VERSION ""

NS_ :

BS_:

BU_: Dummy_FO TestTool_FO LRR_FO RFSRR_FO LFSRR_FO RSRR_FO VIS_FO EOCM_F_FO

BO_ 849 F_Vision_Lane_Sense2: 7 VIS_FO
 SG_ LnSnsBurstID : 2|2@0+ (1,0) [0|3] ""  EOCM_F_FO
 SG_ LaneSensRawLatVel : 15|16@0- (6.1035E-005,0) [-1.99999488|1.999933845] "m/s"  EOCM_F_FO
 SG_ LnSnsCrvtGrdntRt : 31|16@0- (5.96E-008,0) [-0.0019529728|0.0019529132] "1/rad/s"  EOCM_F_FO
 SG_ LnSnsLnCrvtrRghtV : 0|1@0+ (1,0) [0|1] ""  EOCM_F_FO
 SG_ LnSnsLnCrvtrRght : 47|16@0- (9.53E-007,0) [-0.031227904|0.031226951] "1/m"  EOCM_F_FO

BO_ 1184 R_SRR_Object_Header: 8 RSRR_FO
 SG_ RSRRNumValidTargets : 14|4@0+ (1,0) [0|15] ""  EOCM_F_FO
 SG_ RSrrRollingCnt : 1|2@0+ (1,0) [0|3] ""  EOCM_F_FO
 SG_ RSRRModeCmdFdbk : 4|3@0+ (1,0) [0|7] ""  EOCM_F_FO
 SG_ RSrrTimeStampV : 15|1@0+ (1,0) [0|1] ""  EOCM_F_FO
 SG_ RSrrTimeStamp : 10|11@0+ (1,0) [0|2047] "ms"  EOCM_F_FO
 SG_ RSrrBurstChecksum : 55|16@0+ (1,0) [0|65535] ""  EOCM_F_FO
 SG_ RSRRSnstvFltPrsntInt : 24|1@0+ (1,0) [0|1] ""  EOCM_F_FO
 SG_ RSRRPlntAlgnInProc : 37|1@0+ (1,0) [0|1] ""  EOCM_F_FO
 SG_ RSRRMsalgnYawRt : 47|1@0+ (1,0) [0|1] ""  EOCM_F_FO
 SG_ RSRRMsalgnYawLt : 46|1@0+ (1,0) [0|1] ""  EOCM_F_FO
 SG_ RSRRMsalgnRllRt : 35|1@0+ (1,0) [0|1] ""  EOCM_F_FO
 SG_ RSRRMsalgnRllLt : 34|1@0+ (1,0) [0|1] ""  EOCM_F_FO
 SG_ RSRRMsalgnPtchUp : 32|1@0+ (1,0) [0|1] ""  EOCM_F_FO
 SG_ RSRRMsalgnPtchDn : 33|1@0+ (1,0) [0|1] ""  EOCM_F_FO
 SG_ RSRRInitDiagCmplt : 40|1@0+ (1,0) [0|1] ""  EOCM_F_FO
 SG_ RSRRHWFltPrsntInt : 25|1@0+ (1,0) [0|1] ""  EOCM_F_FO
 SG_ RSRRExtIntrfrnc : 36|1@0+ (1,0) [0|1] ""  EOCM_F_FO
 SG_ RSRRDiagSpare : 30|1@0+ (1,0) [0|1] ""  EOCM_F_FO
 SG_ RSRRCANSgnlSpvFld : 29|1@0+ (1,0) [0|1] ""  EOCM_F_FO
 SG_ RSRRCANRxErr : 28|1@0+ (1,0) [0|1] ""  EOCM_F_FO
 SG_ RSRRCANIDAddrsUnsbl : 27|1@0+ (1,0) [0|1] ""  EOCM_F_FO
 SG_ RSRRAntTngFltPrsnt : 26|1@0+ (1,0) [0|1] ""  EOCM_F_FO
 SG_ RSRRAmbTmpOutRngLw : 42|1@0+ (1,0) [0|1] ""  EOCM_F_FO
 SG_ RSRRAmbTmpOutRngHi : 41|1@0+ (1,0) [0|1] ""  EOCM_F_FO
 SG_ RSRRAlgnFltPrsnt : 39|1@0+ (1,0) [0|1] ""  EOCM_F_FO
 SG_ RSRRVltgOutRngLo : 44|1@0+ (1,0) [0|1] ""  EOCM_F_FO
 SG_ RSRRVltgOutRngHi : 43|1@0+ (1,0) [0|1] ""  EOCM_F_FO
 SG_ RSRRSvcAlgnInPrcs : 38|1@0+ (1,0) [0|1] ""  EOCM_F_FO
 SG_ RSRRSnsrBlckd : 45|1@0+ (1,0) [0|1] ""  EOCM_F_FO

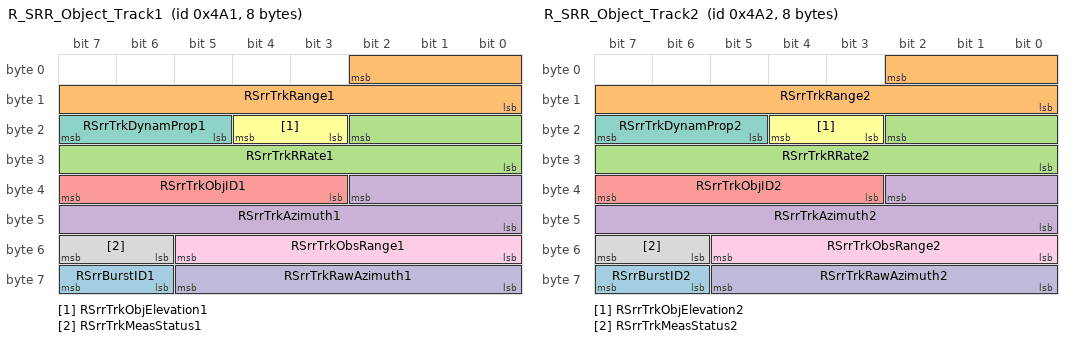
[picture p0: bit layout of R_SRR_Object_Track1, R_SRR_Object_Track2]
BO_ 1185 R_SRR_Object_Track1: 8 RSRR_FO
 SG_ RSrrBurstID1 : 63|2@0+ (1,0) [0|3] ""  EOCM_F_FO
 SG_ RSrrTrkRange1 : 2|11@0+ (0.02,0) [0|40.94] "m"  EOCM_F_FO
 SG_ RSrrTrkRRate1 : 18|11@0- (0.125,0) [-128|127.875] "m/s"  EOCM_F_FO
 SG_ RSrrTrkAzimuth1 : 34|11@0- (0.125,0) [-128|127.875] "deg"  EOCM_F_FO
 SG_ RSrrTrkObjID1 : 39|5@0+ (1,0) [0|31] ""  EOCM_F_FO
 SG_ RSrrTrkObjElevation1 : 20|2@0+ (1,0) [0|0] ""  EOCM_F_FO
 SG_ RSrrTrkDynamProp1 : 23|3@0+ (1,0) [0|0] ""  EOCM_F_FO
 SG_ RSrrTrkMeasStatus1 : 55|2@0+ (1,0) [0|0] ""  EOCM_F_FO
 SG_ RSrrTrkObsRange1 : 53|6@0- (0.02,0) [-0.64|0.62] "m"  EOCM_F_FO
 SG_ RSrrTrkRawAzimuth1 : 61|6@0- (1,0) [-32|31] "deg"  EOCM_F_FO

BO_ 1186 R_SRR_Object_Track2: 8 RSRR_FO
 SG_ RSrrBurstID2 : 63|2@0+ (1,0) [0|3] ""  EOCM_F_FO
 SG_ RSrrTrkRange2 : 2|11@0+ (0.02,0) [0|40.94] "m"  EOCM_F_FO
 SG_ RSrrTrkRRate2 : 18|11@0- (0.125,0) [-128|127.875] "m/s"  EOCM_F_FO
 SG_ RSrrTrkAzimuth2 : 34|11@0- (0.125,0) [-128|127.875] "deg"  EOCM_F_FO
 SG_ RSrrTrkObjID2 : 39|5@0+ (1,0) [0|31] ""  EOCM_F_FO
 SG_ RSrrTrkObjElevation2 : 20|2@0+ (1,0) [0|0] ""  EOCM_F_FO
 SG_ RSrrTrkDynamProp2 : 23|3@0+ (1,0) [0|0] ""  EOCM_F_FO
 SG_ RSrrTrkMeasStatus2 : 55|2@0+ (1,0) [0|0] ""  EOCM_F_FO
 SG_ RSrrTrkObsRange2 : 53|6@0- (0.02,0) [-0.64|0.62] "m"  EOCM_F_FO
 SG_ RSrrTrkRawAzimuth2 : 61|6@0- (1,0) [-32|31] "deg"  EOCM_F_FO

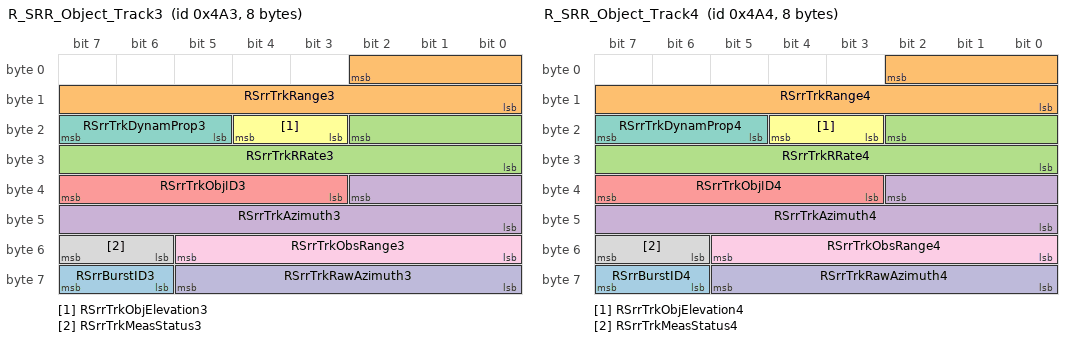
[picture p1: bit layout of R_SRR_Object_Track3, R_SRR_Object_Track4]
BO_ 1187 R_SRR_Object_Track3: 8 RSRR_FO
 SG_ RSrrBurstID3 : 63|2@0+ (1,0) [0|3] ""  EOCM_F_FO
 SG_ RSrrTrkRange3 : 2|11@0+ (0.02,0) [0|40.94] "m"  EOCM_F_FO
 SG_ RSrrTrkRRate3 : 18|11@0- (0.125,0) [-128|127.875] "m/s"  EOCM_F_FO
 SG_ RSrrTrkAzimuth3 : 34|11@0- (0.125,0) [-128|127.875] "deg"  EOCM_F_FO
 SG_ RSrrTrkObjID3 : 39|5@0+ (1,0) [0|31] ""  EOCM_F_FO
 SG_ RSrrTrkObjElevation3 : 20|2@0+ (1,0) [0|0] ""  EOCM_F_FO
 SG_ RSrrTrkDynamProp3 : 23|3@0+ (1,0) [0|0] ""  EOCM_F_FO
 SG_ RSrrTrkMeasStatus3 : 55|2@0+ (1,0) [0|0] ""  EOCM_F_FO
 SG_ RSrrTrkObsRange3 : 53|6@0- (0.02,0) [-0.64|0.62] "m"  EOCM_F_FO
 SG_ RSrrTrkRawAzimuth3 : 61|6@0- (1,0) [-32|31] "deg"  EOCM_F_FO

BO_ 1188 R_SRR_Object_Track4: 8 RSRR_FO
 SG_ RSrrBurstID4 : 63|2@0+ (1,0) [0|3] ""  EOCM_F_FO
 SG_ RSrrTrkRange4 : 2|11@0+ (0.02,0) [0|40.94] "m"  EOCM_F_FO
 SG_ RSrrTrkRRate4 : 18|11@0- (0.125,0) [-128|127.875] "m/s"  EOCM_F_FO
 SG_ RSrrTrkAzimuth4 : 34|11@0- (0.125,0) [-128|127.875] "deg"  EOCM_F_FO
 SG_ RSrrTrkObjID4 : 39|5@0+ (1,0) [0|31] ""  EOCM_F_FO
 SG_ RSrrTrkObjElevation4 : 20|2@0+ (1,0) [0|0] ""  EOCM_F_FO
 SG_ RSrrTrkDynamProp4 : 23|3@0+ (1,0) [0|0] ""  EOCM_F_FO
 SG_ RSrrTrkMeasStatus4 : 55|2@0+ (1,0) [0|0] ""  EOCM_F_FO
 SG_ RSrrTrkObsRange4 : 53|6@0- (0.02,0) [-0.64|0.62] "m"  EOCM_F_FO
 SG_ RSrrTrkRawAzimuth4 : 61|6@0- (1,0) [-32|31] "deg"  EOCM_F_FO

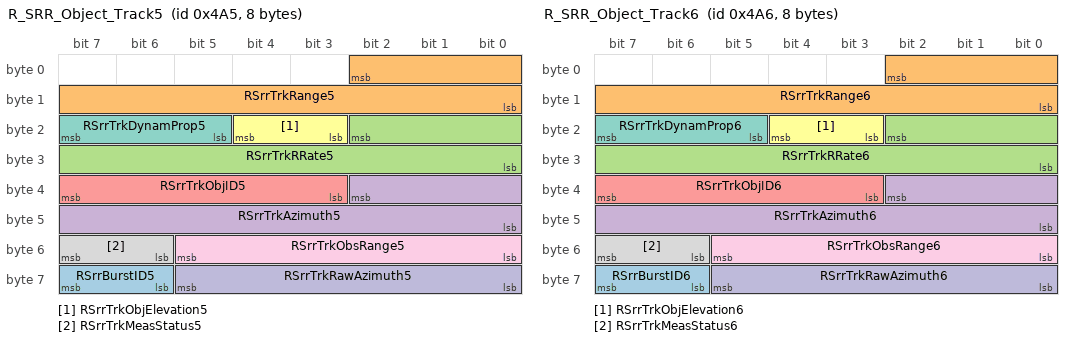
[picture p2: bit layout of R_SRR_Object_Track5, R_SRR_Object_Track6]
BO_ 1189 R_SRR_Object_Track5: 8 RSRR_FO
 SG_ RSrrBurstID5 : 63|2@0+ (1,0) [0|3] ""  EOCM_F_FO
 SG_ RSrrTrkRange5 : 2|11@0+ (0.02,0) [0|40.94] "m"  EOCM_F_FO
 SG_ RSrrTrkRRate5 : 18|11@0- (0.125,0) [-128|127.875] "m/s"  EOCM_F_FO
 SG_ RSrrTrkAzimuth5 : 34|11@0- (0.125,0) [-128|127.875] "deg"  EOCM_F_FO
 SG_ RSrrTrkObjID5 : 39|5@0+ (1,0) [0|31] ""  EOCM_F_FO
 SG_ RSrrTrkObjElevation5 : 20|2@0+ (1,0) [0|0] ""  EOCM_F_FO
 SG_ RSrrTrkDynamProp5 : 23|3@0+ (1,0) [0|0] ""  EOCM_F_FO
 SG_ RSrrTrkMeasStatus5 : 55|2@0+ (1,0) [0|0] ""  EOCM_F_FO
 SG_ RSrrTrkObsRange5 : 53|6@0- (0.02,0) [-0.64|0.62] "m"  EOCM_F_FO
 SG_ RSrrTrkRawAzimuth5 : 61|6@0- (1,0) [-32|31] "deg"  EOCM_F_FO

BO_ 1190 R_SRR_Object_Track6: 8 RSRR_FO
 SG_ RSrrBurstID6 : 63|2@0+ (1,0) [0|3] ""  EOCM_F_FO
 SG_ RSrrTrkRange6 : 2|11@0+ (0.02,0) [0|40.94] "m"  EOCM_F_FO
 SG_ RSrrTrkRRate6 : 18|11@0- (0.125,0) [-128|127.875] "m/s"  EOCM_F_FO
 SG_ RSrrTrkAzimuth6 : 34|11@0- (0.125,0) [-128|127.875] "deg"  EOCM_F_FO
 SG_ RSrrTrkObjID6 : 39|5@0+ (1,0) [0|31] ""  EOCM_F_FO
 SG_ RSrrTrkObjElevation6 : 20|2@0+ (1,0) [0|0] ""  EOCM_F_FO
 SG_ RSrrTrkDynamProp6 : 23|3@0+ (1,0) [0|0] ""  EOCM_F_FO
 SG_ RSrrTrkMeasStatus6 : 55|2@0+ (1,0) [0|0] ""  EOCM_F_FO
 SG_ RSrrTrkObsRange6 : 53|6@0- (0.02,0) [-0.64|0.62] "m"  EOCM_F_FO
 SG_ RSrrTrkRawAzimuth6 : 61|6@0- (1,0) [-32|31] "deg"  EOCM_F_FO

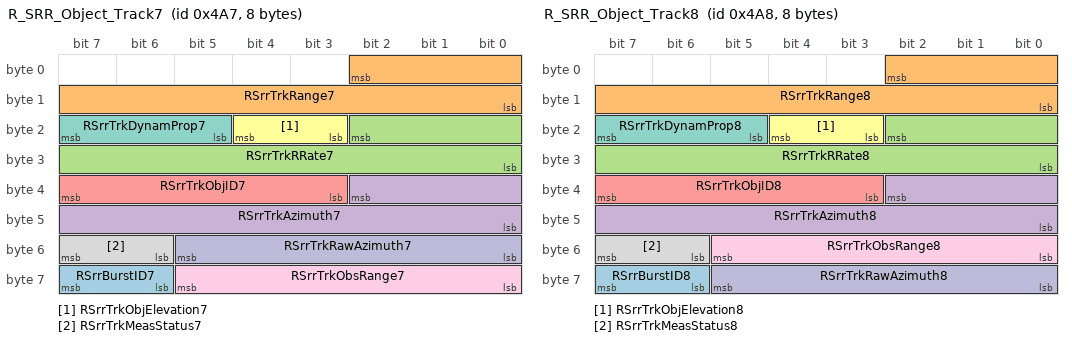
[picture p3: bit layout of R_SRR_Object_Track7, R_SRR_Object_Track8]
BO_ 1191 R_SRR_Object_Track7: 8 RSRR_FO
 SG_ RSrrBurstID7 : 63|2@0+ (1,0) [0|3] ""  EOCM_F_FO
 SG_ RSrrTrkRange7 : 2|11@0+ (0.02,0) [0|40.94] "m"  EOCM_F_FO
 SG_ RSrrTrkRRate7 : 18|11@0- (0.125,0) [-128|127.875] "m/s"  EOCM_F_FO
 SG_ RSrrTrkAzimuth7 : 34|11@0- (0.125,0) [-128|127.875] "deg"  EOCM_F_FO
 SG_ RSrrTrkObjID7 : 39|5@0+ (1,0) [0|31] ""  EOCM_F_FO
 SG_ RSrrTrkObjElevation7 : 20|2@0+ (1,0) [0|0] ""  EOCM_F_FO
 SG_ RSrrTrkDynamProp7 : 23|3@0+ (1,0) [0|0] ""  EOCM_F_FO
 SG_ RSrrTrkMeasStatus7 : 55|2@0+ (1,0) [0|0] ""  EOCM_F_FO
 SG_ RSrrTrkObsRange7 : 61|6@0- (0.02,0) [-0.64|0.62] "m"  EOCM_F_FO
 SG_ RSrrTrkRawAzimuth7 : 53|6@0- (1,0) [-32|31] "deg"  EOCM_F_FO

BO_ 1192 R_SRR_Object_Track8: 8 RSRR_FO
 SG_ RSrrBurstID8 : 63|2@0+ (1,0) [0|3] ""  EOCM_F_FO
 SG_ RSrrTrkRange8 : 2|11@0+ (0.02,0) [0|40.94] "m"  EOCM_F_FO
 SG_ RSrrTrkRRate8 : 18|11@0- (0.125,0) [-128|127.875] "m/s"  EOCM_F_FO
 SG_ RSrrTrkAzimuth8 : 34|11@0- (0.125,0) [-128|127.875] "deg"  EOCM_F_FO
 SG_ RSrrTrkObjID8 : 39|5@0+ (1,0) [0|31] ""  EOCM_F_FO
 SG_ RSrrTrkObjElevation8 : 20|2@0+ (1,0) [0|0] ""  EOCM_F_FO
 SG_ RSrrTrkDynamProp8 : 23|3@0+ (1,0) [0|0] ""  EOCM_F_FO
 SG_ RSrrTrkMeasStatus8 : 55|2@0+ (1,0) [0|0] ""  EOCM_F_FO
 SG_ RSrrTrkObsRange8 : 53|6@0- (0.02,0) [-0.64|0.62] "m"  EOCM_F_FO
 SG_ RSrrTrkRawAzimuth8 : 61|6@0- (1,0) [-32|31] "deg"  EOCM_F_FO

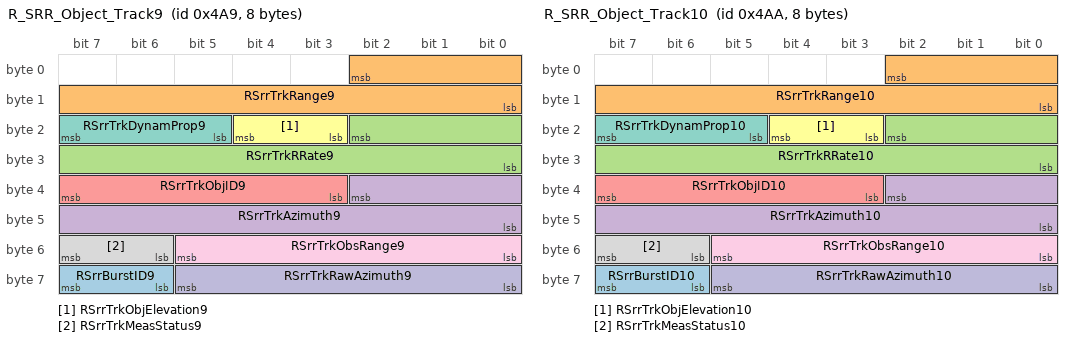
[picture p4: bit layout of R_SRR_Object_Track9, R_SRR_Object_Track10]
BO_ 1193 R_SRR_Object_Track9: 8 RSRR_FO
 SG_ RSrrBurstID9 : 63|2@0+ (1,0) [0|3] ""  EOCM_F_FO
 SG_ RSrrTrkRange9 : 2|11@0+ (0.02,0) [0|40.94] "m"  EOCM_F_FO
 SG_ RSrrTrkRRate9 : 18|11@0- (0.125,0) [-128|127.875] "m/s"  EOCM_F_FO
 SG_ RSrrTrkAzimuth9 : 34|11@0- (0.125,0) [-128|127.875] "deg"  EOCM_F_FO
 SG_ RSrrTrkObjID9 : 39|5@0+ (1,0) [0|31] ""  EOCM_F_FO
 SG_ RSrrTrkObjElevation9 : 20|2@0+ (1,0) [0|0] ""  EOCM_F_FO
 SG_ RSrrTrkDynamProp9 : 23|3@0+ (1,0) [0|0] ""  EOCM_F_FO
 SG_ RSrrTrkMeasStatus9 : 55|2@0+ (1,0) [0|0] ""  EOCM_F_FO
 SG_ RSrrTrkObsRange9 : 53|6@0- (0.02,0) [-0.64|0.62] "m"  EOCM_F_FO
 SG_ RSrrTrkRawAzimuth9 : 61|6@0- (1,0) [-32|31] "deg"  EOCM_F_FO

BO_ 1194 R_SRR_Object_Track10: 8 RSRR_FO
 SG_ RSrrBurstID10 : 63|2@0+ (1,0) [0|3] ""  EOCM_F_FO
 SG_ RSrrTrkRange10 : 2|11@0+ (0.02,0) [0|40.94] "m"  EOCM_F_FO
 SG_ RSrrTrkRRate10 : 18|11@0- (0.125,0) [-128|127.875] "m/s"  EOCM_F_FO
 SG_ RSrrTrkAzimuth10 : 34|11@0- (0.125,0) [-128|127.875] "deg"  EOCM_F_FO
 SG_ RSrrTrkObjID10 : 39|5@0+ (1,0) [0|31] ""  EOCM_F_FO
 SG_ RSrrTrkObjElevation10 : 20|2@0+ (1,0) [0|0] ""  EOCM_F_FO
 SG_ RSrrTrkDynamProp10 : 23|3@0+ (1,0) [0|0] ""  EOCM_F_FO
 SG_ RSrrTrkMeasStatus10 : 55|2@0+ (1,0) [0|0] ""  EOCM_F_FO
 SG_ RSrrTrkObsRange10 : 53|6@0- (0.02,0) [-0.64|0.62] "m"  EOCM_F_FO
 SG_ RSrrTrkRawAzimuth10 : 61|6@0- (1,0) [-32|31] "deg"  EOCM_F_FO

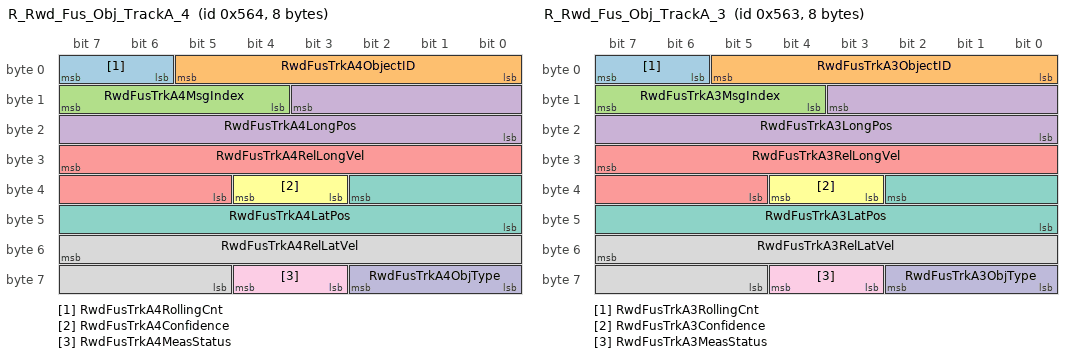
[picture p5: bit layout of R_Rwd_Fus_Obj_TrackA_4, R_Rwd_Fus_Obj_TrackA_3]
BO_ 1380 R_Rwd_Fus_Obj_TrackA_4: 8 EOCM_F_FO
 SG_ RwdFusTrkA4RollingCnt : 7|2@0+ (1,0) [0|3] ""  Dummy_FO
 SG_ RwdFusTrkA4ObjectID : 5|6@0+ (1,0) [0|63] ""  Dummy_FO
 SG_ RwdFusTrkA4MsgIndex : 15|4@0+ (1,0) [0|15] ""  Dummy_FO
 SG_ RwdFusTrkA4LongPos : 11|12@0- (0.125,0) [-256|255.875] "m"  Dummy_FO
 SG_ RwdFusTrkA4RelLongVel : 31|11@0- (0.125,0) [-128|127.875] "m/s"  Dummy_FO
 SG_ RwdFusTrkA4Confidence : 36|2@0+ (1,0) [0|3] ""  Dummy_FO
 SG_ RwdFusTrkA4LatPos : 34|11@0- (0.125,0) [-128|127.875] "m"  Dummy_FO
 SG_ RwdFusTrkA4RelLatVel : 55|11@0- (0.125,0) [-128|127.875] "m/s"  Dummy_FO
 SG_ RwdFusTrkA4MeasStatus : 60|2@0+ (1,0) [0|3] ""  Dummy_FO
 SG_ RwdFusTrkA4ObjType : 58|3@0+ (1,0) [0|7] ""  Dummy_FO

BO_ 1379 R_Rwd_Fus_Obj_TrackA_3: 8 EOCM_F_FO
 SG_ RwdFusTrkA3RollingCnt : 7|2@0+ (1,0) [0|3] ""  Dummy_FO
 SG_ RwdFusTrkA3ObjectID : 5|6@0+ (1,0) [0|63] ""  Dummy_FO
 SG_ RwdFusTrkA3MsgIndex : 15|4@0+ (1,0) [0|15] ""  Dummy_FO
 SG_ RwdFusTrkA3LongPos : 11|12@0- (0.125,0) [-256|255.875] "m"  Dummy_FO
 SG_ RwdFusTrkA3RelLongVel : 31|11@0- (0.125,0) [-128|127.875] "m/s"  Dummy_FO
 SG_ RwdFusTrkA3Confidence : 36|2@0+ (1,0) [0|3] ""  Dummy_FO
 SG_ RwdFusTrkA3LatPos : 34|11@0- (0.125,0) [-128|127.875] "m"  Dummy_FO
 SG_ RwdFusTrkA3RelLatVel : 55|11@0- (0.125,0) [-128|127.875] "m/s"  Dummy_FO
 SG_ RwdFusTrkA3MeasStatus : 60|2@0+ (1,0) [0|3] ""  Dummy_FO
 SG_ RwdFusTrkA3ObjType : 58|3@0+ (1,0) [0|7] ""  Dummy_FO

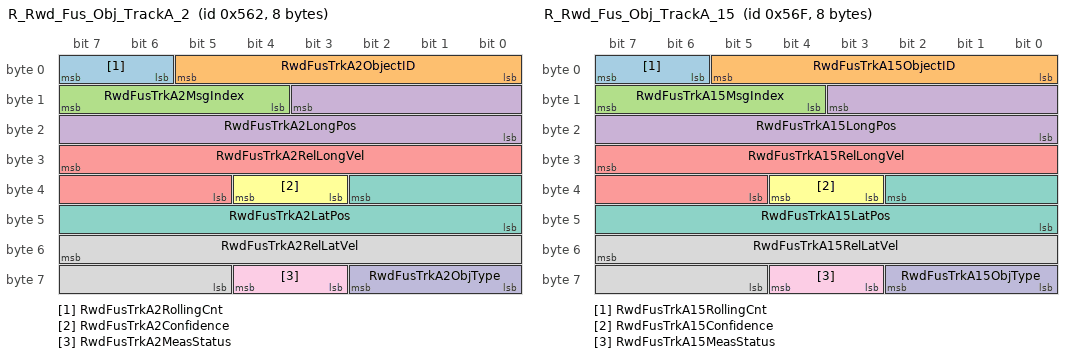
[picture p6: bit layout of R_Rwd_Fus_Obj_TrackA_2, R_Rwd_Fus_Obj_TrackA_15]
BO_ 1378 R_Rwd_Fus_Obj_TrackA_2: 8 EOCM_F_FO
 SG_ RwdFusTrkA2RollingCnt : 7|2@0+ (1,0) [0|3] ""  Dummy_FO
 SG_ RwdFusTrkA2ObjectID : 5|6@0+ (1,0) [0|63] ""  Dummy_FO
 SG_ RwdFusTrkA2MsgIndex : 15|4@0+ (1,0) [0|15] ""  Dummy_FO
 SG_ RwdFusTrkA2LongPos : 11|12@0- (0.125,0) [-256|255.875] "m"  Dummy_FO
 SG_ RwdFusTrkA2RelLongVel : 31|11@0- (0.125,0) [-128|127.875] "m/s"  Dummy_FO
 SG_ RwdFusTrkA2Confidence : 36|2@0+ (1,0) [0|3] ""  Dummy_FO
 SG_ RwdFusTrkA2LatPos : 34|11@0- (0.125,0) [-128|127.875] "m"  Dummy_FO
 SG_ RwdFusTrkA2RelLatVel : 55|11@0- (0.125,0) [-128|127.875] "m/s"  Dummy_FO
 SG_ RwdFusTrkA2MeasStatus : 60|2@0+ (1,0) [0|3] ""  Dummy_FO
 SG_ RwdFusTrkA2ObjType : 58|3@0+ (1,0) [0|7] ""  Dummy_FO

BO_ 1391 R_Rwd_Fus_Obj_TrackA_15: 8 EOCM_F_FO
 SG_ RwdFusTrkA15RollingCnt : 7|2@0+ (1,0) [0|3] ""  Dummy_FO
 SG_ RwdFusTrkA15ObjectID : 5|6@0+ (1,0) [0|63] ""  Dummy_FO
 SG_ RwdFusTrkA15MsgIndex : 15|4@0+ (1,0) [0|15] ""  Dummy_FO
 SG_ RwdFusTrkA15LongPos : 11|12@0- (0.125,0) [-256|255.875] "m"  Dummy_FO
 SG_ RwdFusTrkA15RelLongVel : 31|11@0- (0.125,0) [-128|127.875] "m/s"  Dummy_FO
 SG_ RwdFusTrkA15Confidence : 36|2@0+ (1,0) [0|3] ""  Dummy_FO
 SG_ RwdFusTrkA15LatPos : 34|11@0- (0.125,0) [-128|127.875] "m"  Dummy_FO
 SG_ RwdFusTrkA15RelLatVel : 55|11@0- (0.125,0) [-128|127.875] "m/s"  Dummy_FO
 SG_ RwdFusTrkA15MeasStatus : 60|2@0+ (1,0) [0|3] ""  Dummy_FO
 SG_ RwdFusTrkA15ObjType : 58|3@0+ (1,0) [0|7] ""  Dummy_FO

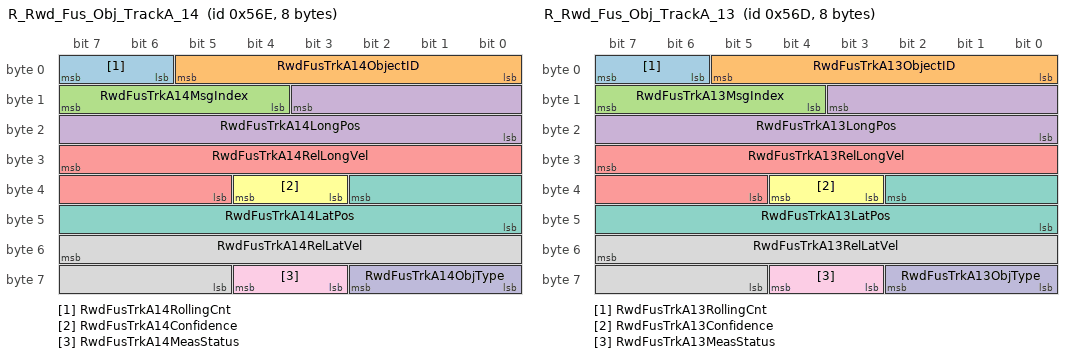
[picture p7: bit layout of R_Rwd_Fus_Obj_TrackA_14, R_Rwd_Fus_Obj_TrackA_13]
BO_ 1390 R_Rwd_Fus_Obj_TrackA_14: 8 EOCM_F_FO
 SG_ RwdFusTrkA14RollingCnt : 7|2@0+ (1,0) [0|3] ""  Dummy_FO
 SG_ RwdFusTrkA14ObjectID : 5|6@0+ (1,0) [0|63] ""  Dummy_FO
 SG_ RwdFusTrkA14MsgIndex : 15|4@0+ (1,0) [0|15] ""  Dummy_FO
 SG_ RwdFusTrkA14LongPos : 11|12@0- (0.125,0) [-256|255.875] "m"  Dummy_FO
 SG_ RwdFusTrkA14RelLongVel : 31|11@0- (0.125,0) [-128|127.875] "m/s"  Dummy_FO
 SG_ RwdFusTrkA14Confidence : 36|2@0+ (1,0) [0|3] ""  Dummy_FO
 SG_ RwdFusTrkA14LatPos : 34|11@0- (0.125,0) [-128|127.875] "m"  Dummy_FO
 SG_ RwdFusTrkA14RelLatVel : 55|11@0- (0.125,0) [-128|127.875] "m/s"  Dummy_FO
 SG_ RwdFusTrkA14MeasStatus : 60|2@0+ (1,0) [0|3] ""  Dummy_FO
 SG_ RwdFusTrkA14ObjType : 58|3@0+ (1,0) [0|7] ""  Dummy_FO

BO_ 1389 R_Rwd_Fus_Obj_TrackA_13: 8 EOCM_F_FO
 SG_ RwdFusTrkA13RollingCnt : 7|2@0+ (1,0) [0|3] ""  Dummy_FO
 SG_ RwdFusTrkA13ObjectID : 5|6@0+ (1,0) [0|63] ""  Dummy_FO
 SG_ RwdFusTrkA13MsgIndex : 15|4@0+ (1,0) [0|15] ""  Dummy_FO
 SG_ RwdFusTrkA13LongPos : 11|12@0- (0.125,0) [-256|255.875] "m"  Dummy_FO
 SG_ RwdFusTrkA13RelLongVel : 31|11@0- (0.125,0) [-128|127.875] "m/s"  Dummy_FO
 SG_ RwdFusTrkA13Confidence : 36|2@0+ (1,0) [0|3] ""  Dummy_FO
 SG_ RwdFusTrkA13LatPos : 34|11@0- (0.125,0) [-128|127.875] "m"  Dummy_FO
 SG_ RwdFusTrkA13RelLatVel : 55|11@0- (0.125,0) [-128|127.875] "m/s"  Dummy_FO
 SG_ RwdFusTrkA13MeasStatus : 60|2@0+ (1,0) [0|3] ""  Dummy_FO
 SG_ RwdFusTrkA13ObjType : 58|3@0+ (1,0) [0|7] ""  Dummy_FO

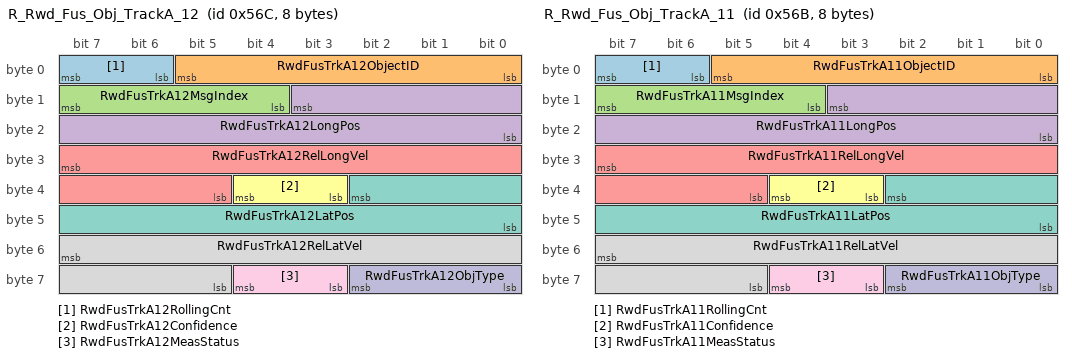
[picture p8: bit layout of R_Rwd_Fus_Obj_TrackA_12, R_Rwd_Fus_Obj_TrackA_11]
BO_ 1388 R_Rwd_Fus_Obj_TrackA_12: 8 EOCM_F_FO
 SG_ RwdFusTrkA12RollingCnt : 7|2@0+ (1,0) [0|3] ""  Dummy_FO
 SG_ RwdFusTrkA12ObjectID : 5|6@0+ (1,0) [0|63] ""  Dummy_FO
 SG_ RwdFusTrkA12MsgIndex : 15|4@0+ (1,0) [0|15] ""  Dummy_FO
 SG_ RwdFusTrkA12LongPos : 11|12@0- (0.125,0) [-256|255.875] "m"  Dummy_FO
 SG_ RwdFusTrkA12RelLongVel : 31|11@0- (0.125,0) [-128|127.875] "m/s"  Dummy_FO
 SG_ RwdFusTrkA12Confidence : 36|2@0+ (1,0) [0|3] ""  Dummy_FO
 SG_ RwdFusTrkA12LatPos : 34|11@0- (0.125,0) [-128|127.875] "m"  Dummy_FO
 SG_ RwdFusTrkA12RelLatVel : 55|11@0- (0.125,0) [-128|127.875] "m/s"  Dummy_FO
 SG_ RwdFusTrkA12MeasStatus : 60|2@0+ (1,0) [0|3] ""  Dummy_FO
 SG_ RwdFusTrkA12ObjType : 58|3@0+ (1,0) [0|7] ""  Dummy_FO

BO_ 1387 R_Rwd_Fus_Obj_TrackA_11: 8 EOCM_F_FO
 SG_ RwdFusTrkA11RollingCnt : 7|2@0+ (1,0) [0|3] ""  Dummy_FO
 SG_ RwdFusTrkA11ObjectID : 5|6@0+ (1,0) [0|63] ""  Dummy_FO
 SG_ RwdFusTrkA11MsgIndex : 15|4@0+ (1,0) [0|15] ""  Dummy_FO
 SG_ RwdFusTrkA11LongPos : 11|12@0- (0.125,0) [-256|255.875] "m"  Dummy_FO
 SG_ RwdFusTrkA11RelLongVel : 31|11@0- (0.125,0) [-128|127.875] "m/s"  Dummy_FO
 SG_ RwdFusTrkA11Confidence : 36|2@0+ (1,0) [0|3] ""  Dummy_FO
 SG_ RwdFusTrkA11LatPos : 34|11@0- (0.125,0) [-128|127.875] "m"  Dummy_FO
 SG_ RwdFusTrkA11RelLatVel : 55|11@0- (0.125,0) [-128|127.875] "m/s"  Dummy_FO
 SG_ RwdFusTrkA11MeasStatus : 60|2@0+ (1,0) [0|3] ""  Dummy_FO
 SG_ RwdFusTrkA11ObjType : 58|3@0+ (1,0) [0|7] ""  Dummy_FO

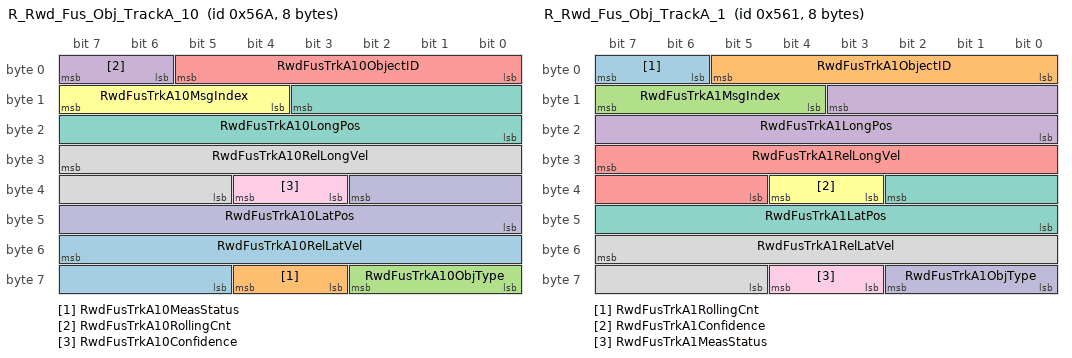
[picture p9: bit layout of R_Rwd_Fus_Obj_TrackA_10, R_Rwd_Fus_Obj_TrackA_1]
BO_ 1386 R_Rwd_Fus_Obj_TrackA_10: 8 EOCM_F_FO
 SG_ RwdFusTrkA10RelLatVel : 55|11@0- (0.125,0) [-128|127.875] "m/s"  Dummy_FO
 SG_ RwdFusTrkA10MeasStatus : 60|2@0+ (1,0) [0|3] ""  Dummy_FO
 SG_ RwdFusTrkA10ObjType : 58|3@0+ (1,0) [0|7] ""  Dummy_FO
 SG_ RwdFusTrkA10RollingCnt : 7|2@0+ (1,0) [0|3] ""  Dummy_FO
 SG_ RwdFusTrkA10ObjectID : 5|6@0+ (1,0) [0|63] ""  Dummy_FO
 SG_ RwdFusTrkA10MsgIndex : 15|4@0+ (1,0) [0|15] ""  Dummy_FO
 SG_ RwdFusTrkA10LongPos : 11|12@0- (0.125,0) [-256|255.875] "m"  Dummy_FO
 SG_ RwdFusTrkA10RelLongVel : 31|11@0- (0.125,0) [-128|127.875] "m/s"  Dummy_FO
 SG_ RwdFusTrkA10Confidence : 36|2@0+ (1,0) [0|3] ""  Dummy_FO
 SG_ RwdFusTrkA10LatPos : 34|11@0- (0.125,0) [-128|127.875] "m"  Dummy_FO

BO_ 1377 R_Rwd_Fus_Obj_TrackA_1: 8 EOCM_F_FO
 SG_ RwdFusTrkA1RollingCnt : 7|2@0+ (1,0) [0|3] ""  Dummy_FO
 SG_ RwdFusTrkA1ObjectID : 5|6@0+ (1,0) [0|63] ""  Dummy_FO
 SG_ RwdFusTrkA1MsgIndex : 15|4@0+ (1,0) [0|15] ""  Dummy_FO
 SG_ RwdFusTrkA1LongPos : 11|12@0- (0.125,0) [-256|255.875] "m"  Dummy_FO
 SG_ RwdFusTrkA1RelLongVel : 31|11@0- (0.125,0) [-128|127.875] "m/s"  Dummy_FO
 SG_ RwdFusTrkA1Confidence : 36|2@0+ (1,0) [0|3] ""  Dummy_FO
 SG_ RwdFusTrkA1LatPos : 34|11@0- (0.125,0) [-128|127.875] "m"  Dummy_FO
 SG_ RwdFusTrkA1RelLatVel : 55|11@0- (0.125,0) [-128|127.875] "m/s"  Dummy_FO
 SG_ RwdFusTrkA1MeasStatus : 60|2@0+ (1,0) [0|3] ""  Dummy_FO
 SG_ RwdFusTrkA1ObjType : 58|3@0+ (1,0) [0|7] ""  Dummy_FO

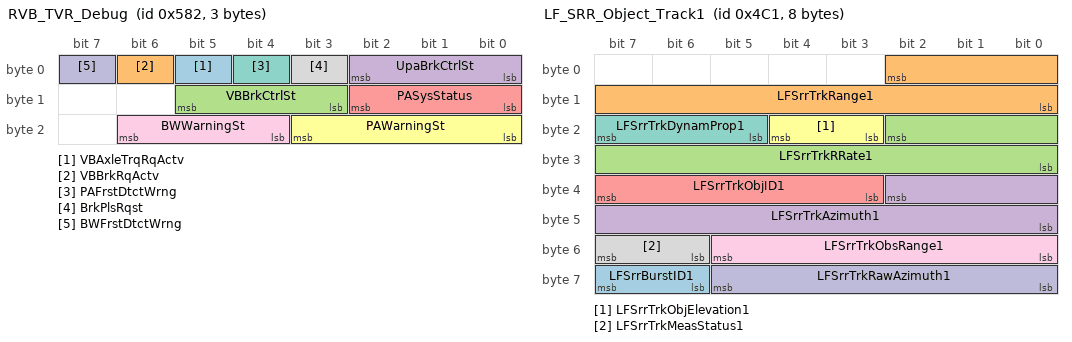
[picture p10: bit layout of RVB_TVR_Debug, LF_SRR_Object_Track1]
BO_ 1410 RVB_TVR_Debug: 3 EOCM_F_FO
 SG_ VBAxleTrqRqActv : 5|1@0+ (1,0) [0|1] ""  Dummy_FO
 SG_ VBBrkRqActv : 6|1@0+ (1,0) [0|1] ""  Dummy_FO
 SG_ VBBrkCtrlSt : 13|3@0+ (1,0) [0|0] ""  Dummy_FO
 SG_ UpaBrkCtrlSt : 2|3@0+ (1,0) [0|0] ""  Dummy_FO
 SG_ PASysStatus : 10|3@0+ (1,0) [0|0] ""  Dummy_FO
 SG_ PAWarningSt : 19|4@0+ (1,0) [0|0] ""  Dummy_FO
 SG_ PAFrstDtctWrng : 4|1@0+ (1,0) [0|1] ""  Dummy_FO
 SG_ BrkPlsRqst : 3|1@0+ (1,0) [0|1] ""  Dummy_FO
 SG_ BWWarningSt : 22|3@0+ (1,0) [0|0] ""  Dummy_FO
 SG_ BWFrstDtctWrng : 7|1@0+ (1,0) [0|1] ""  Dummy_FO

BO_ 1216 LF_SRR_Object_Header: 8 LFSRR_FO
 SG_ LFSRRNumValidTargets : 14|4@0+ (1,0) [0|15] ""  EOCM_F_FO
 SG_ LFSrrRollingCnt : 1|2@0+ (1,0) [0|3] ""  EOCM_F_FO
 SG_ LFSRRModeCmdFdbk : 4|3@0+ (1,0) [0|7] ""  EOCM_F_FO
 SG_ LFSrrTimeStampV : 15|1@0+ (1,0) [0|1] ""  EOCM_F_FO
 SG_ LFSrrTimeStamp : 10|11@0+ (1,0) [0|2047] "ms"  EOCM_F_FO
 SG_ LFSrrBurstChecksum : 55|16@0+ (1,0) [0|65535] ""  EOCM_F_FO
 SG_ LFSRRVltgOutRngLo : 44|1@0+ (1,0) [0|1] ""  EOCM_F_FO
 SG_ LFSRRVltgOutRngHi : 43|1@0+ (1,0) [0|1] ""  EOCM_F_FO
 SG_ LFSRRSvcAlgnInPrcs : 38|1@0+ (1,0) [0|1] ""  EOCM_F_FO
 SG_ LFSRRSnsrBlckd : 45|1@0+ (1,0) [0|1] ""  EOCM_F_FO
 SG_ LFSRRSnstvFltPrsntInt : 24|1@0+ (1,0) [0|1] ""  EOCM_F_FO
 SG_ LFSRRPlntAlgnInProc : 37|1@0+ (1,0) [0|1] ""  EOCM_F_FO
 SG_ LFSRRMsalgnYawRt : 47|1@0+ (1,0) [0|1] ""  EOCM_F_FO
 SG_ LFSRRMsalgnYawLt : 46|1@0+ (1,0) [0|1] ""  EOCM_F_FO
 SG_ LFSRRMsalgnRllRt : 35|1@0+ (1,0) [0|1] ""  EOCM_F_FO
 SG_ LFSRRMsalgnRllLt : 34|1@0+ (1,0) [0|1] ""  EOCM_F_FO
 SG_ LFSRRMsalgnPtchUp : 32|1@0+ (1,0) [0|1] ""  EOCM_F_FO
 SG_ LFSRRMsalgnPtchDn : 33|1@0+ (1,0) [0|1] ""  EOCM_F_FO
 SG_ LFSRRInitDiagCmplt : 40|1@0+ (1,0) [0|1] ""  EOCM_F_FO
 SG_ LFSRRHWFltPrsntInt : 25|1@0+ (1,0) [0|1] ""  EOCM_F_FO
 SG_ LFSRRExtIntrfrnc : 36|1@0+ (1,0) [0|1] ""  EOCM_F_FO
 SG_ LFSRRDiagSpare : 30|1@0+ (1,0) [0|1] ""  EOCM_F_FO
 SG_ LFSRRCANSgnlSpvFld : 29|1@0+ (1,0) [0|1] ""  EOCM_F_FO
 SG_ LFSRRCANRxErr : 28|1@0+ (1,0) [0|1] ""  EOCM_F_FO
 SG_ LFSRRCANIDAddrsUnsbl : 27|1@0+ (1,0) [0|1] ""  EOCM_F_FO
 SG_ LFSRRAntTngFltPrsnt : 26|1@0+ (1,0) [0|1] ""  EOCM_F_FO
 SG_ LFSRRAmbTmpOutRngLw : 42|1@0+ (1,0) [0|1] ""  EOCM_F_FO
 SG_ LFSRRAmbTmpOutRngHi : 41|1@0+ (1,0) [0|1] ""  EOCM_F_FO
 SG_ LFSRRAlgnFltPrsnt : 39|1@0+ (1,0) [0|1] ""  EOCM_F_FO

BO_ 1217 LF_SRR_Object_Track1: 8 LFSRR_FO
 SG_ LFSrrBurstID1 : 63|2@0+ (1,0) [0|3] ""  EOCM_F_FO
 SG_ LFSrrTrkRange1 : 2|11@0+ (0.02,0) [0|40.94] "m"  EOCM_F_FO
 SG_ LFSrrTrkRRate1 : 18|11@0- (0.125,0) [-128|127.875] "m/s"  EOCM_F_FO
 SG_ LFSrrTrkAzimuth1 : 34|11@0- (0.125,0) [-128|127.875] "deg"  EOCM_F_FO
 SG_ LFSrrTrkObjID1 : 39|5@0+ (1,0) [0|31] ""  EOCM_F_FO
 SG_ LFSrrTrkObjElevation1 : 20|2@0+ (1,0) [0|0] ""  EOCM_F_FO
 SG_ LFSrrTrkDynamProp1 : 23|3@0+ (1,0) [0|0] ""  EOCM_F_FO
 SG_ LFSrrTrkMeasStatus1 : 55|2@0+ (1,0) [0|0] ""  EOCM_F_FO
 SG_ LFSrrTrkObsRange1 : 53|6@0- (0.02,0) [-0.64|0.62] "m"  EOCM_F_FO
 SG_ LFSrrTrkRawAzimuth1 : 61|6@0- (1,0) [-32|31] "deg"  EOCM_F_FO

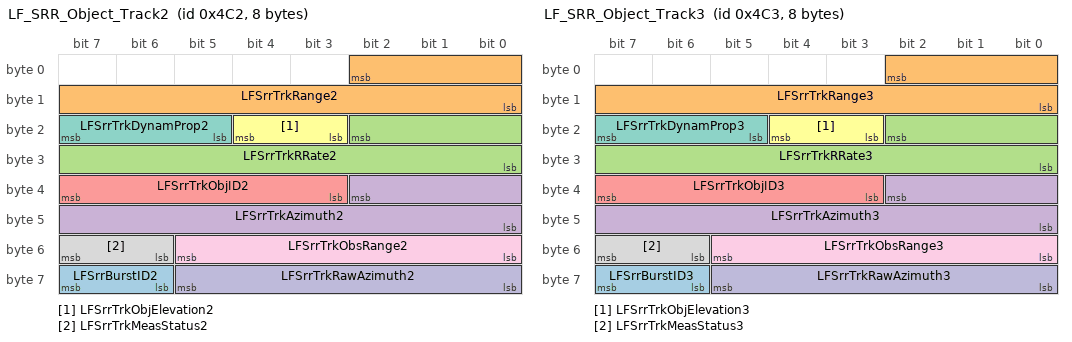
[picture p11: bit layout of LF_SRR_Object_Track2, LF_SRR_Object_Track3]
BO_ 1218 LF_SRR_Object_Track2: 8 LFSRR_FO
 SG_ LFSrrBurstID2 : 63|2@0+ (1,0) [0|3] ""  EOCM_F_FO
 SG_ LFSrrTrkRange2 : 2|11@0+ (0.02,0) [0|40.94] "m"  EOCM_F_FO
 SG_ LFSrrTrkRRate2 : 18|11@0- (0.125,0) [-128|127.875] "m/s"  EOCM_F_FO
 SG_ LFSrrTrkAzimuth2 : 34|11@0- (0.125,0) [-128|127.875] "deg"  EOCM_F_FO
 SG_ LFSrrTrkObjID2 : 39|5@0+ (1,0) [0|31] ""  EOCM_F_FO
 SG_ LFSrrTrkObjElevation2 : 20|2@0+ (1,0) [0|0] ""  EOCM_F_FO
 SG_ LFSrrTrkDynamProp2 : 23|3@0+ (1,0) [0|0] ""  EOCM_F_FO
 SG_ LFSrrTrkMeasStatus2 : 55|2@0+ (1,0) [0|0] ""  EOCM_F_FO
 SG_ LFSrrTrkObsRange2 : 53|6@0- (0.02,0) [-0.64|0.62] "m"  EOCM_F_FO
 SG_ LFSrrTrkRawAzimuth2 : 61|6@0- (1,0) [-32|31] "deg"  EOCM_F_FO

BO_ 1219 LF_SRR_Object_Track3: 8 LFSRR_FO
 SG_ LFSrrBurstID3 : 63|2@0+ (1,0) [0|3] ""  EOCM_F_FO
 SG_ LFSrrTrkRange3 : 2|11@0+ (0.02,0) [0|40.94] "m"  EOCM_F_FO
 SG_ LFSrrTrkRRate3 : 18|11@0- (0.125,0) [-128|127.875] "m/s"  EOCM_F_FO
 SG_ LFSrrTrkAzimuth3 : 34|11@0- (0.125,0) [-128|127.875] "deg"  EOCM_F_FO
 SG_ LFSrrTrkObjID3 : 39|5@0+ (1,0) [0|31] ""  EOCM_F_FO
 SG_ LFSrrTrkObjElevation3 : 20|2@0+ (1,0) [0|0] ""  EOCM_F_FO
 SG_ LFSrrTrkDynamProp3 : 23|3@0+ (1,0) [0|0] ""  EOCM_F_FO
 SG_ LFSrrTrkMeasStatus3 : 55|2@0+ (1,0) [0|0] ""  EOCM_F_FO
 SG_ LFSrrTrkObsRange3 : 53|6@0- (0.02,0) [-0.64|0.62] "m"  EOCM_F_FO
 SG_ LFSrrTrkRawAzimuth3 : 61|6@0- (1,0) [-32|31] "deg"  EOCM_F_FO

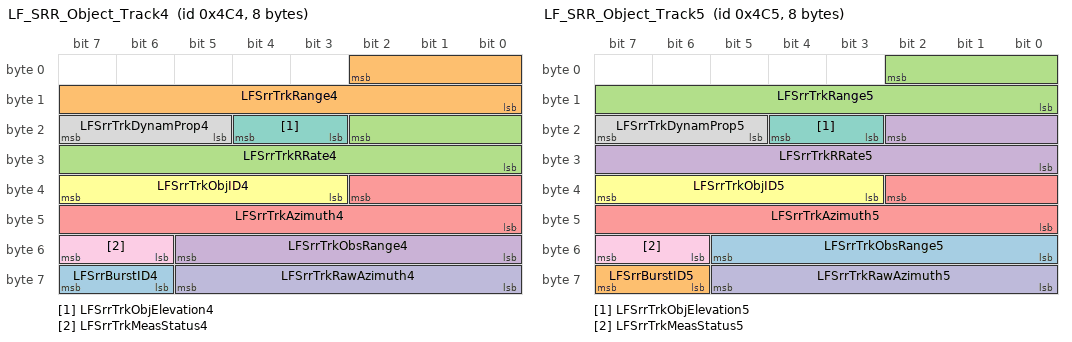
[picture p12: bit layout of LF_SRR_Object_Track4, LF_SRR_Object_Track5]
BO_ 1220 LF_SRR_Object_Track4: 8 LFSRR_FO
 SG_ LFSrrBurstID4 : 63|2@0+ (1,0) [0|3] ""  EOCM_F_FO
 SG_ LFSrrTrkRange4 : 2|11@0+ (0.02,0) [0|40.94] "m"  EOCM_F_FO
 SG_ LFSrrTrkRRate4 : 18|11@0- (0.125,0) [-128|127.875] "m/s"  EOCM_F_FO
 SG_ LFSrrTrkObsRange4 : 53|6@0- (0.02,0) [-0.64|0.62] "m"  EOCM_F_FO
 SG_ LFSrrTrkAzimuth4 : 34|11@0- (0.125,0) [-128|127.875] "deg"  EOCM_F_FO
 SG_ LFSrrTrkObjID4 : 39|5@0+ (1,0) [0|31] ""  EOCM_F_FO
 SG_ LFSrrTrkObjElevation4 : 20|2@0+ (1,0) [0|0] ""  EOCM_F_FO
 SG_ LFSrrTrkDynamProp4 : 23|3@0+ (1,0) [0|0] ""  EOCM_F_FO
 SG_ LFSrrTrkMeasStatus4 : 55|2@0+ (1,0) [0|0] ""  EOCM_F_FO
 SG_ LFSrrTrkRawAzimuth4 : 61|6@0- (1,0) [-32|31] "deg"  EOCM_F_FO

BO_ 1221 LF_SRR_Object_Track5: 8 LFSRR_FO
 SG_ LFSrrTrkObsRange5 : 53|6@0- (0.02,0) [-0.64|0.62] "m"  EOCM_F_FO
 SG_ LFSrrBurstID5 : 63|2@0+ (1,0) [0|3] ""  EOCM_F_FO
 SG_ LFSrrTrkRange5 : 2|11@0+ (0.02,0) [0|40.94] "m"  EOCM_F_FO
 SG_ LFSrrTrkRRate5 : 18|11@0- (0.125,0) [-128|127.875] "m/s"  EOCM_F_FO
 SG_ LFSrrTrkAzimuth5 : 34|11@0- (0.125,0) [-128|127.875] "deg"  EOCM_F_FO
 SG_ LFSrrTrkObjID5 : 39|5@0+ (1,0) [0|31] ""  EOCM_F_FO
 SG_ LFSrrTrkObjElevation5 : 20|2@0+ (1,0) [0|0] ""  EOCM_F_FO
 SG_ LFSrrTrkDynamProp5 : 23|3@0+ (1,0) [0|0] ""  EOCM_F_FO
 SG_ LFSrrTrkMeasStatus5 : 55|2@0+ (1,0) [0|0] ""  EOCM_F_FO
 SG_ LFSrrTrkRawAzimuth5 : 61|6@0- (1,0) [-32|31] "deg"  EOCM_F_FO

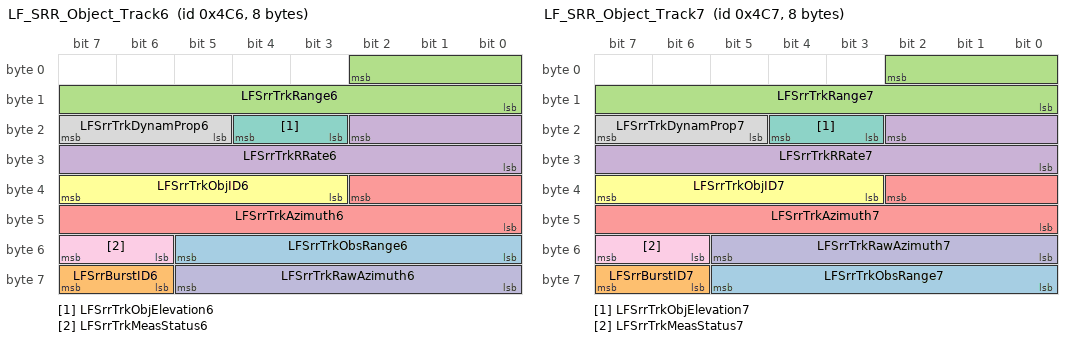
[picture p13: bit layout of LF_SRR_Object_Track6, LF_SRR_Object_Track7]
BO_ 1222 LF_SRR_Object_Track6: 8 LFSRR_FO
 SG_ LFSrrTrkObsRange6 : 53|6@0- (0.02,0) [-0.64|0.62] "m"  EOCM_F_FO
 SG_ LFSrrBurstID6 : 63|2@0+ (1,0) [0|3] ""  EOCM_F_FO
 SG_ LFSrrTrkRange6 : 2|11@0+ (0.02,0) [0|40.94] "m"  EOCM_F_FO
 SG_ LFSrrTrkRRate6 : 18|11@0- (0.125,0) [-128|127.875] "m/s"  EOCM_F_FO
 SG_ LFSrrTrkAzimuth6 : 34|11@0- (0.125,0) [-128|127.875] "deg"  EOCM_F_FO
 SG_ LFSrrTrkObjID6 : 39|5@0+ (1,0) [0|31] ""  EOCM_F_FO
 SG_ LFSrrTrkObjElevation6 : 20|2@0+ (1,0) [0|0] ""  EOCM_F_FO
 SG_ LFSrrTrkDynamProp6 : 23|3@0+ (1,0) [0|0] ""  EOCM_F_FO
 SG_ LFSrrTrkMeasStatus6 : 55|2@0+ (1,0) [0|0] ""  EOCM_F_FO
 SG_ LFSrrTrkRawAzimuth6 : 61|6@0- (1,0) [-32|31] "deg"  EOCM_F_FO

BO_ 1223 LF_SRR_Object_Track7: 8 LFSRR_FO
 SG_ LFSrrTrkObsRange7 : 61|6@0- (0.02,0) [-0.64|0.62] "m"  EOCM_F_FO
 SG_ LFSrrBurstID7 : 63|2@0+ (1,0) [0|3] ""  EOCM_F_FO
 SG_ LFSrrTrkRange7 : 2|11@0+ (0.02,0) [0|40.94] "m"  EOCM_F_FO
 SG_ LFSrrTrkRRate7 : 18|11@0- (0.125,0) [-128|127.875] "m/s"  EOCM_F_FO
 SG_ LFSrrTrkAzimuth7 : 34|11@0- (0.125,0) [-128|127.875] "deg"  EOCM_F_FO
 SG_ LFSrrTrkObjID7 : 39|5@0+ (1,0) [0|31] ""  EOCM_F_FO
 SG_ LFSrrTrkObjElevation7 : 20|2@0+ (1,0) [0|0] ""  EOCM_F_FO
 SG_ LFSrrTrkDynamProp7 : 23|3@0+ (1,0) [0|0] ""  EOCM_F_FO
 SG_ LFSrrTrkMeasStatus7 : 55|2@0+ (1,0) [0|0] ""  EOCM_F_FO
 SG_ LFSrrTrkRawAzimuth7 : 53|6@0- (1,0) [-32|31] "deg"  EOCM_F_FO

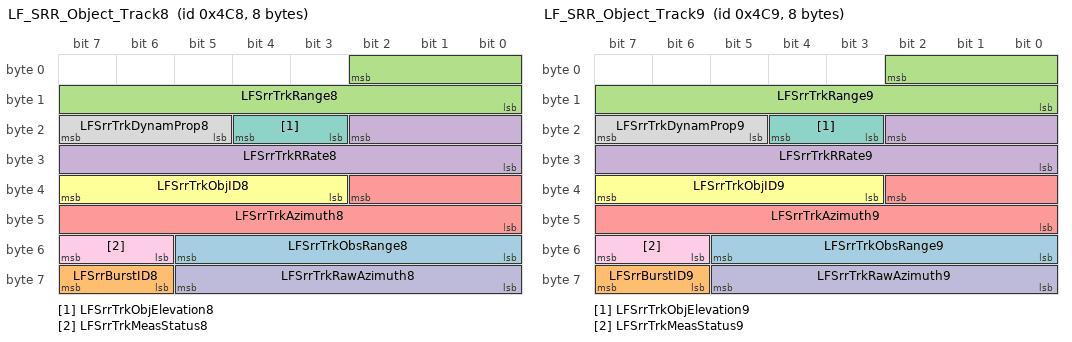
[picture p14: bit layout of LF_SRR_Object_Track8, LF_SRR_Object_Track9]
BO_ 1224 LF_SRR_Object_Track8: 8 LFSRR_FO
 SG_ LFSrrTrkObsRange8 : 53|6@0- (0.02,0) [-0.64|0.62] "m"  EOCM_F_FO
 SG_ LFSrrBurstID8 : 63|2@0+ (1,0) [0|3] ""  EOCM_F_FO
 SG_ LFSrrTrkRange8 : 2|11@0+ (0.02,0) [0|40.94] "m"  EOCM_F_FO
 SG_ LFSrrTrkRRate8 : 18|11@0- (0.125,0) [-128|127.875] "m/s"  EOCM_F_FO
 SG_ LFSrrTrkAzimuth8 : 34|11@0- (0.125,0) [-128|127.875] "deg"  EOCM_F_FO
 SG_ LFSrrTrkObjID8 : 39|5@0+ (1,0) [0|31] ""  EOCM_F_FO
 SG_ LFSrrTrkObjElevation8 : 20|2@0+ (1,0) [0|0] ""  EOCM_F_FO
 SG_ LFSrrTrkDynamProp8 : 23|3@0+ (1,0) [0|0] ""  EOCM_F_FO
 SG_ LFSrrTrkMeasStatus8 : 55|2@0+ (1,0) [0|0] ""  EOCM_F_FO
 SG_ LFSrrTrkRawAzimuth8 : 61|6@0- (1,0) [-32|31] "deg"  EOCM_F_FO

BO_ 1225 LF_SRR_Object_Track9: 8 LFSRR_FO
 SG_ LFSrrTrkObsRange9 : 53|6@0- (0.02,0) [-0.64|0.62] "m"  EOCM_F_FO
 SG_ LFSrrBurstID9 : 63|2@0+ (1,0) [0|3] ""  EOCM_F_FO
 SG_ LFSrrTrkRange9 : 2|11@0+ (0.02,0) [0|40.94] "m"  EOCM_F_FO
 SG_ LFSrrTrkRRate9 : 18|11@0- (0.125,0) [-128|127.875] "m/s"  EOCM_F_FO
 SG_ LFSrrTrkAzimuth9 : 34|11@0- (0.125,0) [-128|127.875] "deg"  EOCM_F_FO
 SG_ LFSrrTrkObjID9 : 39|5@0+ (1,0) [0|31] ""  EOCM_F_FO
 SG_ LFSrrTrkObjElevation9 : 20|2@0+ (1,0) [0|0] ""  EOCM_F_FO
 SG_ LFSrrTrkDynamProp9 : 23|3@0+ (1,0) [0|0] ""  EOCM_F_FO
 SG_ LFSrrTrkMeasStatus9 : 55|2@0+ (1,0) [0|0] ""  EOCM_F_FO
 SG_ LFSrrTrkRawAzimuth9 : 61|6@0- (1,0) [-32|31] "deg"  EOCM_F_FO

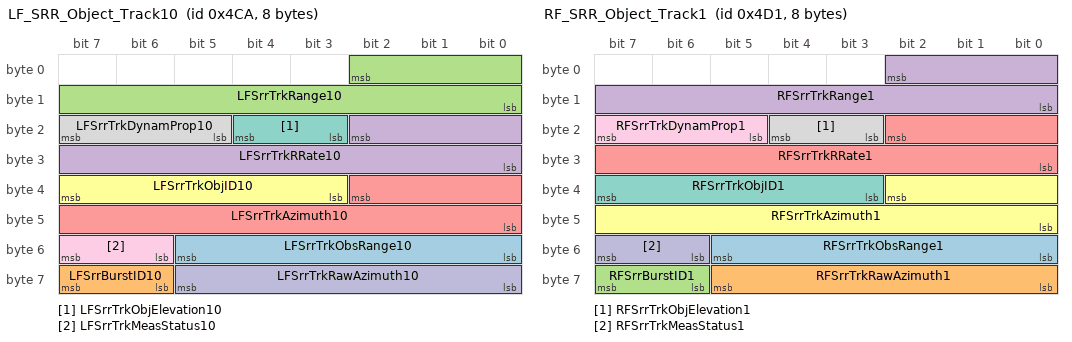
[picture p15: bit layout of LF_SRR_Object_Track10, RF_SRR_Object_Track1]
BO_ 1226 LF_SRR_Object_Track10: 8 LFSRR_FO
 SG_ LFSrrTrkObsRange10 : 53|6@0- (0.02,0) [-0.64|0.62] "m"  EOCM_F_FO
 SG_ LFSrrBurstID10 : 63|2@0+ (1,0) [0|3] ""  EOCM_F_FO
 SG_ LFSrrTrkRange10 : 2|11@0+ (0.02,0) [0|40.94] "m"  EOCM_F_FO
 SG_ LFSrrTrkRRate10 : 18|11@0- (0.125,0) [-128|127.875] "m/s"  EOCM_F_FO
 SG_ LFSrrTrkAzimuth10 : 34|11@0- (0.125,0) [-128|127.875] "deg"  EOCM_F_FO
 SG_ LFSrrTrkObjID10 : 39|5@0+ (1,0) [0|31] ""  EOCM_F_FO
 SG_ LFSrrTrkObjElevation10 : 20|2@0+ (1,0) [0|0] ""  EOCM_F_FO
 SG_ LFSrrTrkDynamProp10 : 23|3@0+ (1,0) [0|0] ""  EOCM_F_FO
 SG_ LFSrrTrkMeasStatus10 : 55|2@0+ (1,0) [0|0] ""  EOCM_F_FO
 SG_ LFSrrTrkRawAzimuth10 : 61|6@0- (1,0) [-32|31] "deg"  EOCM_F_FO

BO_ 1232 RF_SRR_Object_Header: 8 RFSRR_FO
 SG_ RFSRRVltgOutRngLo : 44|1@0+ (1,0) [0|1] ""  EOCM_F_FO
 SG_ RFSRRVltgOutRngHi : 43|1@0+ (1,0) [0|1] ""  EOCM_F_FO
 SG_ RFSRRSvcAlgnInPrcs : 38|1@0+ (1,0) [0|1] ""  EOCM_F_FO
 SG_ RFSRRSnsrBlckd : 45|1@0+ (1,0) [0|1] ""  EOCM_F_FO
 SG_ RFSRRSnstvFltPrsntInt : 24|1@0+ (1,0) [0|1] ""  EOCM_F_FO
 SG_ RFSRRPlntAlgnInProc : 37|1@0+ (1,0) [0|1] ""  EOCM_F_FO
 SG_ RFSRRMsalgnYawRt : 47|1@0+ (1,0) [0|1] ""  EOCM_F_FO
 SG_ RFSRRMsalgnYawLt : 46|1@0+ (1,0) [0|1] ""  EOCM_F_FO
 SG_ RFSRRMsalgnRllRt : 35|1@0+ (1,0) [0|1] ""  EOCM_F_FO
 SG_ RFSRRMsalgnRllLt : 34|1@0+ (1,0) [0|1] ""  EOCM_F_FO
 SG_ RFSRRMsalgnPtchUp : 32|1@0+ (1,0) [0|1] ""  EOCM_F_FO
 SG_ RFSRRMsalgnPtchDn : 33|1@0+ (1,0) [0|1] ""  EOCM_F_FO
 SG_ RFSRRInitDiagCmplt : 40|1@0+ (1,0) [0|1] ""  EOCM_F_FO
 SG_ RFSRRHWFltPrsntInt : 25|1@0+ (1,0) [0|1] ""  EOCM_F_FO
 SG_ RFSRRExtIntrfrnc : 36|1@0+ (1,0) [0|1] ""  EOCM_F_FO
 SG_ RFSRRDiagSpare : 30|1@0+ (1,0) [0|1] ""  EOCM_F_FO
 SG_ RFSRRCANSgnlSpvFld : 29|1@0+ (1,0) [0|1] ""  EOCM_F_FO
 SG_ RFSRRCANRxErr : 28|1@0+ (1,0) [0|1] ""  EOCM_F_FO
 SG_ RFSRRCANIDAddrsUnsbl : 27|1@0+ (1,0) [0|1] ""  EOCM_F_FO
 SG_ RFSRRAntTngFltPrsnt : 26|1@0+ (1,0) [0|1] ""  EOCM_F_FO
 SG_ RFSRRAmbTmpOutRngLw : 42|1@0+ (1,0) [0|1] ""  EOCM_F_FO
 SG_ RFSRRAmbTmpOutRngHi : 41|1@0+ (1,0) [0|1] ""  EOCM_F_FO
 SG_ RFSRRAlgnFltPrsnt : 39|1@0+ (1,0) [0|1] ""  EOCM_F_FO
 SG_ RFSRRNumValidTargets : 14|4@0+ (1,0) [0|15] ""  EOCM_F_FO
 SG_ RFSrrRollingCnt : 1|2@0+ (1,0) [0|3] ""  EOCM_F_FO
 SG_ RFSRRModeCmdFdbk : 4|3@0+ (1,0) [0|7] ""  EOCM_F_FO
 SG_ RFSrrTimeStamp : 10|11@0+ (1,0) [0|2047] "ms"  EOCM_F_FO
 SG_ RFSrrBurstChecksum : 55|16@0+ (1,0) [0|65535] ""  EOCM_F_FO
 SG_ RFSrrTimeStampV : 15|1@0+ (1,0) [0|1] ""  EOCM_F_FO

BO_ 1233 RF_SRR_Object_Track1: 8 RFSRR_FO
 SG_ RFSrrTrkObsRange1 : 53|6@0- (0.02,0) [-0.64|0.62] "m"  EOCM_F_FO
 SG_ RFSrrTrkRawAzimuth1 : 61|6@0- (1,0) [-32|31] "deg"  EOCM_F_FO
 SG_ RFSrrBurstID1 : 63|2@0+ (1,0) [0|3] ""  EOCM_F_FO
 SG_ RFSrrTrkRange1 : 2|11@0+ (0.02,0) [0|40.94] "m"  EOCM_F_FO
 SG_ RFSrrTrkRRate1 : 18|11@0- (0.125,0) [-128|127.875] "m/s"  EOCM_F_FO
 SG_ RFSrrTrkAzimuth1 : 34|11@0- (0.125,0) [-128|127.875] "deg"  EOCM_F_FO
 SG_ RFSrrTrkObjID1 : 39|5@0+ (1,0) [0|31] ""  EOCM_F_FO
 SG_ RFSrrTrkObjElevation1 : 20|2@0+ (1,0) [0|0] ""  EOCM_F_FO
 SG_ RFSrrTrkDynamProp1 : 23|3@0+ (1,0) [0|0] ""  EOCM_F_FO
 SG_ RFSrrTrkMeasStatus1 : 55|2@0+ (1,0) [0|0] ""  EOCM_F_FO

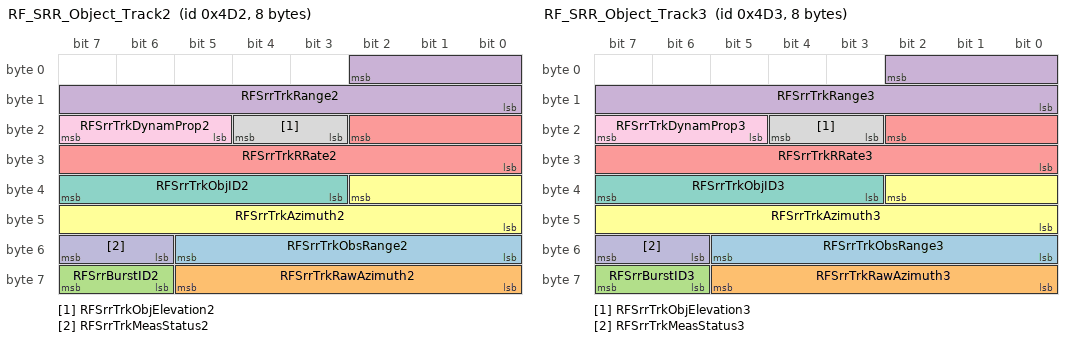
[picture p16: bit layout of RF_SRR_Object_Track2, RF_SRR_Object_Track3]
BO_ 1234 RF_SRR_Object_Track2: 8 RFSRR_FO
 SG_ RFSrrTrkObsRange2 : 53|6@0- (0.02,0) [-0.64|0.62] "m"  EOCM_F_FO
 SG_ RFSrrTrkRawAzimuth2 : 61|6@0- (1,0) [-32|31] "deg"  EOCM_F_FO
 SG_ RFSrrBurstID2 : 63|2@0+ (1,0) [0|3] ""  EOCM_F_FO
 SG_ RFSrrTrkRange2 : 2|11@0+ (0.02,0) [0|40.94] "m"  EOCM_F_FO
 SG_ RFSrrTrkRRate2 : 18|11@0- (0.125,0) [-128|127.875] "m/s"  EOCM_F_FO
 SG_ RFSrrTrkAzimuth2 : 34|11@0- (0.125,0) [-128|127.875] "deg"  EOCM_F_FO
 SG_ RFSrrTrkObjID2 : 39|5@0+ (1,0) [0|31] ""  EOCM_F_FO
 SG_ RFSrrTrkObjElevation2 : 20|2@0+ (1,0) [0|0] ""  EOCM_F_FO
 SG_ RFSrrTrkDynamProp2 : 23|3@0+ (1,0) [0|0] ""  EOCM_F_FO
 SG_ RFSrrTrkMeasStatus2 : 55|2@0+ (1,0) [0|0] ""  EOCM_F_FO

BO_ 1235 RF_SRR_Object_Track3: 8 RFSRR_FO
 SG_ RFSrrTrkObsRange3 : 53|6@0- (0.02,0) [-0.64|0.62] "m"  EOCM_F_FO
 SG_ RFSrrTrkRawAzimuth3 : 61|6@0- (1,0) [-32|31] "deg"  EOCM_F_FO
 SG_ RFSrrBurstID3 : 63|2@0+ (1,0) [0|3] ""  EOCM_F_FO
 SG_ RFSrrTrkRange3 : 2|11@0+ (0.02,0) [0|40.94] "m"  EOCM_F_FO
 SG_ RFSrrTrkRRate3 : 18|11@0- (0.125,0) [-128|127.875] "m/s"  EOCM_F_FO
 SG_ RFSrrTrkAzimuth3 : 34|11@0- (0.125,0) [-128|127.875] "deg"  EOCM_F_FO
 SG_ RFSrrTrkObjID3 : 39|5@0+ (1,0) [0|31] ""  EOCM_F_FO
 SG_ RFSrrTrkObjElevation3 : 20|2@0+ (1,0) [0|0] ""  EOCM_F_FO
 SG_ RFSrrTrkDynamProp3 : 23|3@0+ (1,0) [0|0] ""  EOCM_F_FO
 SG_ RFSrrTrkMeasStatus3 : 55|2@0+ (1,0) [0|0] ""  EOCM_F_FO

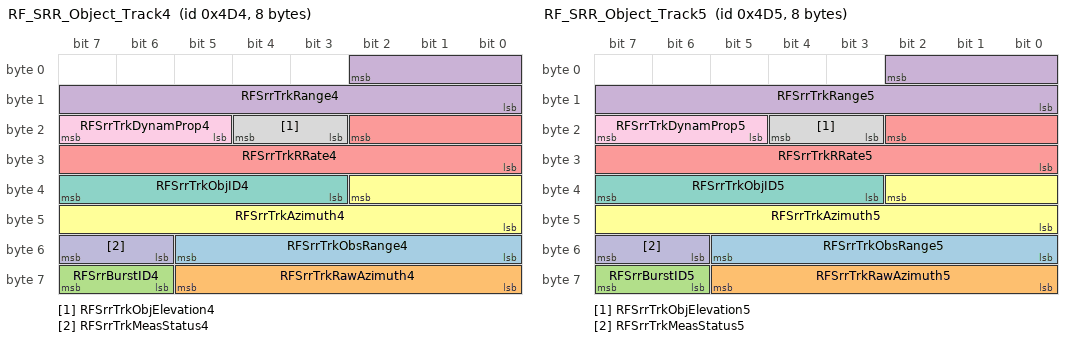
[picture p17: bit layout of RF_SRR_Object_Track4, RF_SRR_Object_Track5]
BO_ 1236 RF_SRR_Object_Track4: 8 RFSRR_FO
 SG_ RFSrrTrkObsRange4 : 53|6@0- (0.02,0) [-0.64|0.62] "m"  EOCM_F_FO
 SG_ RFSrrTrkRawAzimuth4 : 61|6@0- (1,0) [-32|31] "deg"  EOCM_F_FO
 SG_ RFSrrBurstID4 : 63|2@0+ (1,0) [0|3] ""  EOCM_F_FO
 SG_ RFSrrTrkRange4 : 2|11@0+ (0.02,0) [0|40.94] "m"  EOCM_F_FO
 SG_ RFSrrTrkRRate4 : 18|11@0- (0.125,0) [-128|127.875] "m/s"  EOCM_F_FO
 SG_ RFSrrTrkAzimuth4 : 34|11@0- (0.125,0) [-128|127.875] "deg"  EOCM_F_FO
 SG_ RFSrrTrkObjID4 : 39|5@0+ (1,0) [0|31] ""  EOCM_F_FO
 SG_ RFSrrTrkObjElevation4 : 20|2@0+ (1,0) [0|0] ""  EOCM_F_FO
 SG_ RFSrrTrkDynamProp4 : 23|3@0+ (1,0) [0|0] ""  EOCM_F_FO
 SG_ RFSrrTrkMeasStatus4 : 55|2@0+ (1,0) [0|0] ""  EOCM_F_FO

BO_ 1237 RF_SRR_Object_Track5: 8 RFSRR_FO
 SG_ RFSrrTrkObsRange5 : 53|6@0- (0.02,0) [-0.64|0.62] "m"  EOCM_F_FO
 SG_ RFSrrTrkRawAzimuth5 : 61|6@0- (1,0) [-32|31] "deg"  EOCM_F_FO
 SG_ RFSrrBurstID5 : 63|2@0+ (1,0) [0|3] ""  EOCM_F_FO
 SG_ RFSrrTrkRange5 : 2|11@0+ (0.02,0) [0|40.94] "m"  EOCM_F_FO
 SG_ RFSrrTrkRRate5 : 18|11@0- (0.125,0) [-128|127.875] "m/s"  EOCM_F_FO
 SG_ RFSrrTrkAzimuth5 : 34|11@0- (0.125,0) [-128|127.875] "deg"  EOCM_F_FO
 SG_ RFSrrTrkObjID5 : 39|5@0+ (1,0) [0|31] ""  EOCM_F_FO
 SG_ RFSrrTrkObjElevation5 : 20|2@0+ (1,0) [0|0] ""  EOCM_F_FO
 SG_ RFSrrTrkDynamProp5 : 23|3@0+ (1,0) [0|0] ""  EOCM_F_FO
 SG_ RFSrrTrkMeasStatus5 : 55|2@0+ (1,0) [0|0] ""  EOCM_F_FO

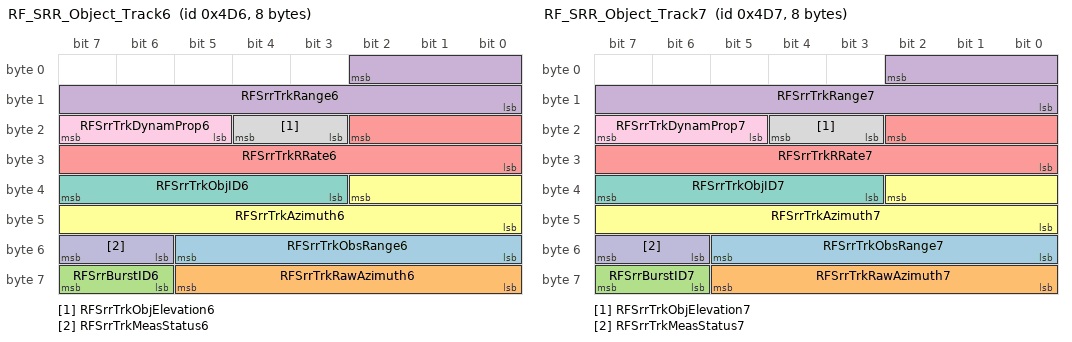
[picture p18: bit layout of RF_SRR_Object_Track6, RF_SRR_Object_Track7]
BO_ 1238 RF_SRR_Object_Track6: 8 RFSRR_FO
 SG_ RFSrrTrkObsRange6 : 53|6@0- (0.02,0) [-0.64|0.62] "m"  EOCM_F_FO
 SG_ RFSrrTrkRawAzimuth6 : 61|6@0- (1,0) [-32|31] "deg"  EOCM_F_FO
 SG_ RFSrrBurstID6 : 63|2@0+ (1,0) [0|3] ""  EOCM_F_FO
 SG_ RFSrrTrkRange6 : 2|11@0+ (0.02,0) [0|40.94] "m"  EOCM_F_FO
 SG_ RFSrrTrkRRate6 : 18|11@0- (0.125,0) [-128|127.875] "m/s"  EOCM_F_FO
 SG_ RFSrrTrkAzimuth6 : 34|11@0- (0.125,0) [-128|127.875] "deg"  EOCM_F_FO
 SG_ RFSrrTrkObjID6 : 39|5@0+ (1,0) [0|31] ""  EOCM_F_FO
 SG_ RFSrrTrkObjElevation6 : 20|2@0+ (1,0) [0|0] ""  EOCM_F_FO
 SG_ RFSrrTrkDynamProp6 : 23|3@0+ (1,0) [0|0] ""  EOCM_F_FO
 SG_ RFSrrTrkMeasStatus6 : 55|2@0+ (1,0) [0|0] ""  EOCM_F_FO

BO_ 1239 RF_SRR_Object_Track7: 8 RFSRR_FO
 SG_ RFSrrTrkObsRange7 : 53|6@0- (0.02,0) [-0.64|0.62] "m"  EOCM_F_FO
 SG_ RFSrrTrkRawAzimuth7 : 61|6@0- (1,0) [-32|31] "deg"  EOCM_F_FO
 SG_ RFSrrBurstID7 : 63|2@0+ (1,0) [0|3] ""  EOCM_F_FO
 SG_ RFSrrTrkRange7 : 2|11@0+ (0.02,0) [0|40.94] "m"  EOCM_F_FO
 SG_ RFSrrTrkRRate7 : 18|11@0- (0.125,0) [-128|127.875] "m/s"  EOCM_F_FO
 SG_ RFSrrTrkAzimuth7 : 34|11@0- (0.125,0) [-128|127.875] "deg"  EOCM_F_FO
 SG_ RFSrrTrkObjID7 : 39|5@0+ (1,0) [0|31] ""  EOCM_F_FO
 SG_ RFSrrTrkObjElevation7 : 20|2@0+ (1,0) [0|0] ""  EOCM_F_FO
 SG_ RFSrrTrkDynamProp7 : 23|3@0+ (1,0) [0|0] ""  EOCM_F_FO
 SG_ RFSrrTrkMeasStatus7 : 55|2@0+ (1,0) [0|0] ""  EOCM_F_FO

BO_ 1240 RF_SRR_Object_Track8: 8 RFSRR_FO
 SG_ RFSrrTrkObsRange8 : 53|6@0- (0.02,0) [-0.64|0.62] "m"  EOCM_F_FO
 SG_ RFSrrTrkRawAzimuth8 : 61|6@0- (1,0) [-32|31] "deg"  EOCM_F_FO
 SG_ RFSrrBurstID8 : 63|2@0+ (1,0) [0|3] ""  EOCM_F_FO
 SG_ RFSrrTrkRange8 : 2|11@0+ (0.02,0) [0|40.94] "m"  EOCM_F_FO
 SG_ RFSrrTrkRRate8 : 18|11@0- (0.125,0) [-128|127.875] "m/s"  EOCM_F_FO
 SG_ RFSrrTrkAzimuth8 : 34|11@0- (0.125,0) [-128|127.875] "deg"  EOCM_F_FO
 SG_ RFSrrTrkObjID8 : 39|5@0+ (1,0) [0|31] ""  EOCM_F_FO
 SG_ RFSrrTrkObjElevation8 : 20|2@0+ (1,0) [0|0] ""  EOCM_F_FO
 SG_ RFSrrTrkDynamProp8 : 23|3@0+ (1,0) [0|0] ""  EOCM_F_FO
 SG_ RFSrrTrkMeasStatus8 : 55|2@0+ (1,0) [0|0] ""  EOCM_F_FO

BO_ 1241 RF_SRR_Object_Track9: 8 RFSRR_FO
 SG_ RFSrrTrkObsRange9 : 53|6@0- (0.02,0) [-0.64|0.62] "m"  EOCM_F_FO
 SG_ RFSrrTrkRawAzimuth9 : 61|6@0- (1,0) [-32|31] "deg"  EOCM_F_FO
 SG_ RFSrrBurstID9 : 63|2@0+ (1,0) [0|3] ""  EOCM_F_FO
 SG_ RFSrrTrkRange9 : 2|11@0+ (0.02,0) [0|40.94] "m"  EOCM_F_FO
 SG_ RFSrrTrkRRate9 : 18|11@0- (0.125,0) [-128|127.875] "m/s"  EOCM_F_FO
 SG_ RFSrrTrkAzimuth9 : 34|11@0- (0.125,0) [-128|127.875] "deg"  EOCM_F_FO
 SG_ RFSrrTrkObjID9 : 39|5@0+ (1,0) [0|31] ""  EOCM_F_FO
 SG_ RFSrrTrkObjElevation9 : 20|2@0+ (1,0) [0|0] ""  EOCM_F_FO
 SG_ RFSrrTrkDynamProp9 : 23|3@0+ (1,0) [0|0] ""  EOCM_F_FO
 SG_ RFSrrTrkMeasStatus9 : 55|2@0+ (1,0) [0|0] ""  EOCM_F_FO

BO_ 1242 RF_SRR_Object_Track10: 8 RFSRR_FO
 SG_ RFSrrTrkObsRange10 : 53|6@0- (0.02,0) [-0.64|0.62] "m"  EOCM_F_FO
 SG_ RFSrrTrkRawAzimuth10 : 61|6@0- (1,0) [-32|31] "deg"  EOCM_F_FO
 SG_ RFSrrBurstID10 : 63|2@0+ (1,0) [0|3] ""  EOCM_F_FO
 SG_ RFSrrTrkRange10 : 2|11@0+ (0.02,0) [0|40.94] "m"  EOCM_F_FO
 SG_ RFSrrTrkRRate10 : 18|11@0- (0.125,0) [-128|127.875] "m/s"  EOCM_F_FO
 SG_ RFSrrTrkAzimuth10 : 34|11@0- (0.125,0) [-128|127.875] "deg"  EOCM_F_FO
 SG_ RFSrrTrkObjID10 : 39|5@0+ (1,0) [0|31] ""  EOCM_F_FO
 SG_ RFSrrTrkObjElevation10 : 20|2@0+ (1,0) [0|0] ""  EOCM_F_FO
 SG_ RFSrrTrkDynamProp10 : 23|3@0+ (1,0) [0|0] ""  EOCM_F_FO
 SG_ RFSrrTrkMeasStatus10 : 55|2@0+ (1,0) [0|0] ""  EOCM_F_FO

BO_ 1088 F_Vision_Obj_Header: 8 VIS_FO
 SG_ FVISVltgOutRngLo : 44|1@0+ (1,0) [0|1] ""  EOCM_F_FO
 SG_ FVISVltgOutRngHi : 43|1@0+ (1,0) [0|1] ""  EOCM_F_FO
 SG_ FVISSvcAlgnInPrcs : 38|1@0+ (1,0) [0|1] ""  EOCM_F_FO
 SG_ FVISSnsrBlckd : 45|1@0+ (1,0) [0|1] ""  EOCM_F_FO
 SG_ FVISSnstvFltPrsntInt : 24|1@0+ (1,0) [0|1] ""  EOCM_F_FO
 SG_ FVISPlntAlgnInProc : 37|1@0+ (1,0) [0|1] ""  EOCM_F_FO
 SG_ FVISMsalgnYawRt : 47|1@0+ (1,0) [0|1] ""  EOCM_F_FO
 SG_ FVISMsalgnYawLt : 46|1@0+ (1,0) [0|1] ""  EOCM_F_FO
 SG_ FVISMsalgnRllRt : 35|1@0+ (1,0) [0|1] ""  EOCM_F_FO
 SG_ FVISMsalgnRllLt : 34|1@0+ (1,0) [0|1] ""  EOCM_F_FO
 SG_ FVISMsalgnPtchUp : 32|1@0+ (1,0) [0|1] ""  EOCM_F_FO
 SG_ FVISMsalgnPtchDn : 33|1@0+ (1,0) [0|1] ""  EOCM_F_FO
 SG_ FVISInitDiagCmplt : 40|1@0+ (1,0) [0|1] ""  EOCM_F_FO
 SG_ FVISHWFltPrsntInt : 25|1@0+ (1,0) [0|1] ""  EOCM_F_FO
 SG_ FVISExtIntrfrnc : 36|1@0+ (1,0) [0|1] ""  EOCM_F_FO
 SG_ FVISDiagSpare : 30|1@0+ (1,0) [0|1] ""  EOCM_F_FO
 SG_ FVISCANSgnlSpvFld : 29|1@0+ (1,0) [0|1] ""  EOCM_F_FO
 SG_ FVISCANRxErr : 28|1@0+ (1,0) [0|1] ""  EOCM_F_FO
 SG_ FVISCANIDAddrsUnsbl : 27|1@0+ (1,0) [0|1] ""  EOCM_F_FO
 SG_ FVISAntTngFltPrsnt : 26|1@0+ (1,0) [0|1] ""  EOCM_F_FO
 SG_ FVISAmbTmpOutRngLw : 42|1@0+ (1,0) [0|1] ""  EOCM_F_FO
 SG_ FVISAmbTmpOutRngHi : 41|1@0+ (1,0) [0|1] ""  EOCM_F_FO
 SG_ FVISAlgnFltPrsnt : 39|1@0+ (1,0) [0|1] ""  EOCM_F_FO
 SG_ FVisionRollingCnt : 1|2@0+ (1,0) [0|3] ""  EOCM_F_FO
 SG_ FVISModeCmdFdbk : 4|3@0+ (1,0) [0|0] ""  EOCM_F_FO
 SG_ FVisionNumValidTrgts : 14|4@0+ (1,0) [0|15] ""  EOCM_F_FO
 SG_ FVisionTimeStampV : 31|1@0+ (1,0) [0|1] ""  EOCM_F_FO
 SG_ FVisionTimeStamp : 10|11@0+ (1,0) [0|2047] "ms"  EOCM_F_FO
 SG_ VISBurstChecksum : 55|16@0+ (1,0) [0|65535] ""  EOCM_F_FO

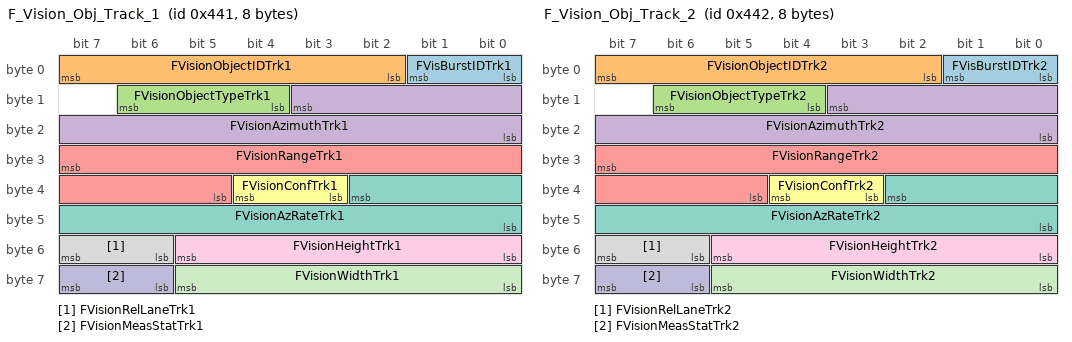
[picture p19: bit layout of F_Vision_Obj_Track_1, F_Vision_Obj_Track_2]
BO_ 1089 F_Vision_Obj_Track_1: 8 VIS_FO
 SG_ FVisBurstIDTrk1 : 1|2@0+ (1,0) [0|3] ""  EOCM_F_FO
 SG_ FVisionObjectIDTrk1 : 7|6@0+ (1,0) [0|63] ""  EOCM_F_FO
 SG_ FVisionObjectTypeTrk1 : 14|3@0+ (1,0) [0|0] ""  EOCM_F_FO
 SG_ FVisionAzimuthTrk1 : 11|12@0- (0.125,0) [-256|255.875] "deg"  EOCM_F_FO
 SG_ FVisionRangeTrk1 : 31|11@0+ (0.125,0) [0|255.875] "m"  EOCM_F_FO
 SG_ FVisionConfTrk1 : 36|2@0+ (1,0) [0|0] ""  EOCM_F_FO
 SG_ FVisionAzRateTrk1 : 34|11@0- (0.125,0) [-128|127.875] "deg/s"  EOCM_F_FO
 SG_ FVisionRelLaneTrk1 : 55|2@0+ (1,0) [0|0] ""  EOCM_F_FO
 SG_ FVisionHeightTrk1 : 53|6@0+ (0.25,0) [0|15.75] "m"  EOCM_F_FO
 SG_ FVisionMeasStatTrk1 : 63|2@0+ (1,0) [0|0] ""  EOCM_F_FO
 SG_ FVisionWidthTrk1 : 61|6@0+ (0.25,0) [0|15.75] "m"  EOCM_F_FO

BO_ 1090 F_Vision_Obj_Track_2: 8 VIS_FO
 SG_ FVisBurstIDTrk2 : 1|2@0+ (1,0) [0|3] ""  EOCM_F_FO
 SG_ FVisionObjectIDTrk2 : 7|6@0+ (1,0) [0|63] ""  EOCM_F_FO
 SG_ FVisionObjectTypeTrk2 : 14|3@0+ (1,0) [0|0] ""  EOCM_F_FO
 SG_ FVisionAzimuthTrk2 : 11|12@0- (0.125,0) [-256|255.875] "deg"  EOCM_F_FO
 SG_ FVisionRangeTrk2 : 31|11@0+ (0.125,0) [0|255.875] "m"  EOCM_F_FO
 SG_ FVisionConfTrk2 : 36|2@0+ (1,0) [0|0] ""  EOCM_F_FO
 SG_ FVisionAzRateTrk2 : 34|11@0- (0.125,0) [-128|127.875] "deg/s"  EOCM_F_FO
 SG_ FVisionRelLaneTrk2 : 55|2@0+ (1,0) [0|0] ""  EOCM_F_FO
 SG_ FVisionHeightTrk2 : 53|6@0+ (0.25,0) [0|15.75] "m"  EOCM_F_FO
 SG_ FVisionMeasStatTrk2 : 63|2@0+ (1,0) [0|0] ""  EOCM_F_FO
 SG_ FVisionWidthTrk2 : 61|6@0+ (0.25,0) [0|15.75] "m"  EOCM_F_FO

CM_ SG_ 1184 RSRRModeCmdFdbk "0 = Disabled
1 = Standby
2 = Enabled
3 + Reserved";
CM_ SG_ 1216 LFSRRModeCmdFdbk "0 = Disabled
1 = Standby
2 = Enabled
3 + Reserved";
CM_ SG_ 1232 RFSRRModeCmdFdbk "0 = Disabled
1 = Standby
2 = Enabled
3 + Reserved";
BA_DEF_ SG_  "VNSigSLHSSharedDiagnostic" ENUM  "No","Yes";
BA_DEF_ SG_  "SignalType" STRING ;
BA_DEF_ SG_  "PacketOrder" INT 0 65535;
BA_DEF_ SG_  "SignalLongName" STRING ;
BA_DEF_ SG_  "GenSigStartValue" INT 0 65535;
BA_DEF_ SG_  "VNSigAllNodes" ENUM  "No","Yes";
BA_DEF_ SG_  "GenSigSendType" ENUM  "not used","not used","not used","not used","not used","not used","not used","NoSigSendType","not used","not used","OnAnyChange","OnChangeIfActive","OnDelta";
BA_DEF_ SG_  "GenSigSendOnInit" ENUM  "Not Initialized","Application","Handler";
BA_DEF_ BO_  "GenMsgILSupport" ENUM  "No","Yes";
BA_DEF_ BO_  "TpApplType" STRING ;
BA_DEF_ BO_  "Prio" INT 0 7;
BA_DEF_ BO_  "MessageSubnet" ENUM  "LS","MS","HS","CE","PE","HV","FO";
BA_DEF_ BO_  "DiagState" ENUM  "No","Yes";
BA_DEF_ BO_  "GenMsgDelayTime" INT 0 100000;
BA_DEF_ BO_  "GenMsgCycleTime" INT 0 100000;
BA_DEF_ BO_  "GenMsgCycleTimeFast" INT 0 100000;
BA_DEF_ BO_  "GenMsgSendType" ENUM  "cyclicX","spontanX","cyclicIfActiveX","spontanWithDelay","cyclicAndSpontanX","cyclicAndSpontanWithDelay","spontanWithRepitition","cyclicIfActiveAndSpontanWD";
BA_DEF_ BO_  "DiagResponse" ENUM  "No","Yes";
BA_DEF_ BO_  "DiagRequest" ENUM  "No","Yes";
BA_DEF_ BO_  "NmMessage" ENUM  "No","Yes";
BA_DEF_REL_ BU_SG_REL_  "GenSigSuprvRespComment" STRING ;
BA_DEF_REL_ BU_SG_REL_  "GenSigVBitResp" ENUM  "No","Yes";
BA_DEF_REL_ BU_SG_REL_  "GenSigVBitRespComment" STRING ;
BA_DEF_REL_ BU_SG_REL_  "GenSigVDAFailComment" STRING ;
BA_DEF_REL_ BU_SG_REL_  "GenSigSuprvResp" ENUM  "None","Notify App","Substitute Default";
BA_DEF_REL_ BU_SG_REL_  "GenSigTimeoutMsg" HEX -2147483648 268435455;
BA_DEF_REL_ BU_SG_REL_  "GenSigTimeoutTime" INT 0 15000;
BA_DEF_DEF_  "VNSigSLHSSharedDiagnostic" "No";
BA_DEF_DEF_  "SignalType" "";
BA_DEF_DEF_  "PacketOrder" 0;
BA_DEF_DEF_  "SignalLongName" "";
BA_DEF_DEF_  "GenSigStartValue" 0;
BA_DEF_DEF_  "VNSigAllNodes" "No";
BA_DEF_DEF_  "GenSigSendType" "NoSigSendType";
BA_DEF_DEF_  "GenSigSendOnInit" "Not Initialized";
BA_DEF_DEF_  "GenMsgILSupport" "Yes";
BA_DEF_DEF_  "TpApplType" "";
BA_DEF_DEF_  "Prio" 4;
BA_DEF_DEF_  "MessageSubnet" "FO";
BA_DEF_DEF_  "DiagState" "No";
BA_DEF_DEF_  "GenMsgDelayTime" 0;
BA_DEF_DEF_  "GenMsgCycleTime" 0;
BA_DEF_DEF_  "GenMsgCycleTimeFast" 0;
BA_DEF_DEF_  "GenMsgSendType" "spontanX";
BA_DEF_DEF_  "DiagResponse" "No";
BA_DEF_DEF_  "DiagRequest" "No";
BA_DEF_DEF_  "NmMessage" "No";
BA_DEF_DEF_REL_ "GenSigSuprvRespComment" "";
BA_DEF_DEF_REL_ "GenSigVBitResp" "No";
BA_DEF_DEF_REL_ "GenSigVBitRespComment" "";
BA_DEF_DEF_REL_ "GenSigVDAFailComment" "";
BA_DEF_DEF_REL_ "GenSigSuprvResp" "None";
BA_DEF_DEF_REL_ "GenSigTimeoutMsg" 0;
BA_DEF_DEF_REL_ "GenSigTimeoutTime" 0;
BA_ "Prio" BO_ 849 0;
BA_ "GenMsgDelayTime" BO_ 849 55;
BA_ "Prio" BO_ 1184 0;
BA_ "GenMsgDelayTime" BO_ 1184 35;
BA_ "Prio" BO_ 1185 0;
BA_ "GenMsgDelayTime" BO_ 1185 35;
BA_ "Prio" BO_ 1186 0;
BA_ "GenMsgDelayTime" BO_ 1186 35;
BA_ "Prio" BO_ 1187 0;
BA_ "GenMsgDelayTime" BO_ 1187 35;
BA_ "Prio" BO_ 1188 0;
BA_ "GenMsgDelayTime" BO_ 1188 35;
BA_ "Prio" BO_ 1189 0;
BA_ "GenMsgDelayTime" BO_ 1189 35;
BA_ "Prio" BO_ 1190 0;
BA_ "GenMsgDelayTime" BO_ 1190 35;
BA_ "Prio" BO_ 1191 0;
BA_ "GenMsgDelayTime" BO_ 1191 35;
BA_ "Prio" BO_ 1192 0;
BA_ "GenMsgDelayTime" BO_ 1192 35;
BA_ "Prio" BO_ 1193 0;
BA_ "GenMsgDelayTime" BO_ 1193 35;
BA_ "Prio" BO_ 1194 0;
BA_ "GenMsgDelayTime" BO_ 1194 35;
BA_ "Prio" BO_ 1380 0;
BA_ "GenMsgCycleTime" BO_ 1380 100;
BA_ "GenMsgSendType" BO_ 1380 0;
BA_ "Prio" BO_ 1379 0;
BA_ "GenMsgCycleTime" BO_ 1379 100;
BA_ "GenMsgSendType" BO_ 1379 0;
BA_ "Prio" BO_ 1378 0;
BA_ "GenMsgCycleTime" BO_ 1378 100;
BA_ "GenMsgSendType" BO_ 1378 0;
BA_ "Prio" BO_ 1391 0;
BA_ "GenMsgCycleTime" BO_ 1391 100;
BA_ "GenMsgSendType" BO_ 1391 0;
BA_ "Prio" BO_ 1390 0;
BA_ "GenMsgCycleTime" BO_ 1390 100;
BA_ "GenMsgSendType" BO_ 1390 0;
BA_ "Prio" BO_ 1389 0;
BA_ "GenMsgCycleTime" BO_ 1389 100;
BA_ "GenMsgSendType" BO_ 1389 0;
BA_ "Prio" BO_ 1388 0;
BA_ "GenMsgCycleTime" BO_ 1388 100;
BA_ "GenMsgSendType" BO_ 1388 0;
BA_ "Prio" BO_ 1387 0;
BA_ "GenMsgCycleTime" BO_ 1387 100;
BA_ "GenMsgSendType" BO_ 1387 0;
BA_ "Prio" BO_ 1386 0;
BA_ "GenMsgCycleTime" BO_ 1386 100;
BA_ "GenMsgSendType" BO_ 1386 0;
BA_ "Prio" BO_ 1377 0;
BA_ "GenMsgCycleTime" BO_ 1377 100;
BA_ "GenMsgSendType" BO_ 1377 0;
BA_ "Prio" BO_ 1410 0;
BA_ "GenMsgCycleTime" BO_ 1410 100;
BA_ "GenMsgSendType" BO_ 1410 0;
BA_ "Prio" BO_ 1216 0;
BA_ "GenMsgDelayTime" BO_ 1216 35;
BA_ "Prio" BO_ 1217 0;
BA_ "GenMsgDelayTime" BO_ 1217 35;
BA_ "Prio" BO_ 1218 0;
BA_ "GenMsgDelayTime" BO_ 1218 35;
BA_ "Prio" BO_ 1219 0;
BA_ "GenMsgDelayTime" BO_ 1219 35;
BA_ "Prio" BO_ 1220 0;
BA_ "GenMsgDelayTime" BO_ 1220 35;
BA_ "Prio" BO_ 1221 0;
BA_ "GenMsgDelayTime" BO_ 1221 35;
BA_ "Prio" BO_ 1222 0;
BA_ "GenMsgDelayTime" BO_ 1222 35;
BA_ "Prio" BO_ 1223 0;
BA_ "GenMsgDelayTime" BO_ 1223 35;
BA_ "Prio" BO_ 1224 0;
BA_ "GenMsgDelayTime" BO_ 1224 35;
BA_ "Prio" BO_ 1225 0;
BA_ "GenMsgDelayTime" BO_ 1225 35;
BA_ "Prio" BO_ 1226 0;
BA_ "GenMsgDelayTime" BO_ 1226 35;
BA_ "Prio" BO_ 1232 0;
BA_ "GenMsgDelayTime" BO_ 1232 35;
BA_ "Prio" BO_ 1233 0;
BA_ "GenMsgDelayTime" BO_ 1233 35;
BA_ "Prio" BO_ 1234 0;
BA_ "GenMsgDelayTime" BO_ 1234 35;
BA_ "Prio" BO_ 1235 0;
BA_ "GenMsgDelayTime" BO_ 1235 35;
BA_ "Prio" BO_ 1236 0;
BA_ "GenMsgDelayTime" BO_ 1236 35;
BA_ "Prio" BO_ 1237 0;
BA_ "GenMsgDelayTime" BO_ 1237 35;
BA_ "Prio" BO_ 1238 0;
BA_ "GenMsgDelayTime" BO_ 1238 35;
BA_ "Prio" BO_ 1239 0;
BA_ "GenMsgDelayTime" BO_ 1239 35;
BA_ "Prio" BO_ 1240 0;
BA_ "GenMsgDelayTime" BO_ 1240 35;
BA_ "Prio" BO_ 1241 0;
BA_ "GenMsgDelayTime" BO_ 1241 35;
BA_ "Prio" BO_ 1242 0;
BA_ "GenMsgDelayTime" BO_ 1242 35;
BA_ "Prio" BO_ 1088 0;
BA_ "GenMsgDelayTime" BO_ 1088 55;
BA_ "Prio" BO_ 1089 0;
BA_ "GenMsgDelayTime" BO_ 1089 55;
BA_ "Prio" BO_ 1090 0;
BA_ "GenMsgDelayTime" BO_ 1090 55;
BA_ "SignalType" SG_ 849 LnSnsBurstID "UNM";
BA_ "SignalLongName" SG_ 849 LnSnsBurstID "Lane Sense Burst ID";
BA_ "VNSigAllNodes" SG_ 849 LnSnsBurstID 1;
BA_ "SignalType" SG_ 849 LaneSensRawLatVel "SNM";
BA_ "SignalLongName" SG_ 849 LaneSensRawLatVel "Lane Sense Raw Lateral Velocity";
BA_ "VNSigAllNodes" SG_ 849 LaneSensRawLatVel 1;
BA_ "SignalType" SG_ 849 LnSnsCrvtGrdntRt "SNM";
BA_ "SignalLongName" SG_ 849 LnSnsCrvtGrdntRt "Lane Sense Curvature Gradient Right";
BA_ "VNSigAllNodes" SG_ 849 LnSnsCrvtGrdntRt 1;
BA_ "SignalType" SG_ 849 LnSnsLnCrvtrRghtV "ENM";
BA_ "SignalLongName" SG_ 849 LnSnsLnCrvtrRghtV "Lane Sense Lane Curvature Right Validity";
BA_ "VNSigAllNodes" SG_ 849 LnSnsLnCrvtrRghtV 1;
BA_ "SignalType" SG_ 849 LnSnsLnCrvtrRght "SNM";
BA_ "SignalLongName" SG_ 849 LnSnsLnCrvtrRght "Lane Sense Lane Curvature Right";
BA_ "VNSigAllNodes" SG_ 849 LnSnsLnCrvtrRght 1;
BA_ "SignalType" SG_ 1184 RSRRNumValidTargets "UNM";
BA_ "SignalLongName" SG_ 1184 RSRRNumValidTargets "Rear Short Range Radar Number of Valid Targets";
BA_ "VNSigAllNodes" SG_ 1184 RSRRNumValidTargets 1;
BA_ "SignalType" SG_ 1184 RSrrRollingCnt "UNM";
BA_ "SignalLongName" SG_ 1184 RSrrRollingCnt "Rear Short Range Radar Rolling Count";
BA_ "VNSigAllNodes" SG_ 1184 RSrrRollingCnt 1;
BA_ "SignalType" SG_ 1184 RSRRModeCmdFdbk "ENM";
BA_ "SignalLongName" SG_ 1184 RSRRModeCmdFdbk "Rear Short Range Radar Mode Command Feedback";
BA_ "VNSigAllNodes" SG_ 1184 RSRRModeCmdFdbk 1;
BA_ "SignalType" SG_ 1184 RSrrTimeStampV "ENM";
BA_ "SignalLongName" SG_ 1184 RSrrTimeStampV "Rear Short Range Radar Time Stamp Validity";
BA_ "VNSigAllNodes" SG_ 1184 RSrrTimeStampV 1;
BA_ "SignalType" SG_ 1184 RSrrTimeStamp "UNM";
BA_ "SignalLongName" SG_ 1184 RSrrTimeStamp "Rear Short Range Radar Time Stamp";
BA_ "VNSigAllNodes" SG_ 1184 RSrrTimeStamp 1;
BA_ "SignalType" SG_ 1184 RSrrBurstChecksum "UNM";
BA_ "SignalLongName" SG_ 1184 RSrrBurstChecksum "Rear Short Range Radar Burst Checksum";
BA_ "VNSigAllNodes" SG_ 1184 RSrrBurstChecksum 1;
BA_ "SignalType" SG_ 1184 RSRRSnstvFltPrsntInt "BLN";
BA_ "SignalLongName" SG_ 1184 RSRRSnstvFltPrsntInt "Rear Short Range Radar Sensitivity Fault Present, Internal";
BA_ "VNSigAllNodes" SG_ 1184 RSRRSnstvFltPrsntInt 1;
BA_ "SignalType" SG_ 1184 RSRRPlntAlgnInProc "BLN";
BA_ "SignalLongName" SG_ 1184 RSRRPlntAlgnInProc "Rear Short Range Radar Plant Alignment in Process";
BA_ "VNSigAllNodes" SG_ 1184 RSRRPlntAlgnInProc 1;
BA_ "SignalType" SG_ 1184 RSRRMsalgnYawRt "BLN";
BA_ "SignalLongName" SG_ 1184 RSRRMsalgnYawRt "Rear Short Range Radar Misalignment Yaw Right";
BA_ "VNSigAllNodes" SG_ 1184 RSRRMsalgnYawRt 1;
BA_ "SignalType" SG_ 1184 RSRRMsalgnYawLt "BLN";
BA_ "SignalLongName" SG_ 1184 RSRRMsalgnYawLt "Rear Short Range Radar Misalignment Yaw Left";
BA_ "VNSigAllNodes" SG_ 1184 RSRRMsalgnYawLt 1;
BA_ "SignalType" SG_ 1184 RSRRMsalgnRllRt "BLN";
BA_ "SignalLongName" SG_ 1184 RSRRMsalgnRllRt "Rear Short Range Radar Misalignment Roll Right";
BA_ "VNSigAllNodes" SG_ 1184 RSRRMsalgnRllRt 1;
BA_ "SignalType" SG_ 1184 RSRRMsalgnRllLt "BLN";
BA_ "SignalLongName" SG_ 1184 RSRRMsalgnRllLt "Rear Short Range Radar Misalignment Roll Left";
BA_ "VNSigAllNodes" SG_ 1184 RSRRMsalgnRllLt 1;
BA_ "SignalType" SG_ 1184 RSRRMsalgnPtchUp "BLN";
BA_ "SignalLongName" SG_ 1184 RSRRMsalgnPtchUp "Rear Short Range Radar Misalignment Pitch Up";
BA_ "VNSigAllNodes" SG_ 1184 RSRRMsalgnPtchUp 1;
BA_ "SignalType" SG_ 1184 RSRRMsalgnPtchDn "BLN";
BA_ "SignalLongName" SG_ 1184 RSRRMsalgnPtchDn "Rear Short Range Radar Misalignment Pitch Down";
BA_ "VNSigAllNodes" SG_ 1184 RSRRMsalgnPtchDn 1;
BA_ "SignalType" SG_ 1184 RSRRInitDiagCmplt "BLN";
BA_ "SignalLongName" SG_ 1184 RSRRInitDiagCmplt "Rear Short Range Radar Initialization Diagnostics Successfully Completed";
BA_ "VNSigAllNodes" SG_ 1184 RSRRInitDiagCmplt 1;
BA_ "SignalType" SG_ 1184 RSRRHWFltPrsntInt "BLN";
BA_ "SignalLongName" SG_ 1184 RSRRHWFltPrsntInt "Rear Short Range Radar Hardware Fault Present, Internal";
BA_ "VNSigAllNodes" SG_ 1184 RSRRHWFltPrsntInt 1;
BA_ "SignalType" SG_ 1184 RSRRExtIntrfrnc "BLN";
BA_ "SignalLongName" SG_ 1184 RSRRExtIntrfrnc "Rear Short Range Radar External Interference";
BA_ "VNSigAllNodes" SG_ 1184 RSRRExtIntrfrnc 1;
BA_ "SignalType" SG_ 1184 RSRRDiagSpare "BLN";
BA_ "SignalLongName" SG_ 1184 RSRRDiagSpare "Rear Short Range Radar Diagnostic Spare";
BA_ "VNSigAllNodes" SG_ 1184 RSRRDiagSpare 1;
BA_ "SignalType" SG_ 1184 RSRRCANSgnlSpvFld "BLN";
BA_ "SignalLongName" SG_ 1184 RSRRCANSgnlSpvFld "Rear Short Range Radar CAN Signal Supervision Failed";
BA_ "VNSigAllNodes" SG_ 1184 RSRRCANSgnlSpvFld 1;
BA_ "SignalType" SG_ 1184 RSRRCANRxErr "BLN";
BA_ "SignalLongName" SG_ 1184 RSRRCANRxErr "Rear Short Range Radar CAN Rx Error";
BA_ "VNSigAllNodes" SG_ 1184 RSRRCANRxErr 1;
BA_ "SignalType" SG_ 1184 RSRRCANIDAddrsUnsbl "BLN";
BA_ "SignalLongName" SG_ 1184 RSRRCANIDAddrsUnsbl "Rear Short Range Radar CAN ID Address Unstable";
BA_ "VNSigAllNodes" SG_ 1184 RSRRCANIDAddrsUnsbl 1;
BA_ "SignalType" SG_ 1184 RSRRAntTngFltPrsnt "BLN";
BA_ "SignalLongName" SG_ 1184 RSRRAntTngFltPrsnt "Rear Short Range Radar Antenna Tuning Fault Present";
BA_ "VNSigAllNodes" SG_ 1184 RSRRAntTngFltPrsnt 1;
BA_ "SignalType" SG_ 1184 RSRRAmbTmpOutRngLw "BLN";
BA_ "SignalLongName" SG_ 1184 RSRRAmbTmpOutRngLw "Rear Short Range Radar Ambient Temperature Out of Range Low";
BA_ "VNSigAllNodes" SG_ 1184 RSRRAmbTmpOutRngLw 1;
BA_ "SignalType" SG_ 1184 RSRRAmbTmpOutRngHi "BLN";
BA_ "SignalLongName" SG_ 1184 RSRRAmbTmpOutRngHi "Rear Short Range Radar Ambient Temperature Out of Range High";
BA_ "VNSigAllNodes" SG_ 1184 RSRRAmbTmpOutRngHi 1;
BA_ "SignalType" SG_ 1184 RSRRAlgnFltPrsnt "BLN";
BA_ "SignalLongName" SG_ 1184 RSRRAlgnFltPrsnt "Rear Short Range Radar Alignment Fault Present";
BA_ "VNSigAllNodes" SG_ 1184 RSRRAlgnFltPrsnt 1;
BA_ "SignalType" SG_ 1184 RSRRVltgOutRngLo "BLN";
BA_ "SignalLongName" SG_ 1184 RSRRVltgOutRngLo "Rear Short Range Radar Voltage Out Of Range Low";
BA_ "VNSigAllNodes" SG_ 1184 RSRRVltgOutRngLo 1;
BA_ "SignalType" SG_ 1184 RSRRVltgOutRngHi "BLN";
BA_ "SignalLongName" SG_ 1184 RSRRVltgOutRngHi "Rear Short Range Radar Voltage out of Range High";
BA_ "VNSigAllNodes" SG_ 1184 RSRRVltgOutRngHi 1;
BA_ "SignalType" SG_ 1184 RSRRSvcAlgnInPrcs "BLN";
BA_ "SignalLongName" SG_ 1184 RSRRSvcAlgnInPrcs "Rear Short Range Radar Service Alignment in Process";
BA_ "VNSigAllNodes" SG_ 1184 RSRRSvcAlgnInPrcs 1;
BA_ "SignalType" SG_ 1184 RSRRSnsrBlckd "BLN";
BA_ "SignalLongName" SG_ 1184 RSRRSnsrBlckd "Rear Short Range Radar Sensor Blocked";
BA_ "VNSigAllNodes" SG_ 1184 RSRRSnsrBlckd 1;
BA_ "SignalType" SG_ 1185 RSrrBurstID1 "UNM";
BA_ "SignalLongName" SG_ 1185 RSrrBurstID1 "Rear Short Range Radar Burst ID 1";
BA_ "VNSigAllNodes" SG_ 1185 RSrrBurstID1 1;
BA_ "SignalType" SG_ 1185 RSrrTrkRange1 "UNM";
BA_ "SignalLongName" SG_ 1185 RSrrTrkRange1 "Rear Short Range Radar Track Range 1";
BA_ "VNSigAllNodes" SG_ 1185 RSrrTrkRange1 1;
BA_ "SignalType" SG_ 1185 RSrrTrkRRate1 "SNM";
BA_ "SignalLongName" SG_ 1185 RSrrTrkRRate1 "Rear Short Range Radar Track Range Rate 1";
BA_ "VNSigAllNodes" SG_ 1185 RSrrTrkRRate1 1;
BA_ "SignalType" SG_ 1185 RSrrTrkAzimuth1 "SNM";
BA_ "SignalLongName" SG_ 1185 RSrrTrkAzimuth1 "Rear Short Range Radar Track Azimuth 1";
BA_ "VNSigAllNodes" SG_ 1185 RSrrTrkAzimuth1 1;
BA_ "SignalType" SG_ 1185 RSrrTrkObjID1 "UNM";
BA_ "SignalLongName" SG_ 1185 RSrrTrkObjID1 "Rear Short Range Radar Track Object ID 1";
BA_ "VNSigAllNodes" SG_ 1185 RSrrTrkObjID1 1;
BA_ "SignalType" SG_ 1185 RSrrTrkObjElevation1 "ENM";
BA_ "SignalLongName" SG_ 1185 RSrrTrkObjElevation1 "Rear Short Range Radar Track Object Elevation 1";
BA_ "VNSigAllNodes" SG_ 1185 RSrrTrkObjElevation1 1;
BA_ "SignalType" SG_ 1185 RSrrTrkDynamProp1 "ENM";
BA_ "SignalLongName" SG_ 1185 RSrrTrkDynamProp1 "Rear Short Range Radar Track Dynamic Property 1";
BA_ "VNSigAllNodes" SG_ 1185 RSrrTrkDynamProp1 1;
BA_ "SignalType" SG_ 1185 RSrrTrkMeasStatus1 "ENM";
BA_ "SignalLongName" SG_ 1185 RSrrTrkMeasStatus1 "Rear Short Range Radar Track Measurement Status 1";
BA_ "VNSigAllNodes" SG_ 1185 RSrrTrkMeasStatus1 1;
BA_ "SignalType" SG_ 1185 RSrrTrkObsRange1 "SNM";
BA_ "SignalLongName" SG_ 1185 RSrrTrkObsRange1 "Rear Short Range Radar Track Observed Range 1";
BA_ "VNSigAllNodes" SG_ 1185 RSrrTrkObsRange1 1;
BA_ "SignalType" SG_ 1185 RSrrTrkRawAzimuth1 "SNM";
BA_ "SignalLongName" SG_ 1185 RSrrTrkRawAzimuth1 "Rear Short Range Radar Track Raw Azimuth 1";
BA_ "VNSigAllNodes" SG_ 1185 RSrrTrkRawAzimuth1 1;
BA_ "SignalType" SG_ 1186 RSrrBurstID2 "UNM";
BA_ "SignalLongName" SG_ 1186 RSrrBurstID2 "Rear Short Range Radar Burst ID 2";
BA_ "VNSigAllNodes" SG_ 1186 RSrrBurstID2 1;
BA_ "SignalType" SG_ 1186 RSrrTrkRange2 "UNM";
BA_ "SignalLongName" SG_ 1186 RSrrTrkRange2 "Rear Short Range Radar Track Range 2";
BA_ "VNSigAllNodes" SG_ 1186 RSrrTrkRange2 1;
BA_ "SignalType" SG_ 1186 RSrrTrkRRate2 "SNM";
BA_ "SignalLongName" SG_ 1186 RSrrTrkRRate2 "Rear Short Range Radar Track Range Rate 2";
BA_ "VNSigAllNodes" SG_ 1186 RSrrTrkRRate2 1;
BA_ "SignalType" SG_ 1186 RSrrTrkAzimuth2 "SNM";
BA_ "SignalLongName" SG_ 1186 RSrrTrkAzimuth2 "Rear Short Range Radar Track Azimuth 2";
BA_ "VNSigAllNodes" SG_ 1186 RSrrTrkAzimuth2 1;
BA_ "SignalType" SG_ 1186 RSrrTrkObjID2 "UNM";
BA_ "SignalLongName" SG_ 1186 RSrrTrkObjID2 "Rear Short Range Radar Track Object ID 2";
BA_ "VNSigAllNodes" SG_ 1186 RSrrTrkObjID2 1;
BA_ "SignalType" SG_ 1186 RSrrTrkObjElevation2 "ENM";
BA_ "SignalLongName" SG_ 1186 RSrrTrkObjElevation2 "Rear Short Range Radar Track Object Elevation 2";
BA_ "VNSigAllNodes" SG_ 1186 RSrrTrkObjElevation2 1;
BA_ "SignalType" SG_ 1186 RSrrTrkDynamProp2 "ENM";
BA_ "SignalLongName" SG_ 1186 RSrrTrkDynamProp2 "Rear Range Radar Track Dynamic Property 2";
BA_ "VNSigAllNodes" SG_ 1186 RSrrTrkDynamProp2 1;
BA_ "SignalType" SG_ 1186 RSrrTrkMeasStatus2 "ENM";
BA_ "SignalLongName" SG_ 1186 RSrrTrkMeasStatus2 "Rear Short Range Radar Track Measurement Status 2";
BA_ "VNSigAllNodes" SG_ 1186 RSrrTrkMeasStatus2 1;
BA_ "SignalType" SG_ 1186 RSrrTrkObsRange2 "SNM";
BA_ "SignalLongName" SG_ 1186 RSrrTrkObsRange2 "Rear Short Range Radar Track Observed Range 2";
BA_ "VNSigAllNodes" SG_ 1186 RSrrTrkObsRange2 1;
BA_ "SignalType" SG_ 1186 RSrrTrkRawAzimuth2 "SNM";
BA_ "SignalLongName" SG_ 1186 RSrrTrkRawAzimuth2 "Rear Short Range Radar Track Raw Azimuth 2";
BA_ "VNSigAllNodes" SG_ 1186 RSrrTrkRawAzimuth2 1;
BA_ "SignalType" SG_ 1187 RSrrBurstID3 "UNM";
BA_ "SignalLongName" SG_ 1187 RSrrBurstID3 "Rear Short Range Radar Burst ID 3";
BA_ "VNSigAllNodes" SG_ 1187 RSrrBurstID3 1;
BA_ "SignalType" SG_ 1187 RSrrTrkRange3 "UNM";
BA_ "SignalLongName" SG_ 1187 RSrrTrkRange3 "Rear Short Range Radar Track Range 3";
BA_ "VNSigAllNodes" SG_ 1187 RSrrTrkRange3 1;
BA_ "SignalType" SG_ 1187 RSrrTrkRRate3 "SNM";
BA_ "SignalLongName" SG_ 1187 RSrrTrkRRate3 "Rear Short Range Radar Track Range Rate 3";
BA_ "VNSigAllNodes" SG_ 1187 RSrrTrkRRate3 1;
BA_ "SignalType" SG_ 1187 RSrrTrkAzimuth3 "SNM";
BA_ "SignalLongName" SG_ 1187 RSrrTrkAzimuth3 "Rear Short Range Radar Track Azimuth 3";
BA_ "VNSigAllNodes" SG_ 1187 RSrrTrkAzimuth3 1;
BA_ "SignalType" SG_ 1187 RSrrTrkObjID3 "UNM";
BA_ "SignalLongName" SG_ 1187 RSrrTrkObjID3 "Rear Short Range Radar Track Object ID 3";
BA_ "VNSigAllNodes" SG_ 1187 RSrrTrkObjID3 1;
BA_ "SignalType" SG_ 1187 RSrrTrkObjElevation3 "ENM";
BA_ "SignalLongName" SG_ 1187 RSrrTrkObjElevation3 "Rear Short Range Radar Track Object Elevation 3";
BA_ "VNSigAllNodes" SG_ 1187 RSrrTrkObjElevation3 1;
BA_ "SignalType" SG_ 1187 RSrrTrkDynamProp3 "ENM";
BA_ "SignalLongName" SG_ 1187 RSrrTrkDynamProp3 "Rear Short Range Radar Track Dynamic Property 3";
BA_ "VNSigAllNodes" SG_ 1187 RSrrTrkDynamProp3 1;
BA_ "SignalType" SG_ 1187 RSrrTrkMeasStatus3 "ENM";
BA_ "SignalLongName" SG_ 1187 RSrrTrkMeasStatus3 "Rear Short Range Radar Track Measurement Status 3";
BA_ "VNSigAllNodes" SG_ 1187 RSrrTrkMeasStatus3 1;
BA_ "SignalType" SG_ 1187 RSrrTrkObsRange3 "SNM";
BA_ "SignalLongName" SG_ 1187 RSrrTrkObsRange3 "Rear Short Range Radar Track Observed Range 3";
BA_ "VNSigAllNodes" SG_ 1187 RSrrTrkObsRange3 1;
BA_ "SignalType" SG_ 1187 RSrrTrkRawAzimuth3 "SNM";
BA_ "SignalLongName" SG_ 1187 RSrrTrkRawAzimuth3 "Rear Short Range Radar Track Raw Azimuth 3";
BA_ "VNSigAllNodes" SG_ 1187 RSrrTrkRawAzimuth3 1;
BA_ "SignalType" SG_ 1188 RSrrBurstID4 "UNM";
BA_ "SignalLongName" SG_ 1188 RSrrBurstID4 "Rear Short Range Radar Burst ID 4";
BA_ "VNSigAllNodes" SG_ 1188 RSrrBurstID4 1;
BA_ "SignalType" SG_ 1188 RSrrTrkRange4 "UNM";
BA_ "SignalLongName" SG_ 1188 RSrrTrkRange4 "Rear Short Range Radar Track Range 4";
BA_ "VNSigAllNodes" SG_ 1188 RSrrTrkRange4 1;
BA_ "SignalType" SG_ 1188 RSrrTrkRRate4 "SNM";
BA_ "SignalLongName" SG_ 1188 RSrrTrkRRate4 "Rear Short Range Radar Track Range Rate 4";
BA_ "VNSigAllNodes" SG_ 1188 RSrrTrkRRate4 1;
BA_ "SignalType" SG_ 1188 RSrrTrkAzimuth4 "SNM";
BA_ "SignalLongName" SG_ 1188 RSrrTrkAzimuth4 "Rear Short Range Radar Track Azimuth 4";
BA_ "VNSigAllNodes" SG_ 1188 RSrrTrkAzimuth4 1;
BA_ "SignalType" SG_ 1188 RSrrTrkObjID4 "UNM";
BA_ "SignalLongName" SG_ 1188 RSrrTrkObjID4 "Rear Short Range Radar Track Object ID 4";
BA_ "VNSigAllNodes" SG_ 1188 RSrrTrkObjID4 1;
BA_ "SignalType" SG_ 1188 RSrrTrkObjElevation4 "ENM";
BA_ "SignalLongName" SG_ 1188 RSrrTrkObjElevation4 "Rear Short Range Radar Track Object Elevation 4";
BA_ "VNSigAllNodes" SG_ 1188 RSrrTrkObjElevation4 1;
BA_ "SignalType" SG_ 1188 RSrrTrkDynamProp4 "ENM";
BA_ "SignalLongName" SG_ 1188 RSrrTrkDynamProp4 "Rear Short Range Radar Track Dynamic Property 4";
BA_ "VNSigAllNodes" SG_ 1188 RSrrTrkDynamProp4 1;
BA_ "SignalType" SG_ 1188 RSrrTrkMeasStatus4 "ENM";
BA_ "SignalLongName" SG_ 1188 RSrrTrkMeasStatus4 "Rear Short Range Radar Track Measurement Status 4";
BA_ "VNSigAllNodes" SG_ 1188 RSrrTrkMeasStatus4 1;
BA_ "SignalType" SG_ 1188 RSrrTrkObsRange4 "SNM";
BA_ "SignalLongName" SG_ 1188 RSrrTrkObsRange4 "Rear Short Range Radar Track Observed Range 4";
BA_ "VNSigAllNodes" SG_ 1188 RSrrTrkObsRange4 1;
BA_ "SignalType" SG_ 1188 RSrrTrkRawAzimuth4 "SNM";
BA_ "SignalLongName" SG_ 1188 RSrrTrkRawAzimuth4 "Rear Short Range Radar Track Raw Azimuth 4";
BA_ "VNSigAllNodes" SG_ 1188 RSrrTrkRawAzimuth4 1;
BA_ "SignalType" SG_ 1189 RSrrBurstID5 "UNM";
BA_ "SignalLongName" SG_ 1189 RSrrBurstID5 "Rear Short Range Radar Burst ID 5";
BA_ "VNSigAllNodes" SG_ 1189 RSrrBurstID5 1;
BA_ "SignalType" SG_ 1189 RSrrTrkRange5 "UNM";
BA_ "SignalLongName" SG_ 1189 RSrrTrkRange5 "Rear Short Range Radar Track Range 5";
BA_ "VNSigAllNodes" SG_ 1189 RSrrTrkRange5 1;
BA_ "SignalType" SG_ 1189 RSrrTrkRRate5 "SNM";
BA_ "SignalLongName" SG_ 1189 RSrrTrkRRate5 "Rear Short Range Radar Track Range Rate 5";
BA_ "VNSigAllNodes" SG_ 1189 RSrrTrkRRate5 1;
BA_ "SignalType" SG_ 1189 RSrrTrkAzimuth5 "SNM";
BA_ "SignalLongName" SG_ 1189 RSrrTrkAzimuth5 "Rear Short Range Radar Track Azimuth 5";
BA_ "VNSigAllNodes" SG_ 1189 RSrrTrkAzimuth5 1;
BA_ "SignalType" SG_ 1189 RSrrTrkObjID5 "UNM";
BA_ "SignalLongName" SG_ 1189 RSrrTrkObjID5 "Rear Short Range Radar Track Object ID 5";
BA_ "VNSigAllNodes" SG_ 1189 RSrrTrkObjID5 1;
BA_ "SignalType" SG_ 1189 RSrrTrkObjElevation5 "ENM";
BA_ "SignalLongName" SG_ 1189 RSrrTrkObjElevation5 "Rear Short Range Radar Track Object Elevation 5";
BA_ "VNSigAllNodes" SG_ 1189 RSrrTrkObjElevation5 1;
BA_ "SignalType" SG_ 1189 RSrrTrkDynamProp5 "ENM";
BA_ "SignalLongName" SG_ 1189 RSrrTrkDynamProp5 "Rear Short Range Radar Track Dynamic Property 5";
BA_ "VNSigAllNodes" SG_ 1189 RSrrTrkDynamProp5 1;
BA_ "SignalType" SG_ 1189 RSrrTrkMeasStatus5 "ENM";
BA_ "SignalLongName" SG_ 1189 RSrrTrkMeasStatus5 "Rear Short Range Radar Track Measurement Status 5";
BA_ "VNSigAllNodes" SG_ 1189 RSrrTrkMeasStatus5 1;
BA_ "SignalType" SG_ 1189 RSrrTrkObsRange5 "SNM";
BA_ "SignalLongName" SG_ 1189 RSrrTrkObsRange5 "Rear Short Range Radar Track Observed Range 5";
BA_ "VNSigAllNodes" SG_ 1189 RSrrTrkObsRange5 1;
BA_ "SignalType" SG_ 1189 RSrrTrkRawAzimuth5 "SNM";
BA_ "SignalLongName" SG_ 1189 RSrrTrkRawAzimuth5 "Rear Short Range Radar Track Raw Azimuth 5";
BA_ "VNSigAllNodes" SG_ 1189 RSrrTrkRawAzimuth5 1;
BA_ "SignalType" SG_ 1190 RSrrBurstID6 "UNM";
BA_ "SignalLongName" SG_ 1190 RSrrBurstID6 "Rear Short Range Radar Burst ID 6";
BA_ "VNSigAllNodes" SG_ 1190 RSrrBurstID6 1;
BA_ "SignalType" SG_ 1190 RSrrTrkRange6 "UNM";
BA_ "SignalLongName" SG_ 1190 RSrrTrkRange6 "Rear Short Range Radar Track Range 6";
BA_ "VNSigAllNodes" SG_ 1190 RSrrTrkRange6 1;
BA_ "SignalType" SG_ 1190 RSrrTrkRRate6 "SNM";
BA_ "SignalLongName" SG_ 1190 RSrrTrkRRate6 "Rear Short Range Radar Track Range Rate 6";
BA_ "VNSigAllNodes" SG_ 1190 RSrrTrkRRate6 1;
BA_ "SignalType" SG_ 1190 RSrrTrkAzimuth6 "SNM";
BA_ "SignalLongName" SG_ 1190 RSrrTrkAzimuth6 "Rear Short Range Radar Track Azimuth 6";
BA_ "VNSigAllNodes" SG_ 1190 RSrrTrkAzimuth6 1;
BA_ "SignalType" SG_ 1190 RSrrTrkObjID6 "UNM";
BA_ "SignalLongName" SG_ 1190 RSrrTrkObjID6 "Rear Short Range Radar Track Object ID 6";
BA_ "VNSigAllNodes" SG_ 1190 RSrrTrkObjID6 1;
BA_ "SignalType" SG_ 1190 RSrrTrkObjElevation6 "ENM";
BA_ "SignalLongName" SG_ 1190 RSrrTrkObjElevation6 "Rear Short Range Radar Track Object Elevation 6";
BA_ "VNSigAllNodes" SG_ 1190 RSrrTrkObjElevation6 1;
BA_ "SignalType" SG_ 1190 RSrrTrkDynamProp6 "ENM";
BA_ "SignalLongName" SG_ 1190 RSrrTrkDynamProp6 "Rear Short Range Radar Track Dynamic Property 6";
BA_ "VNSigAllNodes" SG_ 1190 RSrrTrkDynamProp6 1;
BA_ "SignalType" SG_ 1190 RSrrTrkMeasStatus6 "ENM";
BA_ "SignalLongName" SG_ 1190 RSrrTrkMeasStatus6 "Rear Short Range Radar Track Measurement Status 6";
BA_ "VNSigAllNodes" SG_ 1190 RSrrTrkMeasStatus6 1;
BA_ "SignalType" SG_ 1190 RSrrTrkObsRange6 "SNM";
BA_ "SignalLongName" SG_ 1190 RSrrTrkObsRange6 "Rear Short Range Radar Track Observed Range 6";
BA_ "VNSigAllNodes" SG_ 1190 RSrrTrkObsRange6 1;
BA_ "SignalType" SG_ 1190 RSrrTrkRawAzimuth6 "SNM";
BA_ "SignalLongName" SG_ 1190 RSrrTrkRawAzimuth6 "Rear Short Range Radar Track Raw Azimuth 6";
BA_ "VNSigAllNodes" SG_ 1190 RSrrTrkRawAzimuth6 1;
BA_ "SignalType" SG_ 1191 RSrrBurstID7 "UNM";
BA_ "SignalLongName" SG_ 1191 RSrrBurstID7 "Rear Short Range Radar Burst ID 7";
BA_ "VNSigAllNodes" SG_ 1191 RSrrBurstID7 1;
BA_ "SignalType" SG_ 1191 RSrrTrkRange7 "UNM";
BA_ "SignalLongName" SG_ 1191 RSrrTrkRange7 "Rear Short Range Radar Track Range 7";
BA_ "VNSigAllNodes" SG_ 1191 RSrrTrkRange7 1;
BA_ "SignalType" SG_ 1191 RSrrTrkRRate7 "SNM";
BA_ "SignalLongName" SG_ 1191 RSrrTrkRRate7 "Rear Short Range Radar Track Range Rate 7";
BA_ "VNSigAllNodes" SG_ 1191 RSrrTrkRRate7 1;
BA_ "SignalType" SG_ 1191 RSrrTrkAzimuth7 "SNM";
BA_ "SignalLongName" SG_ 1191 RSrrTrkAzimuth7 "Rear Short Range Radar Track Azimuth 7";
BA_ "VNSigAllNodes" SG_ 1191 RSrrTrkAzimuth7 1;
BA_ "SignalType" SG_ 1191 RSrrTrkObjID7 "UNM";
BA_ "SignalLongName" SG_ 1191 RSrrTrkObjID7 "Rear Short Range Radar Track Object ID 7";
BA_ "VNSigAllNodes" SG_ 1191 RSrrTrkObjID7 1;
BA_ "SignalType" SG_ 1191 RSrrTrkObjElevation7 "ENM";
BA_ "SignalLongName" SG_ 1191 RSrrTrkObjElevation7 "Rear Short Range Radar Track Object Elevation 7";
BA_ "VNSigAllNodes" SG_ 1191 RSrrTrkObjElevation7 1;
BA_ "SignalType" SG_ 1191 RSrrTrkDynamProp7 "ENM";
BA_ "SignalLongName" SG_ 1191 RSrrTrkDynamProp7 "Rear Short Range Radar Track Dynamic Property 7";
BA_ "VNSigAllNodes" SG_ 1191 RSrrTrkDynamProp7 1;
BA_ "SignalType" SG_ 1191 RSrrTrkMeasStatus7 "ENM";
BA_ "SignalLongName" SG_ 1191 RSrrTrkMeasStatus7 "Rear Short Range Radar Track Measurement Status 7";
BA_ "VNSigAllNodes" SG_ 1191 RSrrTrkMeasStatus7 1;
BA_ "SignalType" SG_ 1191 RSrrTrkObsRange7 "SNM";
BA_ "SignalLongName" SG_ 1191 RSrrTrkObsRange7 "Rear Short Range Radar Track Observed Range 7";
BA_ "VNSigAllNodes" SG_ 1191 RSrrTrkObsRange7 1;
BA_ "SignalType" SG_ 1191 RSrrTrkRawAzimuth7 "SNM";
BA_ "SignalLongName" SG_ 1191 RSrrTrkRawAzimuth7 "Rear Short Range Radar Track Raw Azimuth 7";
BA_ "VNSigAllNodes" SG_ 1191 RSrrTrkRawAzimuth7 1;
BA_ "SignalType" SG_ 1192 RSrrBurstID8 "UNM";
BA_ "SignalLongName" SG_ 1192 RSrrBurstID8 "Rear Short Range Radar Burst ID 8";
BA_ "VNSigAllNodes" SG_ 1192 RSrrBurstID8 1;
BA_ "SignalType" SG_ 1192 RSrrTrkRange8 "UNM";
BA_ "SignalLongName" SG_ 1192 RSrrTrkRange8 "Rear Short Range Radar Track Range 8";
BA_ "VNSigAllNodes" SG_ 1192 RSrrTrkRange8 1;
BA_ "SignalType" SG_ 1192 RSrrTrkRRate8 "SNM";
BA_ "SignalLongName" SG_ 1192 RSrrTrkRRate8 "Rear Short Range Radar Track Range Rate 8";
BA_ "VNSigAllNodes" SG_ 1192 RSrrTrkRRate8 1;
BA_ "SignalType" SG_ 1192 RSrrTrkAzimuth8 "SNM";
BA_ "SignalLongName" SG_ 1192 RSrrTrkAzimuth8 "Rear Short Range Radar Track Azimuth 8";
BA_ "VNSigAllNodes" SG_ 1192 RSrrTrkAzimuth8 1;
BA_ "SignalType" SG_ 1192 RSrrTrkObjID8 "UNM";
BA_ "SignalLongName" SG_ 1192 RSrrTrkObjID8 "Rear Short Range Radar Track Object ID 8";
BA_ "VNSigAllNodes" SG_ 1192 RSrrTrkObjID8 1;
BA_ "SignalType" SG_ 1192 RSrrTrkObjElevation8 "ENM";
BA_ "SignalLongName" SG_ 1192 RSrrTrkObjElevation8 "Rear Short Range Radar Track Object Elevation 8";
BA_ "VNSigAllNodes" SG_ 1192 RSrrTrkObjElevation8 1;
BA_ "SignalType" SG_ 1192 RSrrTrkDynamProp8 "ENM";
BA_ "SignalLongName" SG_ 1192 RSrrTrkDynamProp8 "Rear Short Range Radar Track Dynamic Property 8";
BA_ "VNSigAllNodes" SG_ 1192 RSrrTrkDynamProp8 1;
BA_ "SignalType" SG_ 1192 RSrrTrkMeasStatus8 "ENM";
BA_ "SignalLongName" SG_ 1192 RSrrTrkMeasStatus8 "Rear Short Range Radar Track Measurement Status 8";
BA_ "VNSigAllNodes" SG_ 1192 RSrrTrkMeasStatus8 1;
BA_ "SignalType" SG_ 1192 RSrrTrkObsRange8 "SNM";
BA_ "SignalLongName" SG_ 1192 RSrrTrkObsRange8 "Rear Short Range Radar Track Observed Range 8";
BA_ "VNSigAllNodes" SG_ 1192 RSrrTrkObsRange8 1;
BA_ "SignalType" SG_ 1192 RSrrTrkRawAzimuth8 "SNM";
BA_ "SignalLongName" SG_ 1192 RSrrTrkRawAzimuth8 "Rear Short Range Radar Track Raw Azimuth 8";
BA_ "VNSigAllNodes" SG_ 1192 RSrrTrkRawAzimuth8 1;
BA_ "SignalType" SG_ 1193 RSrrBurstID9 "UNM";
BA_ "SignalLongName" SG_ 1193 RSrrBurstID9 "Rear Short Range Radar Burst ID 9";
BA_ "VNSigAllNodes" SG_ 1193 RSrrBurstID9 1;
BA_ "SignalType" SG_ 1193 RSrrTrkRange9 "UNM";
BA_ "SignalLongName" SG_ 1193 RSrrTrkRange9 "Rear Short Range Radar Track Range 9";
BA_ "VNSigAllNodes" SG_ 1193 RSrrTrkRange9 1;
BA_ "SignalType" SG_ 1193 RSrrTrkRRate9 "SNM";
BA_ "SignalLongName" SG_ 1193 RSrrTrkRRate9 "Rear Short Range Radar Track Range Rate 9";
BA_ "VNSigAllNodes" SG_ 1193 RSrrTrkRRate9 1;
BA_ "SignalType" SG_ 1193 RSrrTrkAzimuth9 "SNM";
BA_ "SignalLongName" SG_ 1193 RSrrTrkAzimuth9 "Rear Short Range Radar Track Azimuth 9";
BA_ "VNSigAllNodes" SG_ 1193 RSrrTrkAzimuth9 1;
BA_ "SignalType" SG_ 1193 RSrrTrkObjID9 "UNM";
BA_ "SignalLongName" SG_ 1193 RSrrTrkObjID9 "Rear Short Range Radar Track Object ID 9";
BA_ "VNSigAllNodes" SG_ 1193 RSrrTrkObjID9 1;
BA_ "SignalType" SG_ 1193 RSrrTrkObjElevation9 "ENM";
BA_ "SignalLongName" SG_ 1193 RSrrTrkObjElevation9 "Rear Short Range Radar Track Object Elevation 9";
BA_ "VNSigAllNodes" SG_ 1193 RSrrTrkObjElevation9 1;
BA_ "SignalType" SG_ 1193 RSrrTrkDynamProp9 "ENM";
BA_ "SignalLongName" SG_ 1193 RSrrTrkDynamProp9 "Rear Short Range Radar Track Dynamic Property 9";
BA_ "VNSigAllNodes" SG_ 1193 RSrrTrkDynamProp9 1;
BA_ "SignalType" SG_ 1193 RSrrTrkMeasStatus9 "ENM";
BA_ "SignalLongName" SG_ 1193 RSrrTrkMeasStatus9 "Rear Short Range Radar Track Measurement Status 9";
BA_ "VNSigAllNodes" SG_ 1193 RSrrTrkMeasStatus9 1;
BA_ "SignalType" SG_ 1193 RSrrTrkObsRange9 "SNM";
BA_ "SignalLongName" SG_ 1193 RSrrTrkObsRange9 "Rear Short Range Radar Track Observed Range 9";
BA_ "VNSigAllNodes" SG_ 1193 RSrrTrkObsRange9 1;
BA_ "SignalType" SG_ 1193 RSrrTrkRawAzimuth9 "SNM";
BA_ "SignalLongName" SG_ 1193 RSrrTrkRawAzimuth9 "Rear Short Range Radar Track Raw Azimuth 9";
BA_ "VNSigAllNodes" SG_ 1193 RSrrTrkRawAzimuth9 1;
BA_ "SignalType" SG_ 1194 RSrrBurstID10 "UNM";
BA_ "SignalLongName" SG_ 1194 RSrrBurstID10 "Rear Short Range Radar Burst ID 10";
BA_ "VNSigAllNodes" SG_ 1194 RSrrBurstID10 1;
BA_ "SignalType" SG_ 1194 RSrrTrkRange10 "UNM";
BA_ "SignalLongName" SG_ 1194 RSrrTrkRange10 "Rear Short Range Radar Track Range 10";
BA_ "VNSigAllNodes" SG_ 1194 RSrrTrkRange10 1;
BA_ "SignalType" SG_ 1194 RSrrTrkRRate10 "SNM";
BA_ "SignalLongName" SG_ 1194 RSrrTrkRRate10 "Rear Short Range Radar Track Range Rate 10";
BA_ "VNSigAllNodes" SG_ 1194 RSrrTrkRRate10 1;
BA_ "SignalType" SG_ 1194 RSrrTrkAzimuth10 "SNM";
BA_ "SignalLongName" SG_ 1194 RSrrTrkAzimuth10 "Rear Short Range Radar Track Azimuth 10";
BA_ "VNSigAllNodes" SG_ 1194 RSrrTrkAzimuth10 1;
BA_ "SignalType" SG_ 1194 RSrrTrkObjID10 "UNM";
BA_ "SignalLongName" SG_ 1194 RSrrTrkObjID10 "Rear Short Range Radar Track Object ID 10";
BA_ "VNSigAllNodes" SG_ 1194 RSrrTrkObjID10 1;
BA_ "SignalType" SG_ 1194 RSrrTrkObjElevation10 "ENM";
BA_ "SignalLongName" SG_ 1194 RSrrTrkObjElevation10 "Rear Short Range Radar Track Object Elevation 10";
BA_ "VNSigAllNodes" SG_ 1194 RSrrTrkObjElevation10 1;
BA_ "SignalType" SG_ 1194 RSrrTrkDynamProp10 "ENM";
BA_ "SignalLongName" SG_ 1194 RSrrTrkDynamProp10 "Rear Short Range Radar Track Dynamic Property 10";
BA_ "VNSigAllNodes" SG_ 1194 RSrrTrkDynamProp10 1;
BA_ "SignalType" SG_ 1194 RSrrTrkMeasStatus10 "ENM";
BA_ "SignalLongName" SG_ 1194 RSrrTrkMeasStatus10 "Rear Short Range Radar Track Measurement Status 10";
BA_ "VNSigAllNodes" SG_ 1194 RSrrTrkMeasStatus10 1;
BA_ "SignalType" SG_ 1194 RSrrTrkObsRange10 "SNM";
BA_ "SignalLongName" SG_ 1194 RSrrTrkObsRange10 "Rear Short Range Radar Track Observed Range 10";
BA_ "VNSigAllNodes" SG_ 1194 RSrrTrkObsRange10 1;
BA_ "SignalType" SG_ 1194 RSrrTrkRawAzimuth10 "SNM";
BA_ "SignalLongName" SG_ 1194 RSrrTrkRawAzimuth10 "Rear Short Range Radar Track Raw Azimuth 10";
BA_ "VNSigAllNodes" SG_ 1194 RSrrTrkRawAzimuth10 1;
BA_ "SignalType" SG_ 1380 RwdFusTrkA4RollingCnt "UNM";
BA_ "SignalLongName" SG_ 1380 RwdFusTrkA4RollingCnt "Rearward Fusion Track A4 Rolling Count";
BA_ "VNSigAllNodes" SG_ 1380 RwdFusTrkA4RollingCnt 1;
BA_ "SignalType" SG_ 1380 RwdFusTrkA4ObjectID "UNM";
BA_ "SignalLongName" SG_ 1380 RwdFusTrkA4ObjectID "Rearward Fusion Track A4 Object ID";
BA_ "VNSigAllNodes" SG_ 1380 RwdFusTrkA4ObjectID 1;
BA_ "SignalType" SG_ 1380 RwdFusTrkA4MsgIndex "UNM";
BA_ "SignalLongName" SG_ 1380 RwdFusTrkA4MsgIndex "Rearward Fusion Track A4 Message Index";
BA_ "VNSigAllNodes" SG_ 1380 RwdFusTrkA4MsgIndex 1;
BA_ "SignalType" SG_ 1380 RwdFusTrkA4LongPos "SNM";
BA_ "SignalLongName" SG_ 1380 RwdFusTrkA4LongPos "Rearward Fusion Track A4 Longitudinal Position";
BA_ "VNSigAllNodes" SG_ 1380 RwdFusTrkA4LongPos 1;
BA_ "SignalType" SG_ 1380 RwdFusTrkA4RelLongVel "SNM";
BA_ "SignalLongName" SG_ 1380 RwdFusTrkA4RelLongVel "Rearward Fusion Track A4 Relative Longitudinal Velocity";
BA_ "VNSigAllNodes" SG_ 1380 RwdFusTrkA4RelLongVel 1;
BA_ "SignalType" SG_ 1380 RwdFusTrkA4Confidence "ENM";
BA_ "SignalLongName" SG_ 1380 RwdFusTrkA4Confidence "Rearward Fusion Track A4 Confidence";
BA_ "VNSigAllNodes" SG_ 1380 RwdFusTrkA4Confidence 1;
BA_ "SignalType" SG_ 1380 RwdFusTrkA4LatPos "SNM";
BA_ "SignalLongName" SG_ 1380 RwdFusTrkA4LatPos "Rearward Fusion Track A4 Lateral Position";
BA_ "VNSigAllNodes" SG_ 1380 RwdFusTrkA4LatPos 1;
BA_ "SignalType" SG_ 1380 RwdFusTrkA4RelLatVel "SNM";
BA_ "SignalLongName" SG_ 1380 RwdFusTrkA4RelLatVel "Rearward Fusion Track A4 Relative Lateral Velocity";
BA_ "VNSigAllNodes" SG_ 1380 RwdFusTrkA4RelLatVel 1;
BA_ "SignalType" SG_ 1380 RwdFusTrkA4MeasStatus "ENM";
BA_ "SignalLongName" SG_ 1380 RwdFusTrkA4MeasStatus "Rearward Fusion Track A4 Measurement Status";
BA_ "VNSigAllNodes" SG_ 1380 RwdFusTrkA4MeasStatus 1;
BA_ "SignalType" SG_ 1380 RwdFusTrkA4ObjType "ENM";
BA_ "SignalLongName" SG_ 1380 RwdFusTrkA4ObjType "Rearward Fusion Track A4 Object Type";
BA_ "VNSigAllNodes" SG_ 1380 RwdFusTrkA4ObjType 1;
BA_ "SignalType" SG_ 1379 RwdFusTrkA3RollingCnt "UNM";
BA_ "SignalLongName" SG_ 1379 RwdFusTrkA3RollingCnt "Rearward Fusion Track A3 Rolling Count";
BA_ "VNSigAllNodes" SG_ 1379 RwdFusTrkA3RollingCnt 1;
BA_ "SignalType" SG_ 1379 RwdFusTrkA3ObjectID "UNM";
BA_ "SignalLongName" SG_ 1379 RwdFusTrkA3ObjectID "Rearward Fusion Track A3 Object ID";
BA_ "VNSigAllNodes" SG_ 1379 RwdFusTrkA3ObjectID 1;
BA_ "SignalType" SG_ 1379 RwdFusTrkA3MsgIndex "UNM";
BA_ "SignalLongName" SG_ 1379 RwdFusTrkA3MsgIndex "Rearward Fusion Track A3 Message Index";
BA_ "VNSigAllNodes" SG_ 1379 RwdFusTrkA3MsgIndex 1;
BA_ "SignalType" SG_ 1379 RwdFusTrkA3LongPos "SNM";
BA_ "SignalLongName" SG_ 1379 RwdFusTrkA3LongPos "Rearward Fusion Track A3 Longitudinal Position";
BA_ "VNSigAllNodes" SG_ 1379 RwdFusTrkA3LongPos 1;
BA_ "SignalType" SG_ 1379 RwdFusTrkA3RelLongVel "SNM";
BA_ "SignalLongName" SG_ 1379 RwdFusTrkA3RelLongVel "Rearward Fusion Track A3 Relative Longitudinal Velocity";
BA_ "VNSigAllNodes" SG_ 1379 RwdFusTrkA3RelLongVel 1;
BA_ "SignalType" SG_ 1379 RwdFusTrkA3Confidence "ENM";
BA_ "SignalLongName" SG_ 1379 RwdFusTrkA3Confidence "Rearward Fusion Track A3 Confidence";
BA_ "VNSigAllNodes" SG_ 1379 RwdFusTrkA3Confidence 1;
BA_ "SignalType" SG_ 1379 RwdFusTrkA3LatPos "SNM";
BA_ "SignalLongName" SG_ 1379 RwdFusTrkA3LatPos "Rearward Fusion Track A3 Lateral Position";
BA_ "VNSigAllNodes" SG_ 1379 RwdFusTrkA3LatPos 1;
BA_ "SignalType" SG_ 1379 RwdFusTrkA3RelLatVel "SNM";
BA_ "SignalLongName" SG_ 1379 RwdFusTrkA3RelLatVel "Rearward Fusion Track A3 Relative Lateral Velocity";
BA_ "VNSigAllNodes" SG_ 1379 RwdFusTrkA3RelLatVel 1;
BA_ "SignalType" SG_ 1379 RwdFusTrkA3MeasStatus "ENM";
BA_ "SignalLongName" SG_ 1379 RwdFusTrkA3MeasStatus "Rearward Fusion Track A3 Measurement Status";
BA_ "VNSigAllNodes" SG_ 1379 RwdFusTrkA3MeasStatus 1;
BA_ "SignalType" SG_ 1379 RwdFusTrkA3ObjType "ENM";
BA_ "SignalLongName" SG_ 1379 RwdFusTrkA3ObjType "Rearward Fusion Track A3 Object Type";
BA_ "VNSigAllNodes" SG_ 1379 RwdFusTrkA3ObjType 1;
BA_ "SignalType" SG_ 1378 RwdFusTrkA2RollingCnt "UNM";
BA_ "SignalLongName" SG_ 1378 RwdFusTrkA2RollingCnt "Rearward Fusion Track A2 Rolling Count";
BA_ "VNSigAllNodes" SG_ 1378 RwdFusTrkA2RollingCnt 1;
BA_ "SignalType" SG_ 1378 RwdFusTrkA2ObjectID "UNM";
BA_ "SignalLongName" SG_ 1378 RwdFusTrkA2ObjectID "Rearward Fusion Track A2 Object ID";
BA_ "VNSigAllNodes" SG_ 1378 RwdFusTrkA2ObjectID 1;
BA_ "SignalType" SG_ 1378 RwdFusTrkA2MsgIndex "UNM";
BA_ "SignalLongName" SG_ 1378 RwdFusTrkA2MsgIndex "Rearward Fusion Track A2 Message Index";
BA_ "VNSigAllNodes" SG_ 1378 RwdFusTrkA2MsgIndex 1;
BA_ "SignalType" SG_ 1378 RwdFusTrkA2LongPos "SNM";
BA_ "SignalLongName" SG_ 1378 RwdFusTrkA2LongPos "Rearward Fusion Track A2 Longitudinal Position";
BA_ "VNSigAllNodes" SG_ 1378 RwdFusTrkA2LongPos 1;
BA_ "SignalType" SG_ 1378 RwdFusTrkA2RelLongVel "SNM";
BA_ "SignalLongName" SG_ 1378 RwdFusTrkA2RelLongVel "Rearward Fusion Track A2 Relative Longitudinal Velocity";
BA_ "VNSigAllNodes" SG_ 1378 RwdFusTrkA2RelLongVel 1;
BA_ "SignalType" SG_ 1378 RwdFusTrkA2Confidence "ENM";
BA_ "SignalLongName" SG_ 1378 RwdFusTrkA2Confidence "Rearward Fusion Track A2 Confidence";
BA_ "VNSigAllNodes" SG_ 1378 RwdFusTrkA2Confidence 1;
BA_ "SignalType" SG_ 1378 RwdFusTrkA2LatPos "SNM";
BA_ "SignalLongName" SG_ 1378 RwdFusTrkA2LatPos "Rearward Fusion Track A2 Lateral Position";
BA_ "VNSigAllNodes" SG_ 1378 RwdFusTrkA2LatPos 1;
BA_ "SignalType" SG_ 1378 RwdFusTrkA2RelLatVel "SNM";
BA_ "SignalLongName" SG_ 1378 RwdFusTrkA2RelLatVel "Rearward Fusion Track A2 Relative Lateral Velocity";
BA_ "VNSigAllNodes" SG_ 1378 RwdFusTrkA2RelLatVel 1;
BA_ "SignalType" SG_ 1378 RwdFusTrkA2MeasStatus "ENM";
BA_ "SignalLongName" SG_ 1378 RwdFusTrkA2MeasStatus "Rearward Fusion Track A2 Measurement Status";
BA_ "VNSigAllNodes" SG_ 1378 RwdFusTrkA2MeasStatus 1;
BA_ "SignalType" SG_ 1378 RwdFusTrkA2ObjType "ENM";
BA_ "SignalLongName" SG_ 1378 RwdFusTrkA2ObjType "Rearward Fusion Track A2 Object Type";
BA_ "VNSigAllNodes" SG_ 1378 RwdFusTrkA2ObjType 1;
BA_ "SignalType" SG_ 1391 RwdFusTrkA15RollingCnt "UNM";
BA_ "SignalLongName" SG_ 1391 RwdFusTrkA15RollingCnt "Rearward Fusion Track A15 Rolling Count";
BA_ "VNSigAllNodes" SG_ 1391 RwdFusTrkA15RollingCnt 1;
BA_ "SignalType" SG_ 1391 RwdFusTrkA15ObjectID "UNM";
BA_ "SignalLongName" SG_ 1391 RwdFusTrkA15ObjectID "Rearward Fusion Track A15 Object ID";
BA_ "VNSigAllNodes" SG_ 1391 RwdFusTrkA15ObjectID 1;
BA_ "SignalType" SG_ 1391 RwdFusTrkA15MsgIndex "UNM";
BA_ "SignalLongName" SG_ 1391 RwdFusTrkA15MsgIndex "Rearward Fusion Track A15 Message Index";
BA_ "VNSigAllNodes" SG_ 1391 RwdFusTrkA15MsgIndex 1;
BA_ "SignalType" SG_ 1391 RwdFusTrkA15LongPos "SNM";
BA_ "SignalLongName" SG_ 1391 RwdFusTrkA15LongPos "Rearward Fusion Track A15 Longitudinal Position";
BA_ "VNSigAllNodes" SG_ 1391 RwdFusTrkA15LongPos 1;
BA_ "SignalType" SG_ 1391 RwdFusTrkA15RelLongVel "SNM";
BA_ "SignalLongName" SG_ 1391 RwdFusTrkA15RelLongVel "Rearward Fusion Track A15 Relative Longitudinal Velocity";
BA_ "VNSigAllNodes" SG_ 1391 RwdFusTrkA15RelLongVel 1;
BA_ "SignalType" SG_ 1391 RwdFusTrkA15Confidence "ENM";
BA_ "SignalLongName" SG_ 1391 RwdFusTrkA15Confidence "Rearward Fusion Track A15 Confidence";
BA_ "VNSigAllNodes" SG_ 1391 RwdFusTrkA15Confidence 1;
BA_ "SignalType" SG_ 1391 RwdFusTrkA15LatPos "SNM";
BA_ "SignalLongName" SG_ 1391 RwdFusTrkA15LatPos "Rearward Fusion Track A15 Lateral Position";
BA_ "VNSigAllNodes" SG_ 1391 RwdFusTrkA15LatPos 1;
BA_ "SignalType" SG_ 1391 RwdFusTrkA15RelLatVel "SNM";
BA_ "SignalLongName" SG_ 1391 RwdFusTrkA15RelLatVel "Rearward Fusion Track A15 Relative Lateral Velocity";
BA_ "VNSigAllNodes" SG_ 1391 RwdFusTrkA15RelLatVel 1;
BA_ "SignalType" SG_ 1391 RwdFusTrkA15MeasStatus "ENM";
BA_ "SignalLongName" SG_ 1391 RwdFusTrkA15MeasStatus "Rearward Fusion Track A15 Measurement Status";
BA_ "VNSigAllNodes" SG_ 1391 RwdFusTrkA15MeasStatus 1;
BA_ "SignalType" SG_ 1391 RwdFusTrkA15ObjType "ENM";
BA_ "SignalLongName" SG_ 1391 RwdFusTrkA15ObjType "Rearward Fusion Track A15 Object Type";
BA_ "VNSigAllNodes" SG_ 1391 RwdFusTrkA15ObjType 1;
BA_ "SignalType" SG_ 1390 RwdFusTrkA14RollingCnt "UNM";
BA_ "SignalLongName" SG_ 1390 RwdFusTrkA14RollingCnt "Rearward Fusion Track A14 Rolling Count";
BA_ "VNSigAllNodes" SG_ 1390 RwdFusTrkA14RollingCnt 1;
BA_ "SignalType" SG_ 1390 RwdFusTrkA14ObjectID "UNM";
BA_ "SignalLongName" SG_ 1390 RwdFusTrkA14ObjectID "Rearward Fusion Track A14 Object ID";
BA_ "VNSigAllNodes" SG_ 1390 RwdFusTrkA14ObjectID 1;
BA_ "SignalType" SG_ 1390 RwdFusTrkA14MsgIndex "UNM";
BA_ "SignalLongName" SG_ 1390 RwdFusTrkA14MsgIndex "Rearward Fusion Track A14 Message Index";
BA_ "VNSigAllNodes" SG_ 1390 RwdFusTrkA14MsgIndex 1;
BA_ "SignalType" SG_ 1390 RwdFusTrkA14LongPos "SNM";
BA_ "SignalLongName" SG_ 1390 RwdFusTrkA14LongPos "Rearward Fusion Track A14 Longitudinal Position";
BA_ "VNSigAllNodes" SG_ 1390 RwdFusTrkA14LongPos 1;
BA_ "SignalType" SG_ 1390 RwdFusTrkA14RelLongVel "SNM";
BA_ "SignalLongName" SG_ 1390 RwdFusTrkA14RelLongVel "Rearward Fusion Track A14 Relative Longitudinal Velocity";
BA_ "VNSigAllNodes" SG_ 1390 RwdFusTrkA14RelLongVel 1;
BA_ "SignalType" SG_ 1390 RwdFusTrkA14Confidence "ENM";
BA_ "SignalLongName" SG_ 1390 RwdFusTrkA14Confidence "Rearward Fusion Track A14 Confidence";
BA_ "VNSigAllNodes" SG_ 1390 RwdFusTrkA14Confidence 1;
BA_ "SignalType" SG_ 1390 RwdFusTrkA14LatPos "SNM";
BA_ "SignalLongName" SG_ 1390 RwdFusTrkA14LatPos "Rearward Fusion Track A14 Lateral Position";
BA_ "VNSigAllNodes" SG_ 1390 RwdFusTrkA14LatPos 1;
BA_ "SignalType" SG_ 1390 RwdFusTrkA14RelLatVel "SNM";
BA_ "SignalLongName" SG_ 1390 RwdFusTrkA14RelLatVel "Rearward Fusion Track A14 Relative Lateral Velocity";
BA_ "VNSigAllNodes" SG_ 1390 RwdFusTrkA14RelLatVel 1;
BA_ "SignalType" SG_ 1390 RwdFusTrkA14MeasStatus "ENM";
BA_ "SignalLongName" SG_ 1390 RwdFusTrkA14MeasStatus "Rearward Fusion Track A14 Measurement Status";
BA_ "VNSigAllNodes" SG_ 1390 RwdFusTrkA14MeasStatus 1;
BA_ "SignalType" SG_ 1390 RwdFusTrkA14ObjType "ENM";
BA_ "SignalLongName" SG_ 1390 RwdFusTrkA14ObjType "Rearward Fusion Track A14 Object Type";
BA_ "VNSigAllNodes" SG_ 1390 RwdFusTrkA14ObjType 1;
BA_ "SignalType" SG_ 1389 RwdFusTrkA13RollingCnt "UNM";
BA_ "SignalLongName" SG_ 1389 RwdFusTrkA13RollingCnt "Rearward Fusion Track A13 Rolling Count";
BA_ "VNSigAllNodes" SG_ 1389 RwdFusTrkA13RollingCnt 1;
BA_ "SignalType" SG_ 1389 RwdFusTrkA13ObjectID "UNM";
BA_ "SignalLongName" SG_ 1389 RwdFusTrkA13ObjectID "Rearward Fusion Track A13 Object ID";
BA_ "VNSigAllNodes" SG_ 1389 RwdFusTrkA13ObjectID 1;
BA_ "SignalType" SG_ 1389 RwdFusTrkA13MsgIndex "UNM";
BA_ "SignalLongName" SG_ 1389 RwdFusTrkA13MsgIndex "Rearward Fusion Track A13 Message Index";
BA_ "VNSigAllNodes" SG_ 1389 RwdFusTrkA13MsgIndex 1;
BA_ "SignalType" SG_ 1389 RwdFusTrkA13LongPos "SNM";
BA_ "SignalLongName" SG_ 1389 RwdFusTrkA13LongPos "Rearward Fusion Track A13 Longitudinal Position";
BA_ "VNSigAllNodes" SG_ 1389 RwdFusTrkA13LongPos 1;
BA_ "SignalType" SG_ 1389 RwdFusTrkA13RelLongVel "SNM";
BA_ "SignalLongName" SG_ 1389 RwdFusTrkA13RelLongVel "Rearward Fusion Track A13 Relative Longitudinal Velocity";
BA_ "VNSigAllNodes" SG_ 1389 RwdFusTrkA13RelLongVel 1;
BA_ "SignalType" SG_ 1389 RwdFusTrkA13Confidence "ENM";
BA_ "SignalLongName" SG_ 1389 RwdFusTrkA13Confidence "Rearward Fusion Track A13 Confidence";
BA_ "VNSigAllNodes" SG_ 1389 RwdFusTrkA13Confidence 1;
BA_ "SignalType" SG_ 1389 RwdFusTrkA13LatPos "SNM";
BA_ "SignalLongName" SG_ 1389 RwdFusTrkA13LatPos "Rearward Fusion Track A13 Lateral Position";
BA_ "VNSigAllNodes" SG_ 1389 RwdFusTrkA13LatPos 1;
BA_ "SignalType" SG_ 1389 RwdFusTrkA13RelLatVel "SNM";
BA_ "SignalLongName" SG_ 1389 RwdFusTrkA13RelLatVel "Rearward Fusion Track A13 Relative Lateral Velocity";
BA_ "VNSigAllNodes" SG_ 1389 RwdFusTrkA13RelLatVel 1;
BA_ "SignalType" SG_ 1389 RwdFusTrkA13MeasStatus "ENM";
BA_ "SignalLongName" SG_ 1389 RwdFusTrkA13MeasStatus "Rearward Fusion Track A13 Measurement Status";
BA_ "VNSigAllNodes" SG_ 1389 RwdFusTrkA13MeasStatus 1;
BA_ "SignalType" SG_ 1389 RwdFusTrkA13ObjType "ENM";
BA_ "SignalLongName" SG_ 1389 RwdFusTrkA13ObjType "Rearward Fusion Track A13 Object Type";
BA_ "VNSigAllNodes" SG_ 1389 RwdFusTrkA13ObjType 1;
BA_ "SignalType" SG_ 1388 RwdFusTrkA12RollingCnt "UNM";
BA_ "SignalLongName" SG_ 1388 RwdFusTrkA12RollingCnt "Rearward Fusion Track A12 Rolling Count";
BA_ "VNSigAllNodes" SG_ 1388 RwdFusTrkA12RollingCnt 1;
BA_ "SignalType" SG_ 1388 RwdFusTrkA12ObjectID "UNM";
BA_ "SignalLongName" SG_ 1388 RwdFusTrkA12ObjectID "Rearward Fusion Track A12 Object ID";
BA_ "VNSigAllNodes" SG_ 1388 RwdFusTrkA12ObjectID 1;
BA_ "SignalType" SG_ 1388 RwdFusTrkA12MsgIndex "UNM";
BA_ "SignalLongName" SG_ 1388 RwdFusTrkA12MsgIndex "Rearward Fusion Track A12 Message Index";
BA_ "VNSigAllNodes" SG_ 1388 RwdFusTrkA12MsgIndex 1;
BA_ "SignalType" SG_ 1388 RwdFusTrkA12LongPos "SNM";
BA_ "SignalLongName" SG_ 1388 RwdFusTrkA12LongPos "Rearward Fusion Track A12 Longitudinal Position";
BA_ "VNSigAllNodes" SG_ 1388 RwdFusTrkA12LongPos 1;
BA_ "SignalType" SG_ 1388 RwdFusTrkA12RelLongVel "SNM";
BA_ "SignalLongName" SG_ 1388 RwdFusTrkA12RelLongVel "Rearward Fusion Track A12 Relative Longitudinal Velocity";
BA_ "VNSigAllNodes" SG_ 1388 RwdFusTrkA12RelLongVel 1;
BA_ "SignalType" SG_ 1388 RwdFusTrkA12Confidence "ENM";
BA_ "SignalLongName" SG_ 1388 RwdFusTrkA12Confidence "Rearward Fusion Track A12 Confidence";
BA_ "VNSigAllNodes" SG_ 1388 RwdFusTrkA12Confidence 1;
BA_ "SignalType" SG_ 1388 RwdFusTrkA12LatPos "SNM";
BA_ "SignalLongName" SG_ 1388 RwdFusTrkA12LatPos "Rearward Fusion Track A12 Lateral Position";
BA_ "VNSigAllNodes" SG_ 1388 RwdFusTrkA12LatPos 1;
BA_ "SignalType" SG_ 1388 RwdFusTrkA12RelLatVel "SNM";
BA_ "SignalLongName" SG_ 1388 RwdFusTrkA12RelLatVel "Rearward Fusion Track A12 Relative Lateral Velocity";
BA_ "VNSigAllNodes" SG_ 1388 RwdFusTrkA12RelLatVel 1;
BA_ "SignalType" SG_ 1388 RwdFusTrkA12MeasStatus "ENM";
BA_ "SignalLongName" SG_ 1388 RwdFusTrkA12MeasStatus "Rearward Fusion Track A12 Measurement Status";
BA_ "VNSigAllNodes" SG_ 1388 RwdFusTrkA12MeasStatus 1;
BA_ "SignalType" SG_ 1388 RwdFusTrkA12ObjType "ENM";
BA_ "SignalLongName" SG_ 1388 RwdFusTrkA12ObjType "Rearward Fusion Track A12 Object Type";
BA_ "VNSigAllNodes" SG_ 1388 RwdFusTrkA12ObjType 1;
BA_ "SignalType" SG_ 1387 RwdFusTrkA11RollingCnt "UNM";
BA_ "SignalLongName" SG_ 1387 RwdFusTrkA11RollingCnt "Rearward Fusion Track A11 Rolling Count";
BA_ "VNSigAllNodes" SG_ 1387 RwdFusTrkA11RollingCnt 1;
BA_ "SignalType" SG_ 1387 RwdFusTrkA11ObjectID "UNM";
BA_ "SignalLongName" SG_ 1387 RwdFusTrkA11ObjectID "Rearward Fusion Track A11 Object ID";
BA_ "VNSigAllNodes" SG_ 1387 RwdFusTrkA11ObjectID 1;
BA_ "SignalType" SG_ 1387 RwdFusTrkA11MsgIndex "UNM";
BA_ "SignalLongName" SG_ 1387 RwdFusTrkA11MsgIndex "Rearward Fusion Track A11 Message Index";
BA_ "VNSigAllNodes" SG_ 1387 RwdFusTrkA11MsgIndex 1;
BA_ "SignalType" SG_ 1387 RwdFusTrkA11LongPos "SNM";
BA_ "SignalLongName" SG_ 1387 RwdFusTrkA11LongPos "Rearward Fusion Track A11 Longitudinal Position";
BA_ "VNSigAllNodes" SG_ 1387 RwdFusTrkA11LongPos 1;
BA_ "SignalType" SG_ 1387 RwdFusTrkA11RelLongVel "SNM";
BA_ "SignalLongName" SG_ 1387 RwdFusTrkA11RelLongVel "Rearward Fusion Track A11 Relative Longitudinal Velocity";
BA_ "VNSigAllNodes" SG_ 1387 RwdFusTrkA11RelLongVel 1;
BA_ "SignalType" SG_ 1387 RwdFusTrkA11Confidence "ENM";
BA_ "SignalLongName" SG_ 1387 RwdFusTrkA11Confidence "Rearward Fusion Track A11 Confidence";
BA_ "VNSigAllNodes" SG_ 1387 RwdFusTrkA11Confidence 1;
BA_ "SignalType" SG_ 1387 RwdFusTrkA11LatPos "SNM";
BA_ "SignalLongName" SG_ 1387 RwdFusTrkA11LatPos "Rearward Fusion Track A11 Lateral Position";
BA_ "VNSigAllNodes" SG_ 1387 RwdFusTrkA11LatPos 1;
BA_ "SignalType" SG_ 1387 RwdFusTrkA11RelLatVel "SNM";
BA_ "SignalLongName" SG_ 1387 RwdFusTrkA11RelLatVel "Rearward Fusion Track A11 Relative Lateral Velocity";
BA_ "VNSigAllNodes" SG_ 1387 RwdFusTrkA11RelLatVel 1;
BA_ "SignalType" SG_ 1387 RwdFusTrkA11MeasStatus "ENM";
BA_ "SignalLongName" SG_ 1387 RwdFusTrkA11MeasStatus "Rearward Fusion Track A11 Measurement Status";
BA_ "VNSigAllNodes" SG_ 1387 RwdFusTrkA11MeasStatus 1;
BA_ "SignalType" SG_ 1387 RwdFusTrkA11ObjType "ENM";
BA_ "SignalLongName" SG_ 1387 RwdFusTrkA11ObjType "Rearward Fusion Track A11 Object Type";
BA_ "VNSigAllNodes" SG_ 1387 RwdFusTrkA11ObjType 1;
BA_ "SignalType" SG_ 1386 RwdFusTrkA10RelLatVel "SNM";
BA_ "SignalLongName" SG_ 1386 RwdFusTrkA10RelLatVel "Rearward Fusion Track A10 Relative Lateral Velocity";
BA_ "VNSigAllNodes" SG_ 1386 RwdFusTrkA10RelLatVel 1;
BA_ "SignalType" SG_ 1386 RwdFusTrkA10MeasStatus "ENM";
BA_ "SignalLongName" SG_ 1386 RwdFusTrkA10MeasStatus "Rearward Fusion Track A10 Measurement Status";
BA_ "VNSigAllNodes" SG_ 1386 RwdFusTrkA10MeasStatus 1;
BA_ "SignalType" SG_ 1386 RwdFusTrkA10ObjType "ENM";
BA_ "SignalLongName" SG_ 1386 RwdFusTrkA10ObjType "Rearward Fusion Track A10 Object Type";
BA_ "VNSigAllNodes" SG_ 1386 RwdFusTrkA10ObjType 1;
BA_ "SignalType" SG_ 1386 RwdFusTrkA10RollingCnt "UNM";
BA_ "SignalLongName" SG_ 1386 RwdFusTrkA10RollingCnt "Rearward Fusion Track A10 Rolling Count";
BA_ "VNSigAllNodes" SG_ 1386 RwdFusTrkA10RollingCnt 1;
BA_ "SignalType" SG_ 1386 RwdFusTrkA10ObjectID "UNM";
BA_ "SignalLongName" SG_ 1386 RwdFusTrkA10ObjectID "Rearward Fusion Track A10 Object ID";
BA_ "VNSigAllNodes" SG_ 1386 RwdFusTrkA10ObjectID 1;
BA_ "SignalType" SG_ 1386 RwdFusTrkA10MsgIndex "UNM";
BA_ "SignalLongName" SG_ 1386 RwdFusTrkA10MsgIndex "Rearward Fusion Track A10 Message Index";
BA_ "VNSigAllNodes" SG_ 1386 RwdFusTrkA10MsgIndex 1;
BA_ "SignalType" SG_ 1386 RwdFusTrkA10LongPos "SNM";
BA_ "SignalLongName" SG_ 1386 RwdFusTrkA10LongPos "Rearward Fusion Track A10 Longitudinal Position";
BA_ "VNSigAllNodes" SG_ 1386 RwdFusTrkA10LongPos 1;
BA_ "SignalType" SG_ 1386 RwdFusTrkA10RelLongVel "SNM";
BA_ "SignalLongName" SG_ 1386 RwdFusTrkA10RelLongVel "Rearward Fusion Track A10 Relative Longitudinal Velocity";
BA_ "VNSigAllNodes" SG_ 1386 RwdFusTrkA10RelLongVel 1;
BA_ "SignalType" SG_ 1386 RwdFusTrkA10Confidence "ENM";
BA_ "SignalLongName" SG_ 1386 RwdFusTrkA10Confidence "Rearward Fusion Track A10 Confidence";
BA_ "VNSigAllNodes" SG_ 1386 RwdFusTrkA10Confidence 1;
BA_ "SignalType" SG_ 1386 RwdFusTrkA10LatPos "SNM";
BA_ "SignalLongName" SG_ 1386 RwdFusTrkA10LatPos "Rearward Fusion Track A10 Lateral Position";
BA_ "VNSigAllNodes" SG_ 1386 RwdFusTrkA10LatPos 1;
BA_ "SignalType" SG_ 1377 RwdFusTrkA1RollingCnt "UNM";
BA_ "SignalLongName" SG_ 1377 RwdFusTrkA1RollingCnt "Rearward Fusion Track A1 Rolling Count";
BA_ "VNSigAllNodes" SG_ 1377 RwdFusTrkA1RollingCnt 1;
BA_ "SignalType" SG_ 1377 RwdFusTrkA1ObjectID "UNM";
BA_ "SignalLongName" SG_ 1377 RwdFusTrkA1ObjectID "Rearward Fusion Track A1 Object ID";
BA_ "VNSigAllNodes" SG_ 1377 RwdFusTrkA1ObjectID 1;
BA_ "SignalType" SG_ 1377 RwdFusTrkA1MsgIndex "UNM";
BA_ "SignalLongName" SG_ 1377 RwdFusTrkA1MsgIndex "Rearward Fusion Track A1 Message Index";
BA_ "VNSigAllNodes" SG_ 1377 RwdFusTrkA1MsgIndex 1;
BA_ "SignalType" SG_ 1377 RwdFusTrkA1LongPos "SNM";
BA_ "SignalLongName" SG_ 1377 RwdFusTrkA1LongPos "Rearward Fusion Track A1 Longitudinal Position";
BA_ "VNSigAllNodes" SG_ 1377 RwdFusTrkA1LongPos 1;
BA_ "SignalType" SG_ 1377 RwdFusTrkA1RelLongVel "SNM";
BA_ "SignalLongName" SG_ 1377 RwdFusTrkA1RelLongVel "Rearward Fusion Track A1 Relative Longitudinal Velocity";
BA_ "VNSigAllNodes" SG_ 1377 RwdFusTrkA1RelLongVel 1;
BA_ "SignalType" SG_ 1377 RwdFusTrkA1Confidence "ENM";
BA_ "SignalLongName" SG_ 1377 RwdFusTrkA1Confidence "Rearward Fusion Track A1 Confidence";
BA_ "VNSigAllNodes" SG_ 1377 RwdFusTrkA1Confidence 1;
BA_ "SignalType" SG_ 1377 RwdFusTrkA1LatPos "SNM";
BA_ "SignalLongName" SG_ 1377 RwdFusTrkA1LatPos "Rearward Fusion Track A1 Lateral Position";
BA_ "VNSigAllNodes" SG_ 1377 RwdFusTrkA1LatPos 1;
BA_ "SignalType" SG_ 1377 RwdFusTrkA1RelLatVel "SNM";
BA_ "SignalLongName" SG_ 1377 RwdFusTrkA1RelLatVel "Rearward Fusion Track A1 Relative Lateral Velocity";
BA_ "VNSigAllNodes" SG_ 1377 RwdFusTrkA1RelLatVel 1;
BA_ "SignalType" SG_ 1377 RwdFusTrkA1MeasStatus "ENM";
BA_ "SignalLongName" SG_ 1377 RwdFusTrkA1MeasStatus "Rearward Fusion Track A1 Measurement Status";
BA_ "VNSigAllNodes" SG_ 1377 RwdFusTrkA1MeasStatus 1;
BA_ "SignalType" SG_ 1377 RwdFusTrkA1ObjType "ENM";
BA_ "SignalLongName" SG_ 1377 RwdFusTrkA1ObjType "Rearward Fusion Track A1 Object Type";
BA_ "VNSigAllNodes" SG_ 1377 RwdFusTrkA1ObjType 1;
BA_ "SignalType" SG_ 1410 VBAxleTrqRqActv "BLN";
BA_ "SignalLongName" SG_ 1410 VBAxleTrqRqActv "Vrtual Bumper Axle Torque Request Active";
BA_ "VNSigAllNodes" SG_ 1410 VBAxleTrqRqActv 1;
BA_ "SignalType" SG_ 1410 VBBrkRqActv "BLN";
BA_ "SignalLongName" SG_ 1410 VBBrkRqActv "Virtual Bumper Brake request Active";
BA_ "VNSigAllNodes" SG_ 1410 VBBrkRqActv 1;
BA_ "SignalType" SG_ 1410 VBBrkCtrlSt "ENM";
BA_ "SignalLongName" SG_ 1410 VBBrkCtrlSt "Virtual Bumper Brake Control Status";
BA_ "VNSigAllNodes" SG_ 1410 VBBrkCtrlSt 1;
BA_ "SignalType" SG_ 1410 UpaBrkCtrlSt "ENM";
BA_ "SignalLongName" SG_ 1410 UpaBrkCtrlSt "UPA Brake Control Status";
BA_ "VNSigAllNodes" SG_ 1410 UpaBrkCtrlSt 1;
BA_ "SignalType" SG_ 1410 PASysStatus "ENM";
BA_ "SignalLongName" SG_ 1410 PASysStatus "Park Assistance System Status";
BA_ "VNSigAllNodes" SG_ 1410 PASysStatus 1;
BA_ "SignalType" SG_ 1410 PAWarningSt "ENM";
BA_ "SignalLongName" SG_ 1410 PAWarningSt "Park Assist Warning State";
BA_ "VNSigAllNodes" SG_ 1410 PAWarningSt 1;
BA_ "SignalType" SG_ 1410 PAFrstDtctWrng "BLN";
BA_ "SignalLongName" SG_ 1410 PAFrstDtctWrng "Park assist First Detect Warning";
BA_ "VNSigAllNodes" SG_ 1410 PAFrstDtctWrng 1;
BA_ "SignalType" SG_ 1410 BrkPlsRqst "BLN";
BA_ "SignalLongName" SG_ 1410 BrkPlsRqst "Brake Pulse Request";
BA_ "VNSigAllNodes" SG_ 1410 BrkPlsRqst 1;
BA_ "SignalType" SG_ 1410 BWWarningSt "ENM";
BA_ "SignalLongName" SG_ 1410 BWWarningSt "Backup Warning Warning State";
BA_ "VNSigAllNodes" SG_ 1410 BWWarningSt 1;
BA_ "SignalType" SG_ 1410 BWFrstDtctWrng "BLN";
BA_ "SignalLongName" SG_ 1410 BWFrstDtctWrng "Back Up warning First detect warning";
BA_ "VNSigAllNodes" SG_ 1410 BWFrstDtctWrng 1;
BA_ "SignalType" SG_ 1216 LFSRRNumValidTargets "UNM";
BA_ "SignalLongName" SG_ 1216 LFSRRNumValidTargets "Left Front Short Range Radar Number of Valid Targets";
BA_ "VNSigAllNodes" SG_ 1216 LFSRRNumValidTargets 1;
BA_ "SignalType" SG_ 1216 LFSrrRollingCnt "UNM";
BA_ "SignalLongName" SG_ 1216 LFSrrRollingCnt "Left Front Short Range Radar Rolling Count";
BA_ "VNSigAllNodes" SG_ 1216 LFSrrRollingCnt 1;
BA_ "SignalType" SG_ 1216 LFSRRModeCmdFdbk "ENM";
BA_ "SignalLongName" SG_ 1216 LFSRRModeCmdFdbk "Left Front Short Range Radar Mode Command Feedback";
BA_ "VNSigAllNodes" SG_ 1216 LFSRRModeCmdFdbk 1;
BA_ "SignalType" SG_ 1216 LFSrrTimeStampV "ENM";
BA_ "SignalLongName" SG_ 1216 LFSrrTimeStampV "Left Front Short Range Radar Time Stamp Validity";
BA_ "VNSigAllNodes" SG_ 1216 LFSrrTimeStampV 1;
BA_ "SignalType" SG_ 1216 LFSrrTimeStamp "UNM";
BA_ "SignalLongName" SG_ 1216 LFSrrTimeStamp "Left Front Short Range Radar Time Stamp";
BA_ "VNSigAllNodes" SG_ 1216 LFSrrTimeStamp 1;
BA_ "SignalType" SG_ 1216 LFSrrBurstChecksum "UNM";
BA_ "SignalLongName" SG_ 1216 LFSrrBurstChecksum "Left Front Short Range Radar Burst Checksum";
BA_ "VNSigAllNodes" SG_ 1216 LFSrrBurstChecksum 1;
BA_ "SignalType" SG_ 1216 LFSRRVltgOutRngLo "BLN";
BA_ "SignalLongName" SG_ 1216 LFSRRVltgOutRngLo "Left Front Short Range Radar Voltage Out Of Range Low";
BA_ "VNSigAllNodes" SG_ 1216 LFSRRVltgOutRngLo 1;
BA_ "SignalType" SG_ 1216 LFSRRVltgOutRngHi "BLN";
BA_ "SignalLongName" SG_ 1216 LFSRRVltgOutRngHi "Left Front Short Range Radar Voltage out of Range High";
BA_ "VNSigAllNodes" SG_ 1216 LFSRRVltgOutRngHi 1;
BA_ "SignalType" SG_ 1216 LFSRRSvcAlgnInPrcs "BLN";
BA_ "SignalLongName" SG_ 1216 LFSRRSvcAlgnInPrcs "Left Front Short Range Radar Service Alignment in Process";
BA_ "VNSigAllNodes" SG_ 1216 LFSRRSvcAlgnInPrcs 1;
BA_ "SignalType" SG_ 1216 LFSRRSnsrBlckd "BLN";
BA_ "SignalLongName" SG_ 1216 LFSRRSnsrBlckd "Left Front Short Range Radar Sensor Blocked";
BA_ "VNSigAllNodes" SG_ 1216 LFSRRSnsrBlckd 1;
BA_ "SignalType" SG_ 1216 LFSRRSnstvFltPrsntInt "BLN";
BA_ "SignalLongName" SG_ 1216 LFSRRSnstvFltPrsntInt "Left Front Short Range Radar Sensitivity Fault Present, Internal";
BA_ "VNSigAllNodes" SG_ 1216 LFSRRSnstvFltPrsntInt 1;
BA_ "SignalType" SG_ 1216 LFSRRPlntAlgnInProc "BLN";
BA_ "SignalLongName" SG_ 1216 LFSRRPlntAlgnInProc "Left Front Short Range Radar Plant Alignment in Process";
BA_ "VNSigAllNodes" SG_ 1216 LFSRRPlntAlgnInProc 1;
BA_ "SignalType" SG_ 1216 LFSRRMsalgnYawRt "BLN";
BA_ "SignalLongName" SG_ 1216 LFSRRMsalgnYawRt "Left Front Short Range Radar Misalignment Yaw Right";
BA_ "VNSigAllNodes" SG_ 1216 LFSRRMsalgnYawRt 1;
BA_ "SignalType" SG_ 1216 LFSRRMsalgnYawLt "BLN";
BA_ "SignalLongName" SG_ 1216 LFSRRMsalgnYawLt "Left Front Short Range Radar Misalignment Yaw Left";
BA_ "VNSigAllNodes" SG_ 1216 LFSRRMsalgnYawLt 1;
BA_ "SignalType" SG_ 1216 LFSRRMsalgnRllRt "BLN";
BA_ "SignalLongName" SG_ 1216 LFSRRMsalgnRllRt "Left Front Short Range Radar Misalignment Roll Right";
BA_ "VNSigAllNodes" SG_ 1216 LFSRRMsalgnRllRt 1;
BA_ "SignalType" SG_ 1216 LFSRRMsalgnRllLt "BLN";
BA_ "SignalLongName" SG_ 1216 LFSRRMsalgnRllLt "Left Front Short Range Radar Misalignment Roll Left";
BA_ "VNSigAllNodes" SG_ 1216 LFSRRMsalgnRllLt 1;
BA_ "SignalType" SG_ 1216 LFSRRMsalgnPtchUp "BLN";
BA_ "SignalLongName" SG_ 1216 LFSRRMsalgnPtchUp "Left Front Short Range Radar Misalignment Pitch Up";
BA_ "VNSigAllNodes" SG_ 1216 LFSRRMsalgnPtchUp 1;
BA_ "SignalType" SG_ 1216 LFSRRMsalgnPtchDn "BLN";
BA_ "SignalLongName" SG_ 1216 LFSRRMsalgnPtchDn "Left Front Short Range Radar Misalignment Pitch Down";
BA_ "VNSigAllNodes" SG_ 1216 LFSRRMsalgnPtchDn 1;
BA_ "SignalType" SG_ 1216 LFSRRInitDiagCmplt "BLN";
BA_ "SignalLongName" SG_ 1216 LFSRRInitDiagCmplt "Left Front Short Range Radar Initialization Diagnostics Successfully Completed";
BA_ "VNSigAllNodes" SG_ 1216 LFSRRInitDiagCmplt 1;
BA_ "SignalType" SG_ 1216 LFSRRHWFltPrsntInt "BLN";
BA_ "SignalLongName" SG_ 1216 LFSRRHWFltPrsntInt "Left Front Short Range Radar Hardware Fault Present, Internal";
BA_ "VNSigAllNodes" SG_ 1216 LFSRRHWFltPrsntInt 1;
BA_ "SignalType" SG_ 1216 LFSRRExtIntrfrnc "BLN";
BA_ "SignalLongName" SG_ 1216 LFSRRExtIntrfrnc "Left Front Short Range Radar External Interference";
BA_ "VNSigAllNodes" SG_ 1216 LFSRRExtIntrfrnc 1;
BA_ "SignalType" SG_ 1216 LFSRRDiagSpare "BLN";
BA_ "SignalLongName" SG_ 1216 LFSRRDiagSpare "Left Front Short Range Radar Diagnostic Spare";
BA_ "VNSigAllNodes" SG_ 1216 LFSRRDiagSpare 1;
BA_ "SignalType" SG_ 1216 LFSRRCANSgnlSpvFld "BLN";
BA_ "SignalLongName" SG_ 1216 LFSRRCANSgnlSpvFld "Left Front Short Range Radar CAN Signal Supervision Failed";
BA_ "VNSigAllNodes" SG_ 1216 LFSRRCANSgnlSpvFld 1;
BA_ "SignalType" SG_ 1216 LFSRRCANRxErr "BLN";
BA_ "SignalLongName" SG_ 1216 LFSRRCANRxErr "Left Front Short Range Radar CAN Rx Error";
BA_ "VNSigAllNodes" SG_ 1216 LFSRRCANRxErr 1;
BA_ "SignalType" SG_ 1216 LFSRRCANIDAddrsUnsbl "BLN";
BA_ "SignalLongName" SG_ 1216 LFSRRCANIDAddrsUnsbl "Left Front Short Range Radar CAN ID Address Unstable";
BA_ "VNSigAllNodes" SG_ 1216 LFSRRCANIDAddrsUnsbl 1;
BA_ "SignalType" SG_ 1216 LFSRRAntTngFltPrsnt "BLN";
BA_ "SignalLongName" SG_ 1216 LFSRRAntTngFltPrsnt "Left Front Short Range Radar Antenna Tuning Fault Present";
BA_ "VNSigAllNodes" SG_ 1216 LFSRRAntTngFltPrsnt 1;
BA_ "SignalType" SG_ 1216 LFSRRAmbTmpOutRngLw "BLN";
BA_ "SignalLongName" SG_ 1216 LFSRRAmbTmpOutRngLw "Left Front Short Range Radar Ambient Temperature Out of Range Low";
BA_ "VNSigAllNodes" SG_ 1216 LFSRRAmbTmpOutRngLw 1;
BA_ "SignalType" SG_ 1216 LFSRRAmbTmpOutRngHi "BLN";
BA_ "SignalLongName" SG_ 1216 LFSRRAmbTmpOutRngHi "Left Front Short Range Radar Ambient Temperature Out of Range High";
BA_ "VNSigAllNodes" SG_ 1216 LFSRRAmbTmpOutRngHi 1;
BA_ "SignalType" SG_ 1216 LFSRRAlgnFltPrsnt "BLN";
BA_ "SignalLongName" SG_ 1216 LFSRRAlgnFltPrsnt "Left Front Short Range Radar Alignment Fault Present";
BA_ "VNSigAllNodes" SG_ 1216 LFSRRAlgnFltPrsnt 1;
BA_ "SignalType" SG_ 1217 LFSrrBurstID1 "UNM";
BA_ "SignalLongName" SG_ 1217 LFSrrBurstID1 "Left Front Short Range Radar Burst ID 1";
BA_ "VNSigAllNodes" SG_ 1217 LFSrrBurstID1 1;
BA_ "SignalType" SG_ 1217 LFSrrTrkRange1 "UNM";
BA_ "SignalLongName" SG_ 1217 LFSrrTrkRange1 "Left Front Short Range Radar Track Range 1";
BA_ "VNSigAllNodes" SG_ 1217 LFSrrTrkRange1 1;
BA_ "SignalType" SG_ 1217 LFSrrTrkRRate1 "SNM";
BA_ "SignalLongName" SG_ 1217 LFSrrTrkRRate1 "Left Front Short Range Radar Track Range Rate 1";
BA_ "VNSigAllNodes" SG_ 1217 LFSrrTrkRRate1 1;
BA_ "SignalType" SG_ 1217 LFSrrTrkAzimuth1 "SNM";
BA_ "SignalLongName" SG_ 1217 LFSrrTrkAzimuth1 "Left Front Short Range Radar Track Azimuth 1";
BA_ "VNSigAllNodes" SG_ 1217 LFSrrTrkAzimuth1 1;
BA_ "SignalType" SG_ 1217 LFSrrTrkObjID1 "UNM";
BA_ "SignalLongName" SG_ 1217 LFSrrTrkObjID1 "Left Front Short Range Radar Track Object ID 1";
BA_ "VNSigAllNodes" SG_ 1217 LFSrrTrkObjID1 1;
BA_ "SignalType" SG_ 1217 LFSrrTrkObjElevation1 "ENM";
BA_ "SignalLongName" SG_ 1217 LFSrrTrkObjElevation1 "Left Front Short Range Radar Track Object Elevation 1";
BA_ "VNSigAllNodes" SG_ 1217 LFSrrTrkObjElevation1 1;
BA_ "SignalType" SG_ 1217 LFSrrTrkDynamProp1 "ENM";
BA_ "SignalLongName" SG_ 1217 LFSrrTrkDynamProp1 "Left Front Short Range Radar Track Dynamic Property 1";
BA_ "VNSigAllNodes" SG_ 1217 LFSrrTrkDynamProp1 1;
BA_ "SignalType" SG_ 1217 LFSrrTrkMeasStatus1 "ENM";
BA_ "SignalLongName" SG_ 1217 LFSrrTrkMeasStatus1 "Left Front Short Range Radar Track Measurement Status 1";
BA_ "VNSigAllNodes" SG_ 1217 LFSrrTrkMeasStatus1 1;
BA_ "SignalType" SG_ 1217 LFSrrTrkObsRange1 "SNM";
BA_ "SignalLongName" SG_ 1217 LFSrrTrkObsRange1 "Left Front Short Range Radar Track Observed Range 1";
BA_ "VNSigAllNodes" SG_ 1217 LFSrrTrkObsRange1 1;
BA_ "SignalType" SG_ 1217 LFSrrTrkRawAzimuth1 "SNM";
BA_ "SignalLongName" SG_ 1217 LFSrrTrkRawAzimuth1 "Left Front Short Range Radar Track Raw Azimuth 1";
BA_ "VNSigAllNodes" SG_ 1217 LFSrrTrkRawAzimuth1 1;
BA_ "SignalType" SG_ 1218 LFSrrBurstID2 "UNM";
BA_ "SignalLongName" SG_ 1218 LFSrrBurstID2 "Left Front Short Range Radar Burst ID 2";
BA_ "VNSigAllNodes" SG_ 1218 LFSrrBurstID2 1;
BA_ "SignalType" SG_ 1218 LFSrrTrkRange2 "UNM";
BA_ "SignalLongName" SG_ 1218 LFSrrTrkRange2 "Left Front Short Range Radar Track Range 2";
BA_ "VNSigAllNodes" SG_ 1218 LFSrrTrkRange2 1;
BA_ "SignalType" SG_ 1218 LFSrrTrkRRate2 "SNM";
BA_ "SignalLongName" SG_ 1218 LFSrrTrkRRate2 "Left Front Short Range Radar Track Range Rate 2";
BA_ "VNSigAllNodes" SG_ 1218 LFSrrTrkRRate2 1;
BA_ "SignalType" SG_ 1218 LFSrrTrkAzimuth2 "SNM";
BA_ "SignalLongName" SG_ 1218 LFSrrTrkAzimuth2 "Left Front Short Range Radar Track Azimuth 2";
BA_ "VNSigAllNodes" SG_ 1218 LFSrrTrkAzimuth2 1;
BA_ "SignalType" SG_ 1218 LFSrrTrkObjID2 "UNM";
BA_ "SignalLongName" SG_ 1218 LFSrrTrkObjID2 "Left Front Short Range Radar Track Object ID 2";
BA_ "VNSigAllNodes" SG_ 1218 LFSrrTrkObjID2 1;
BA_ "SignalType" SG_ 1218 LFSrrTrkObjElevation2 "ENM";
BA_ "SignalLongName" SG_ 1218 LFSrrTrkObjElevation2 "Left Front Short Range Radar Track Object Elevation 2";
BA_ "VNSigAllNodes" SG_ 1218 LFSrrTrkObjElevation2 1;
BA_ "SignalType" SG_ 1218 LFSrrTrkDynamProp2 "ENM";
BA_ "SignalLongName" SG_ 1218 LFSrrTrkDynamProp2 "Left Front Short Range Radar Track Dynamic Property 2";
BA_ "VNSigAllNodes" SG_ 1218 LFSrrTrkDynamProp2 1;
BA_ "SignalType" SG_ 1218 LFSrrTrkMeasStatus2 "ENM";
BA_ "SignalLongName" SG_ 1218 LFSrrTrkMeasStatus2 "Left Front Short Range Radar Track Measurement Status 2";
BA_ "VNSigAllNodes" SG_ 1218 LFSrrTrkMeasStatus2 1;
BA_ "SignalType" SG_ 1218 LFSrrTrkObsRange2 "SNM";
BA_ "SignalLongName" SG_ 1218 LFSrrTrkObsRange2 "Left Front Short Range Radar Track Observed Range 2";
BA_ "VNSigAllNodes" SG_ 1218 LFSrrTrkObsRange2 1;
BA_ "SignalType" SG_ 1218 LFSrrTrkRawAzimuth2 "SNM";
BA_ "SignalLongName" SG_ 1218 LFSrrTrkRawAzimuth2 "Left Front Short Range Radar Track Raw Azimuth 2";
BA_ "VNSigAllNodes" SG_ 1218 LFSrrTrkRawAzimuth2 1;
BA_ "SignalType" SG_ 1219 LFSrrBurstID3 "UNM";
BA_ "SignalLongName" SG_ 1219 LFSrrBurstID3 "Left Front Short Range Radar Burst ID 3";
BA_ "VNSigAllNodes" SG_ 1219 LFSrrBurstID3 1;
BA_ "SignalType" SG_ 1219 LFSrrTrkRange3 "UNM";
BA_ "SignalLongName" SG_ 1219 LFSrrTrkRange3 "Left Front Short Range Radar Track Range 3";
BA_ "VNSigAllNodes" SG_ 1219 LFSrrTrkRange3 1;
BA_ "SignalType" SG_ 1219 LFSrrTrkRRate3 "SNM";
BA_ "SignalLongName" SG_ 1219 LFSrrTrkRRate3 "Left Front Short Range Radar Track Range Rate 3";
BA_ "VNSigAllNodes" SG_ 1219 LFSrrTrkRRate3 1;
BA_ "SignalType" SG_ 1219 LFSrrTrkAzimuth3 "SNM";
BA_ "SignalLongName" SG_ 1219 LFSrrTrkAzimuth3 "Left Front Short Range Radar Track Azimuth 3";
BA_ "VNSigAllNodes" SG_ 1219 LFSrrTrkAzimuth3 1;
BA_ "SignalType" SG_ 1219 LFSrrTrkObjID3 "UNM";
BA_ "SignalLongName" SG_ 1219 LFSrrTrkObjID3 "Left Front Short Range Radar Track Object ID 3";
BA_ "VNSigAllNodes" SG_ 1219 LFSrrTrkObjID3 1;
BA_ "SignalType" SG_ 1219 LFSrrTrkObjElevation3 "ENM";
BA_ "SignalLongName" SG_ 1219 LFSrrTrkObjElevation3 "Left Front Short Range Radar Track Object Elevation 3";
BA_ "VNSigAllNodes" SG_ 1219 LFSrrTrkObjElevation3 1;
BA_ "SignalType" SG_ 1219 LFSrrTrkDynamProp3 "ENM";
BA_ "SignalLongName" SG_ 1219 LFSrrTrkDynamProp3 "Left Front Short Range Radar Track Dynamic Property 3";
BA_ "VNSigAllNodes" SG_ 1219 LFSrrTrkDynamProp3 1;
BA_ "SignalType" SG_ 1219 LFSrrTrkMeasStatus3 "ENM";
BA_ "SignalLongName" SG_ 1219 LFSrrTrkMeasStatus3 "Left Front Short Range Radar Track Measurement Status 3";
BA_ "VNSigAllNodes" SG_ 1219 LFSrrTrkMeasStatus3 1;
BA_ "SignalType" SG_ 1219 LFSrrTrkObsRange3 "SNM";
BA_ "SignalLongName" SG_ 1219 LFSrrTrkObsRange3 "Left Front Short Range Radar Track Observed Range 3";
BA_ "VNSigAllNodes" SG_ 1219 LFSrrTrkObsRange3 1;
BA_ "SignalType" SG_ 1219 LFSrrTrkRawAzimuth3 "SNM";
BA_ "SignalLongName" SG_ 1219 LFSrrTrkRawAzimuth3 "Left Front Short Range Radar Track Raw Azimuth 3";
BA_ "VNSigAllNodes" SG_ 1219 LFSrrTrkRawAzimuth3 1;
BA_ "SignalType" SG_ 1220 LFSrrBurstID4 "UNM";
BA_ "SignalLongName" SG_ 1220 LFSrrBurstID4 "Left Front Short Range Radar Burst ID 4";
BA_ "VNSigAllNodes" SG_ 1220 LFSrrBurstID4 1;
BA_ "SignalType" SG_ 1220 LFSrrTrkRange4 "UNM";
BA_ "SignalLongName" SG_ 1220 LFSrrTrkRange4 "Left Front Short Range Radar Track Range 4";
BA_ "VNSigAllNodes" SG_ 1220 LFSrrTrkRange4 1;
BA_ "SignalType" SG_ 1220 LFSrrTrkRRate4 "SNM";
BA_ "SignalLongName" SG_ 1220 LFSrrTrkRRate4 "Left Front Short Range Radar Track Range Rate 4";
BA_ "VNSigAllNodes" SG_ 1220 LFSrrTrkRRate4 1;
BA_ "SignalType" SG_ 1220 LFSrrTrkObsRange4 "SNM";
BA_ "SignalLongName" SG_ 1220 LFSrrTrkObsRange4 "Left Front Short Range Radar Track Observed Range 4";
BA_ "VNSigAllNodes" SG_ 1220 LFSrrTrkObsRange4 1;
BA_ "SignalType" SG_ 1220 LFSrrTrkAzimuth4 "SNM";
BA_ "SignalLongName" SG_ 1220 LFSrrTrkAzimuth4 "Left Front Short Range Radar Track Azimuth 4";
BA_ "VNSigAllNodes" SG_ 1220 LFSrrTrkAzimuth4 1;
BA_ "SignalType" SG_ 1220 LFSrrTrkObjID4 "UNM";
BA_ "SignalLongName" SG_ 1220 LFSrrTrkObjID4 "Left Front Short Range Radar Track Object ID 4";
BA_ "VNSigAllNodes" SG_ 1220 LFSrrTrkObjID4 1;
BA_ "SignalType" SG_ 1220 LFSrrTrkObjElevation4 "ENM";
BA_ "SignalLongName" SG_ 1220 LFSrrTrkObjElevation4 "Left Front Short Range Radar Track Object Elevation 4";
BA_ "VNSigAllNodes" SG_ 1220 LFSrrTrkObjElevation4 1;
BA_ "SignalType" SG_ 1220 LFSrrTrkDynamProp4 "ENM";
BA_ "SignalLongName" SG_ 1220 LFSrrTrkDynamProp4 "Left Front Short Range Radar Track Dynamic Property 4";
BA_ "VNSigAllNodes" SG_ 1220 LFSrrTrkDynamProp4 1;
BA_ "SignalType" SG_ 1220 LFSrrTrkMeasStatus4 "ENM";
BA_ "SignalLongName" SG_ 1220 LFSrrTrkMeasStatus4 "Left Front Short Range Radar Track Measurement Status 4";
BA_ "VNSigAllNodes" SG_ 1220 LFSrrTrkMeasStatus4 1;
BA_ "SignalType" SG_ 1220 LFSrrTrkRawAzimuth4 "SNM";
BA_ "SignalLongName" SG_ 1220 LFSrrTrkRawAzimuth4 "Left Front Short Range Radar Track Raw Azimuth 4";
BA_ "VNSigAllNodes" SG_ 1220 LFSrrTrkRawAzimuth4 1;
BA_ "SignalType" SG_ 1221 LFSrrTrkObsRange5 "SNM";
BA_ "SignalLongName" SG_ 1221 LFSrrTrkObsRange5 "Left Front Short Range Radar Track Observed Range 5";
BA_ "VNSigAllNodes" SG_ 1221 LFSrrTrkObsRange5 1;
BA_ "SignalType" SG_ 1221 LFSrrBurstID5 "UNM";
BA_ "SignalLongName" SG_ 1221 LFSrrBurstID5 "Left Front Short Range Radar Burst ID 5";
BA_ "VNSigAllNodes" SG_ 1221 LFSrrBurstID5 1;
BA_ "SignalType" SG_ 1221 LFSrrTrkRange5 "UNM";
BA_ "SignalLongName" SG_ 1221 LFSrrTrkRange5 "Left Front Short Range Radar Track Range 5";
BA_ "VNSigAllNodes" SG_ 1221 LFSrrTrkRange5 1;
BA_ "SignalType" SG_ 1221 LFSrrTrkRRate5 "SNM";
BA_ "SignalLongName" SG_ 1221 LFSrrTrkRRate5 "Left Front Short Range Radar Track Range Rate 5";
BA_ "VNSigAllNodes" SG_ 1221 LFSrrTrkRRate5 1;
BA_ "SignalType" SG_ 1221 LFSrrTrkAzimuth5 "SNM";
BA_ "SignalLongName" SG_ 1221 LFSrrTrkAzimuth5 "Left Front Short Range Radar Track Azimuth 5";
BA_ "VNSigAllNodes" SG_ 1221 LFSrrTrkAzimuth5 1;
BA_ "SignalType" SG_ 1221 LFSrrTrkObjID5 "UNM";
BA_ "SignalLongName" SG_ 1221 LFSrrTrkObjID5 "Left Front Short Range Radar Track Object ID 5";
BA_ "VNSigAllNodes" SG_ 1221 LFSrrTrkObjID5 1;
BA_ "SignalType" SG_ 1221 LFSrrTrkObjElevation5 "ENM";
BA_ "SignalLongName" SG_ 1221 LFSrrTrkObjElevation5 "Left Front Short Range Radar Track Object Elevation 5";
BA_ "VNSigAllNodes" SG_ 1221 LFSrrTrkObjElevation5 1;
BA_ "SignalType" SG_ 1221 LFSrrTrkDynamProp5 "ENM";
BA_ "SignalLongName" SG_ 1221 LFSrrTrkDynamProp5 "Left Front Short Range Radar Track Dynamic Property 5";
BA_ "VNSigAllNodes" SG_ 1221 LFSrrTrkDynamProp5 1;
BA_ "SignalType" SG_ 1221 LFSrrTrkMeasStatus5 "ENM";
BA_ "SignalLongName" SG_ 1221 LFSrrTrkMeasStatus5 "Left Front Short Range Radar Track Measurement Status 5";
BA_ "VNSigAllNodes" SG_ 1221 LFSrrTrkMeasStatus5 1;
BA_ "SignalType" SG_ 1221 LFSrrTrkRawAzimuth5 "SNM";
BA_ "SignalLongName" SG_ 1221 LFSrrTrkRawAzimuth5 "Left Front Short Range Radar Track Raw Azimuth 5";
BA_ "VNSigAllNodes" SG_ 1221 LFSrrTrkRawAzimuth5 1;
BA_ "SignalType" SG_ 1222 LFSrrTrkObsRange6 "SNM";
BA_ "SignalLongName" SG_ 1222 LFSrrTrkObsRange6 "Left Front Short Range Radar Track Observed Range 6";
BA_ "VNSigAllNodes" SG_ 1222 LFSrrTrkObsRange6 1;
BA_ "SignalType" SG_ 1222 LFSrrBurstID6 "UNM";
BA_ "SignalLongName" SG_ 1222 LFSrrBurstID6 "Left Front Short Range Radar Burst ID 6";
BA_ "VNSigAllNodes" SG_ 1222 LFSrrBurstID6 1;
BA_ "SignalType" SG_ 1222 LFSrrTrkRange6 "UNM";
BA_ "SignalLongName" SG_ 1222 LFSrrTrkRange6 "Left Front Short Range Radar Track Range 6";
BA_ "VNSigAllNodes" SG_ 1222 LFSrrTrkRange6 1;
BA_ "SignalType" SG_ 1222 LFSrrTrkRRate6 "SNM";
BA_ "SignalLongName" SG_ 1222 LFSrrTrkRRate6 "Left Front Short Range Radar Track Range Rate 6";
BA_ "VNSigAllNodes" SG_ 1222 LFSrrTrkRRate6 1;
BA_ "SignalType" SG_ 1222 LFSrrTrkAzimuth6 "SNM";
BA_ "SignalLongName" SG_ 1222 LFSrrTrkAzimuth6 "Left Front Short Range Radar Track Azimuth 6";
BA_ "VNSigAllNodes" SG_ 1222 LFSrrTrkAzimuth6 1;
BA_ "SignalType" SG_ 1222 LFSrrTrkObjID6 "UNM";
BA_ "SignalLongName" SG_ 1222 LFSrrTrkObjID6 "Left Front Short Range Radar Track Object ID 6";
BA_ "VNSigAllNodes" SG_ 1222 LFSrrTrkObjID6 1;
BA_ "SignalType" SG_ 1222 LFSrrTrkObjElevation6 "ENM";
BA_ "SignalLongName" SG_ 1222 LFSrrTrkObjElevation6 "Left Front Short Range Radar Track Object Elevation 6";
BA_ "VNSigAllNodes" SG_ 1222 LFSrrTrkObjElevation6 1;
BA_ "SignalType" SG_ 1222 LFSrrTrkDynamProp6 "ENM";
BA_ "SignalLongName" SG_ 1222 LFSrrTrkDynamProp6 "Left Front Short Range Radar Track Dynamic Property 6";
BA_ "VNSigAllNodes" SG_ 1222 LFSrrTrkDynamProp6 1;
BA_ "SignalType" SG_ 1222 LFSrrTrkMeasStatus6 "ENM";
BA_ "SignalLongName" SG_ 1222 LFSrrTrkMeasStatus6 "Left Front Short Range Radar Track Measurement Status 6";
BA_ "VNSigAllNodes" SG_ 1222 LFSrrTrkMeasStatus6 1;
BA_ "SignalType" SG_ 1222 LFSrrTrkRawAzimuth6 "SNM";
BA_ "SignalLongName" SG_ 1222 LFSrrTrkRawAzimuth6 "Left Front Short Range Radar Track Raw Azimuth 6";
BA_ "VNSigAllNodes" SG_ 1222 LFSrrTrkRawAzimuth6 1;
BA_ "SignalType" SG_ 1223 LFSrrTrkObsRange7 "SNM";
BA_ "SignalLongName" SG_ 1223 LFSrrTrkObsRange7 "Left Front Short Range Radar Track Observed Range 7";
BA_ "VNSigAllNodes" SG_ 1223 LFSrrTrkObsRange7 1;
BA_ "SignalType" SG_ 1223 LFSrrBurstID7 "UNM";
BA_ "SignalLongName" SG_ 1223 LFSrrBurstID7 "Left Front Short Range Radar Burst ID 7";
BA_ "VNSigAllNodes" SG_ 1223 LFSrrBurstID7 1;
BA_ "SignalType" SG_ 1223 LFSrrTrkRange7 "UNM";
BA_ "SignalLongName" SG_ 1223 LFSrrTrkRange7 "Left Front Short Range Radar Track Range 7";
BA_ "VNSigAllNodes" SG_ 1223 LFSrrTrkRange7 1;
BA_ "SignalType" SG_ 1223 LFSrrTrkRRate7 "SNM";
BA_ "SignalLongName" SG_ 1223 LFSrrTrkRRate7 "Left Front Short Range Radar Track Range Rate 7";
BA_ "VNSigAllNodes" SG_ 1223 LFSrrTrkRRate7 1;
BA_ "SignalType" SG_ 1223 LFSrrTrkAzimuth7 "SNM";
BA_ "SignalLongName" SG_ 1223 LFSrrTrkAzimuth7 "Left Front Short Range Radar Track Azimuth 7";
BA_ "VNSigAllNodes" SG_ 1223 LFSrrTrkAzimuth7 1;
BA_ "SignalType" SG_ 1223 LFSrrTrkObjID7 "UNM";
BA_ "SignalLongName" SG_ 1223 LFSrrTrkObjID7 "Left Front Short Range Radar Track Object ID 7";
BA_ "VNSigAllNodes" SG_ 1223 LFSrrTrkObjID7 1;
BA_ "SignalType" SG_ 1223 LFSrrTrkObjElevation7 "ENM";
BA_ "SignalLongName" SG_ 1223 LFSrrTrkObjElevation7 "Left Front Short Range Radar Track Object Elevation 7";
BA_ "VNSigAllNodes" SG_ 1223 LFSrrTrkObjElevation7 1;
BA_ "SignalType" SG_ 1223 LFSrrTrkDynamProp7 "ENM";
BA_ "SignalLongName" SG_ 1223 LFSrrTrkDynamProp7 "Left Front Short Range Radar Track Dynamic Property 7";
BA_ "VNSigAllNodes" SG_ 1223 LFSrrTrkDynamProp7 1;
BA_ "SignalType" SG_ 1223 LFSrrTrkMeasStatus7 "ENM";
BA_ "SignalLongName" SG_ 1223 LFSrrTrkMeasStatus7 "Left Front Short Range Radar Track Measurement Status 7";
BA_ "VNSigAllNodes" SG_ 1223 LFSrrTrkMeasStatus7 1;
BA_ "SignalType" SG_ 1223 LFSrrTrkRawAzimuth7 "SNM";
BA_ "SignalLongName" SG_ 1223 LFSrrTrkRawAzimuth7 "Left Front Short Range Radar Track Raw Azimuth 7";
BA_ "VNSigAllNodes" SG_ 1223 LFSrrTrkRawAzimuth7 1;
BA_ "SignalType" SG_ 1224 LFSrrTrkObsRange8 "SNM";
BA_ "SignalLongName" SG_ 1224 LFSrrTrkObsRange8 "Left Front Short Range Radar Track Observed Range 8";
BA_ "VNSigAllNodes" SG_ 1224 LFSrrTrkObsRange8 1;
BA_ "SignalType" SG_ 1224 LFSrrBurstID8 "UNM";
BA_ "SignalLongName" SG_ 1224 LFSrrBurstID8 "Left Front Short Range Radar Burst ID 8";
BA_ "VNSigAllNodes" SG_ 1224 LFSrrBurstID8 1;
BA_ "SignalType" SG_ 1224 LFSrrTrkRange8 "UNM";
BA_ "SignalLongName" SG_ 1224 LFSrrTrkRange8 "Left Front Short Range Radar Track Range 8";
BA_ "VNSigAllNodes" SG_ 1224 LFSrrTrkRange8 1;
BA_ "SignalType" SG_ 1224 LFSrrTrkRRate8 "SNM";
BA_ "SignalLongName" SG_ 1224 LFSrrTrkRRate8 "Left Front Short Range Radar Track Range Rate 8";
BA_ "VNSigAllNodes" SG_ 1224 LFSrrTrkRRate8 1;
BA_ "SignalType" SG_ 1224 LFSrrTrkAzimuth8 "SNM";
BA_ "SignalLongName" SG_ 1224 LFSrrTrkAzimuth8 "Left Front Short Range Radar Track Azimuth 8";
BA_ "VNSigAllNodes" SG_ 1224 LFSrrTrkAzimuth8 1;
BA_ "SignalType" SG_ 1224 LFSrrTrkObjID8 "UNM";
BA_ "SignalLongName" SG_ 1224 LFSrrTrkObjID8 "Left Front Short Range Radar Track Object ID 8";
BA_ "VNSigAllNodes" SG_ 1224 LFSrrTrkObjID8 1;
BA_ "SignalType" SG_ 1224 LFSrrTrkObjElevation8 "ENM";
BA_ "SignalLongName" SG_ 1224 LFSrrTrkObjElevation8 "Left Front Short Range Radar Track Object Elevation 8";
BA_ "VNSigAllNodes" SG_ 1224 LFSrrTrkObjElevation8 1;
BA_ "SignalType" SG_ 1224 LFSrrTrkDynamProp8 "ENM";
BA_ "SignalLongName" SG_ 1224 LFSrrTrkDynamProp8 "Left Front Short Range Radar Track Dynamic Property 8";
BA_ "VNSigAllNodes" SG_ 1224 LFSrrTrkDynamProp8 1;
BA_ "SignalType" SG_ 1224 LFSrrTrkMeasStatus8 "ENM";
BA_ "SignalLongName" SG_ 1224 LFSrrTrkMeasStatus8 "Left Front Short Range Radar Track Measurement Status 8";
BA_ "VNSigAllNodes" SG_ 1224 LFSrrTrkMeasStatus8 1;
BA_ "SignalType" SG_ 1224 LFSrrTrkRawAzimuth8 "SNM";
BA_ "SignalLongName" SG_ 1224 LFSrrTrkRawAzimuth8 "Left Front Short Range Radar Track Raw Azimuth 8";
BA_ "VNSigAllNodes" SG_ 1224 LFSrrTrkRawAzimuth8 1;
BA_ "SignalType" SG_ 1225 LFSrrTrkObsRange9 "SNM";
BA_ "SignalLongName" SG_ 1225 LFSrrTrkObsRange9 "Left Front Short Range Radar Track Observed Range 9";
BA_ "VNSigAllNodes" SG_ 1225 LFSrrTrkObsRange9 1;
BA_ "SignalType" SG_ 1225 LFSrrBurstID9 "UNM";
BA_ "SignalLongName" SG_ 1225 LFSrrBurstID9 "Left Front Short Range Radar Burst ID 9";
BA_ "VNSigAllNodes" SG_ 1225 LFSrrBurstID9 1;
BA_ "SignalType" SG_ 1225 LFSrrTrkRange9 "UNM";
BA_ "SignalLongName" SG_ 1225 LFSrrTrkRange9 "Left Front Short Range Radar Track Range 9";
BA_ "VNSigAllNodes" SG_ 1225 LFSrrTrkRange9 1;
BA_ "SignalType" SG_ 1225 LFSrrTrkRRate9 "SNM";
BA_ "SignalLongName" SG_ 1225 LFSrrTrkRRate9 "Left Front Short Range Radar Track Range Rate 9";
BA_ "VNSigAllNodes" SG_ 1225 LFSrrTrkRRate9 1;
BA_ "SignalType" SG_ 1225 LFSrrTrkAzimuth9 "SNM";
BA_ "SignalLongName" SG_ 1225 LFSrrTrkAzimuth9 "Left Front Short Range Radar Track Azimuth 9";
BA_ "VNSigAllNodes" SG_ 1225 LFSrrTrkAzimuth9 1;
BA_ "SignalType" SG_ 1225 LFSrrTrkObjID9 "UNM";
BA_ "SignalLongName" SG_ 1225 LFSrrTrkObjID9 "Left Front Short Range Radar Track Object ID 9";
BA_ "VNSigAllNodes" SG_ 1225 LFSrrTrkObjID9 1;
BA_ "SignalType" SG_ 1225 LFSrrTrkObjElevation9 "ENM";
BA_ "SignalLongName" SG_ 1225 LFSrrTrkObjElevation9 "Left Front Short Range Radar Track Object Elevation 9";
BA_ "VNSigAllNodes" SG_ 1225 LFSrrTrkObjElevation9 1;
BA_ "SignalType" SG_ 1225 LFSrrTrkDynamProp9 "ENM";
BA_ "SignalLongName" SG_ 1225 LFSrrTrkDynamProp9 "Left Front Short Range Radar Track Dynamic Property 9";
BA_ "VNSigAllNodes" SG_ 1225 LFSrrTrkDynamProp9 1;
BA_ "SignalType" SG_ 1225 LFSrrTrkMeasStatus9 "ENM";
BA_ "SignalLongName" SG_ 1225 LFSrrTrkMeasStatus9 "Left Front Short Range Radar Track Measurement Status 9";
BA_ "VNSigAllNodes" SG_ 1225 LFSrrTrkMeasStatus9 1;
BA_ "SignalType" SG_ 1225 LFSrrTrkRawAzimuth9 "SNM";
BA_ "SignalLongName" SG_ 1225 LFSrrTrkRawAzimuth9 "Left Front Short Range Radar Track Raw Azimuth 9";
BA_ "VNSigAllNodes" SG_ 1225 LFSrrTrkRawAzimuth9 1;
BA_ "SignalType" SG_ 1226 LFSrrTrkObsRange10 "SNM";
BA_ "SignalLongName" SG_ 1226 LFSrrTrkObsRange10 "Left Front Short Range Radar Track Observed Range 10";
BA_ "VNSigAllNodes" SG_ 1226 LFSrrTrkObsRange10 1;
BA_ "SignalType" SG_ 1226 LFSrrBurstID10 "UNM";
BA_ "SignalLongName" SG_ 1226 LFSrrBurstID10 "Left Front Short Range Radar Burst ID 10";
BA_ "VNSigAllNodes" SG_ 1226 LFSrrBurstID10 1;
BA_ "SignalType" SG_ 1226 LFSrrTrkRange10 "UNM";
BA_ "SignalLongName" SG_ 1226 LFSrrTrkRange10 "Left Front Short Range Radar Track Range 10";
BA_ "VNSigAllNodes" SG_ 1226 LFSrrTrkRange10 1;
BA_ "SignalType" SG_ 1226 LFSrrTrkRRate10 "SNM";
BA_ "SignalLongName" SG_ 1226 LFSrrTrkRRate10 "Left Front Short Range Radar Track Range Rate 10";
BA_ "VNSigAllNodes" SG_ 1226 LFSrrTrkRRate10 1;
BA_ "SignalType" SG_ 1226 LFSrrTrkAzimuth10 "SNM";
BA_ "SignalLongName" SG_ 1226 LFSrrTrkAzimuth10 "Left Front Short Range Radar Track Azimuth 10";
BA_ "VNSigAllNodes" SG_ 1226 LFSrrTrkAzimuth10 1;
BA_ "SignalType" SG_ 1226 LFSrrTrkObjID10 "UNM";
BA_ "SignalLongName" SG_ 1226 LFSrrTrkObjID10 "Left Front Short Range Radar Track Object ID 10";
BA_ "VNSigAllNodes" SG_ 1226 LFSrrTrkObjID10 1;
BA_ "SignalType" SG_ 1226 LFSrrTrkObjElevation10 "ENM";
BA_ "SignalLongName" SG_ 1226 LFSrrTrkObjElevation10 "Left Front Short Range Radar Track Object Elevation 10";
BA_ "VNSigAllNodes" SG_ 1226 LFSrrTrkObjElevation10 1;
BA_ "SignalType" SG_ 1226 LFSrrTrkDynamProp10 "ENM";
BA_ "SignalLongName" SG_ 1226 LFSrrTrkDynamProp10 "Left Front Short Range Radar Track Dynamic Property 10";
BA_ "VNSigAllNodes" SG_ 1226 LFSrrTrkDynamProp10 1;
BA_ "SignalType" SG_ 1226 LFSrrTrkMeasStatus10 "ENM";
BA_ "SignalLongName" SG_ 1226 LFSrrTrkMeasStatus10 "Left Front Short Range Radar Track Measurement Status 10";
BA_ "VNSigAllNodes" SG_ 1226 LFSrrTrkMeasStatus10 1;
BA_ "SignalType" SG_ 1226 LFSrrTrkRawAzimuth10 "SNM";
BA_ "SignalLongName" SG_ 1226 LFSrrTrkRawAzimuth10 "Left Front Short Range Radar Track Raw Azimuth 10";
BA_ "VNSigAllNodes" SG_ 1226 LFSrrTrkRawAzimuth10 1;
BA_ "SignalType" SG_ 1232 RFSRRVltgOutRngLo "BLN";
BA_ "SignalLongName" SG_ 1232 RFSRRVltgOutRngLo "Right Front Short Range Radar Voltage Out Of Range Low";
BA_ "VNSigAllNodes" SG_ 1232 RFSRRVltgOutRngLo 1;
BA_ "SignalType" SG_ 1232 RFSRRVltgOutRngHi "BLN";
BA_ "SignalLongName" SG_ 1232 RFSRRVltgOutRngHi "Right Front Short Range Radar Voltage out of Range High";
BA_ "VNSigAllNodes" SG_ 1232 RFSRRVltgOutRngHi 1;
BA_ "SignalType" SG_ 1232 RFSRRSvcAlgnInPrcs "BLN";
BA_ "SignalLongName" SG_ 1232 RFSRRSvcAlgnInPrcs "Right Front Short Range Radar Service Alignment in Process";
BA_ "VNSigAllNodes" SG_ 1232 RFSRRSvcAlgnInPrcs 1;
BA_ "SignalType" SG_ 1232 RFSRRSnsrBlckd "BLN";
BA_ "SignalLongName" SG_ 1232 RFSRRSnsrBlckd "Right Front Short Range Radar Sensor Blocked";
BA_ "VNSigAllNodes" SG_ 1232 RFSRRSnsrBlckd 1;
BA_ "SignalType" SG_ 1232 RFSRRSnstvFltPrsntInt "BLN";
BA_ "SignalLongName" SG_ 1232 RFSRRSnstvFltPrsntInt "Right Front Short Range Radar Sensitivity Fault Present, Internal";
BA_ "VNSigAllNodes" SG_ 1232 RFSRRSnstvFltPrsntInt 1;
BA_ "SignalType" SG_ 1232 RFSRRPlntAlgnInProc "BLN";
BA_ "SignalLongName" SG_ 1232 RFSRRPlntAlgnInProc "Right Front Short Range Radar Plant Alignment in Process";
BA_ "VNSigAllNodes" SG_ 1232 RFSRRPlntAlgnInProc 1;
BA_ "SignalType" SG_ 1232 RFSRRMsalgnYawRt "BLN";
BA_ "SignalLongName" SG_ 1232 RFSRRMsalgnYawRt "Right Front Short Range Radar Misalignment Yaw Right";
BA_ "VNSigAllNodes" SG_ 1232 RFSRRMsalgnYawRt 1;
BA_ "SignalType" SG_ 1232 RFSRRMsalgnYawLt "BLN";
BA_ "SignalLongName" SG_ 1232 RFSRRMsalgnYawLt "Right Front Short Range Radar Misalignment Yaw Left";
BA_ "VNSigAllNodes" SG_ 1232 RFSRRMsalgnYawLt 1;
BA_ "SignalType" SG_ 1232 RFSRRMsalgnRllRt "BLN";
BA_ "SignalLongName" SG_ 1232 RFSRRMsalgnRllRt "Right Front Short Range Radar Misalignment Roll Right";
BA_ "VNSigAllNodes" SG_ 1232 RFSRRMsalgnRllRt 1;
BA_ "SignalType" SG_ 1232 RFSRRMsalgnRllLt "BLN";
BA_ "SignalLongName" SG_ 1232 RFSRRMsalgnRllLt "Right Front Short Range Radar Misalignment Roll Left";
BA_ "VNSigAllNodes" SG_ 1232 RFSRRMsalgnRllLt 1;
BA_ "SignalType" SG_ 1232 RFSRRMsalgnPtchUp "BLN";
BA_ "SignalLongName" SG_ 1232 RFSRRMsalgnPtchUp "Right Front Short Range Radar Misalignment Pitch Up";
BA_ "VNSigAllNodes" SG_ 1232 RFSRRMsalgnPtchUp 1;
BA_ "SignalType" SG_ 1232 RFSRRMsalgnPtchDn "BLN";
BA_ "SignalLongName" SG_ 1232 RFSRRMsalgnPtchDn "Right Front Short Range Radar Misalignment Pitch Down";
BA_ "VNSigAllNodes" SG_ 1232 RFSRRMsalgnPtchDn 1;
BA_ "SignalType" SG_ 1232 RFSRRInitDiagCmplt "BLN";
BA_ "SignalLongName" SG_ 1232 RFSRRInitDiagCmplt "Right Front Short Range Radar Initialization Diagnostics Successfully Completed";
BA_ "VNSigAllNodes" SG_ 1232 RFSRRInitDiagCmplt 1;
BA_ "SignalType" SG_ 1232 RFSRRHWFltPrsntInt "BLN";
BA_ "SignalLongName" SG_ 1232 RFSRRHWFltPrsntInt "Right Front Short Range Radar Hardware Fault Present, Internal";
BA_ "VNSigAllNodes" SG_ 1232 RFSRRHWFltPrsntInt 1;
BA_ "SignalType" SG_ 1232 RFSRRExtIntrfrnc "BLN";
BA_ "SignalLongName" SG_ 1232 RFSRRExtIntrfrnc "Right Front Short Range Radar External Interference";
BA_ "VNSigAllNodes" SG_ 1232 RFSRRExtIntrfrnc 1;
BA_ "SignalType" SG_ 1232 RFSRRDiagSpare "BLN";
BA_ "SignalLongName" SG_ 1232 RFSRRDiagSpare "Right Front Short Range Radar Diagnostic Spare";
BA_ "VNSigAllNodes" SG_ 1232 RFSRRDiagSpare 1;
BA_ "SignalType" SG_ 1232 RFSRRCANSgnlSpvFld "BLN";
BA_ "SignalLongName" SG_ 1232 RFSRRCANSgnlSpvFld "Right Front Short Range Radar CAN Signal Supervision Failed";
BA_ "VNSigAllNodes" SG_ 1232 RFSRRCANSgnlSpvFld 1;
BA_ "SignalType" SG_ 1232 RFSRRCANRxErr "BLN";
BA_ "SignalLongName" SG_ 1232 RFSRRCANRxErr "Right Front Short Range Radar CAN Rx Error";
BA_ "VNSigAllNodes" SG_ 1232 RFSRRCANRxErr 1;
BA_ "SignalType" SG_ 1232 RFSRRCANIDAddrsUnsbl "BLN";
BA_ "SignalLongName" SG_ 1232 RFSRRCANIDAddrsUnsbl "Right Front Short Range Radar CAN ID Address Unstable";
BA_ "VNSigAllNodes" SG_ 1232 RFSRRCANIDAddrsUnsbl 1;
BA_ "SignalType" SG_ 1232 RFSRRAntTngFltPrsnt "BLN";
BA_ "SignalLongName" SG_ 1232 RFSRRAntTngFltPrsnt "Right Front Short Range Radar Antenna Tuning Fault Present";
BA_ "VNSigAllNodes" SG_ 1232 RFSRRAntTngFltPrsnt 1;
BA_ "SignalType" SG_ 1232 RFSRRAmbTmpOutRngLw "BLN";
BA_ "SignalLongName" SG_ 1232 RFSRRAmbTmpOutRngLw "Right Front Short Range Radar Ambient Temperature Out of Range Low";
BA_ "VNSigAllNodes" SG_ 1232 RFSRRAmbTmpOutRngLw 1;
BA_ "SignalType" SG_ 1232 RFSRRAmbTmpOutRngHi "BLN";
BA_ "SignalLongName" SG_ 1232 RFSRRAmbTmpOutRngHi "Right Front Short Range Radar Ambient Temperature Out of Range High";
BA_ "VNSigAllNodes" SG_ 1232 RFSRRAmbTmpOutRngHi 1;
BA_ "SignalType" SG_ 1232 RFSRRAlgnFltPrsnt "BLN";
BA_ "SignalLongName" SG_ 1232 RFSRRAlgnFltPrsnt "Right Front Short Range Radar Alignment Fault Present";
BA_ "VNSigAllNodes" SG_ 1232 RFSRRAlgnFltPrsnt 1;
BA_ "SignalType" SG_ 1232 RFSRRNumValidTargets "UNM";
BA_ "SignalLongName" SG_ 1232 RFSRRNumValidTargets "Right Front Short Range Radar Number of Valid Targets";
BA_ "VNSigAllNodes" SG_ 1232 RFSRRNumValidTargets 1;
BA_ "SignalType" SG_ 1232 RFSrrRollingCnt "UNM";
BA_ "SignalLongName" SG_ 1232 RFSrrRollingCnt "Right Front Short Range Radar Rolling Count";
BA_ "VNSigAllNodes" SG_ 1232 RFSrrRollingCnt 1;
BA_ "SignalType" SG_ 1232 RFSRRModeCmdFdbk "ENM";
BA_ "SignalLongName" SG_ 1232 RFSRRModeCmdFdbk "Right Front Short Range Radar Mode Command Feedback";
BA_ "VNSigAllNodes" SG_ 1232 RFSRRModeCmdFdbk 1;
BA_ "SignalType" SG_ 1232 RFSrrTimeStamp "UNM";
BA_ "SignalLongName" SG_ 1232 RFSrrTimeStamp "Right Front Short Range Radar Time Stamp";
BA_ "VNSigAllNodes" SG_ 1232 RFSrrTimeStamp 1;
BA_ "SignalType" SG_ 1232 RFSrrBurstChecksum "UNM";
BA_ "SignalLongName" SG_ 1232 RFSrrBurstChecksum "Right Front Short Range Radar Burst Checksum";
BA_ "VNSigAllNodes" SG_ 1232 RFSrrBurstChecksum 1;
BA_ "SignalType" SG_ 1232 RFSrrTimeStampV "ENM";
BA_ "SignalLongName" SG_ 1232 RFSrrTimeStampV "Right Front Short Range Radar Time Stamp Validity";
BA_ "VNSigAllNodes" SG_ 1232 RFSrrTimeStampV 1;
BA_ "SignalType" SG_ 1233 RFSrrTrkObsRange1 "SNM";
BA_ "SignalLongName" SG_ 1233 RFSrrTrkObsRange1 "Right Front Short Range Radar Track Observed Range 1";
BA_ "VNSigAllNodes" SG_ 1233 RFSrrTrkObsRange1 1;
BA_ "SignalType" SG_ 1233 RFSrrTrkRawAzimuth1 "SNM";
BA_ "SignalLongName" SG_ 1233 RFSrrTrkRawAzimuth1 "Right Front Short Range Radar Track Raw Azimuth 1";
BA_ "VNSigAllNodes" SG_ 1233 RFSrrTrkRawAzimuth1 1;
BA_ "SignalType" SG_ 1233 RFSrrBurstID1 "UNM";
BA_ "SignalLongName" SG_ 1233 RFSrrBurstID1 "Right Front Short Range Radar Burst ID 1";
BA_ "VNSigAllNodes" SG_ 1233 RFSrrBurstID1 1;
BA_ "SignalType" SG_ 1233 RFSrrTrkRange1 "UNM";
BA_ "SignalLongName" SG_ 1233 RFSrrTrkRange1 "Right Front Short Range Radar Track Range 1";
BA_ "VNSigAllNodes" SG_ 1233 RFSrrTrkRange1 1;
BA_ "SignalType" SG_ 1233 RFSrrTrkRRate1 "SNM";
BA_ "SignalLongName" SG_ 1233 RFSrrTrkRRate1 "Right Front Short Range Radar Track Range Rate 1";
BA_ "VNSigAllNodes" SG_ 1233 RFSrrTrkRRate1 1;
BA_ "SignalType" SG_ 1233 RFSrrTrkAzimuth1 "SNM";
BA_ "SignalLongName" SG_ 1233 RFSrrTrkAzimuth1 "Right Front Short Range Radar Track Azimuth 1";
BA_ "VNSigAllNodes" SG_ 1233 RFSrrTrkAzimuth1 1;
BA_ "SignalType" SG_ 1233 RFSrrTrkObjID1 "UNM";
BA_ "SignalLongName" SG_ 1233 RFSrrTrkObjID1 "Right Front Short Range Radar Track Object ID 1";
BA_ "VNSigAllNodes" SG_ 1233 RFSrrTrkObjID1 1;
BA_ "SignalType" SG_ 1233 RFSrrTrkObjElevation1 "ENM";
BA_ "SignalLongName" SG_ 1233 RFSrrTrkObjElevation1 "Right Front Short Range Radar Track Object Elevation 1";
BA_ "VNSigAllNodes" SG_ 1233 RFSrrTrkObjElevation1 1;
BA_ "SignalType" SG_ 1233 RFSrrTrkDynamProp1 "ENM";
BA_ "SignalLongName" SG_ 1233 RFSrrTrkDynamProp1 "Right Front Short Range Radar Track Dynamic Property 1";
BA_ "VNSigAllNodes" SG_ 1233 RFSrrTrkDynamProp1 1;
BA_ "SignalType" SG_ 1233 RFSrrTrkMeasStatus1 "ENM";
BA_ "SignalLongName" SG_ 1233 RFSrrTrkMeasStatus1 "Right Front Short Range Radar Track Measurement Status 1";
BA_ "VNSigAllNodes" SG_ 1233 RFSrrTrkMeasStatus1 1;
BA_ "SignalType" SG_ 1234 RFSrrTrkObsRange2 "SNM";
BA_ "SignalLongName" SG_ 1234 RFSrrTrkObsRange2 "Right Front Short Range Radar Track Observed Range 2";
BA_ "VNSigAllNodes" SG_ 1234 RFSrrTrkObsRange2 1;
BA_ "SignalType" SG_ 1234 RFSrrTrkRawAzimuth2 "SNM";
BA_ "SignalLongName" SG_ 1234 RFSrrTrkRawAzimuth2 "Right Front Short Range Radar Track Raw Azimuth 2";
BA_ "VNSigAllNodes" SG_ 1234 RFSrrTrkRawAzimuth2 1;
BA_ "SignalType" SG_ 1234 RFSrrBurstID2 "UNM";
BA_ "SignalLongName" SG_ 1234 RFSrrBurstID2 "Right Front Short Range Radar Burst ID 2";
BA_ "VNSigAllNodes" SG_ 1234 RFSrrBurstID2 1;
BA_ "SignalType" SG_ 1234 RFSrrTrkRange2 "UNM";
BA_ "SignalLongName" SG_ 1234 RFSrrTrkRange2 "Right Front Short Range Radar Track Range 2";
BA_ "VNSigAllNodes" SG_ 1234 RFSrrTrkRange2 1;
BA_ "SignalType" SG_ 1234 RFSrrTrkRRate2 "SNM";
BA_ "SignalLongName" SG_ 1234 RFSrrTrkRRate2 "Right Front Short Range Radar Track Range Rate 2";
BA_ "VNSigAllNodes" SG_ 1234 RFSrrTrkRRate2 1;
BA_ "SignalType" SG_ 1234 RFSrrTrkAzimuth2 "SNM";
BA_ "SignalLongName" SG_ 1234 RFSrrTrkAzimuth2 "Right Front Short Range Radar Track Azimuth 2";
BA_ "VNSigAllNodes" SG_ 1234 RFSrrTrkAzimuth2 1;
BA_ "SignalType" SG_ 1234 RFSrrTrkObjID2 "UNM";
BA_ "SignalLongName" SG_ 1234 RFSrrTrkObjID2 "Right Front Short Range Radar Track Object ID 2";
BA_ "VNSigAllNodes" SG_ 1234 RFSrrTrkObjID2 1;
BA_ "SignalType" SG_ 1234 RFSrrTrkObjElevation2 "ENM";
BA_ "SignalLongName" SG_ 1234 RFSrrTrkObjElevation2 "Right Front Short Range Radar Track Object Elevation 2";
BA_ "VNSigAllNodes" SG_ 1234 RFSrrTrkObjElevation2 1;
BA_ "SignalType" SG_ 1234 RFSrrTrkDynamProp2 "ENM";
BA_ "SignalLongName" SG_ 1234 RFSrrTrkDynamProp2 "Right Front Short Range Radar Track Dynamic Property 2";
BA_ "VNSigAllNodes" SG_ 1234 RFSrrTrkDynamProp2 1;
BA_ "SignalType" SG_ 1234 RFSrrTrkMeasStatus2 "ENM";
BA_ "SignalLongName" SG_ 1234 RFSrrTrkMeasStatus2 "Right Front Short Range Radar Track Measurement Status 2";
BA_ "VNSigAllNodes" SG_ 1234 RFSrrTrkMeasStatus2 1;
BA_ "SignalType" SG_ 1235 RFSrrTrkObsRange3 "SNM";
BA_ "SignalLongName" SG_ 1235 RFSrrTrkObsRange3 "Right Front Short Range Radar Track Observed Range 3";
BA_ "VNSigAllNodes" SG_ 1235 RFSrrTrkObsRange3 1;
BA_ "SignalType" SG_ 1235 RFSrrTrkRawAzimuth3 "SNM";
BA_ "SignalLongName" SG_ 1235 RFSrrTrkRawAzimuth3 "Right Front Short Range Radar Track Raw Azimuth 3";
BA_ "VNSigAllNodes" SG_ 1235 RFSrrTrkRawAzimuth3 1;
BA_ "SignalType" SG_ 1235 RFSrrBurstID3 "UNM";
BA_ "SignalLongName" SG_ 1235 RFSrrBurstID3 "Right Front Short Range Radar Burst ID 3";
BA_ "VNSigAllNodes" SG_ 1235 RFSrrBurstID3 1;
BA_ "SignalType" SG_ 1235 RFSrrTrkRange3 "UNM";
BA_ "SignalLongName" SG_ 1235 RFSrrTrkRange3 "Right Front Short Range Radar Track Range 3";
BA_ "VNSigAllNodes" SG_ 1235 RFSrrTrkRange3 1;
BA_ "SignalType" SG_ 1235 RFSrrTrkRRate3 "SNM";
BA_ "SignalLongName" SG_ 1235 RFSrrTrkRRate3 "Right Front Short Range Radar Track Range Rate 3";
BA_ "VNSigAllNodes" SG_ 1235 RFSrrTrkRRate3 1;
BA_ "SignalType" SG_ 1235 RFSrrTrkAzimuth3 "SNM";
BA_ "SignalLongName" SG_ 1235 RFSrrTrkAzimuth3 "Right Front Short Range Radar Track Azimuth 3";
BA_ "VNSigAllNodes" SG_ 1235 RFSrrTrkAzimuth3 1;
BA_ "SignalType" SG_ 1235 RFSrrTrkObjID3 "UNM";
BA_ "SignalLongName" SG_ 1235 RFSrrTrkObjID3 "Right Front Short Range Radar Track Object ID 3";
BA_ "VNSigAllNodes" SG_ 1235 RFSrrTrkObjID3 1;
BA_ "SignalType" SG_ 1235 RFSrrTrkObjElevation3 "ENM";
BA_ "SignalLongName" SG_ 1235 RFSrrTrkObjElevation3 "Right Front Short Range Radar Track Object Elevation 3";
BA_ "VNSigAllNodes" SG_ 1235 RFSrrTrkObjElevation3 1;
BA_ "SignalType" SG_ 1235 RFSrrTrkDynamProp3 "ENM";
BA_ "SignalLongName" SG_ 1235 RFSrrTrkDynamProp3 "Right Front Short Range Radar Track Dynamic Property 3";
BA_ "VNSigAllNodes" SG_ 1235 RFSrrTrkDynamProp3 1;
BA_ "SignalType" SG_ 1235 RFSrrTrkMeasStatus3 "ENM";
BA_ "SignalLongName" SG_ 1235 RFSrrTrkMeasStatus3 "Right Front Short Range Radar Track Measurement Status 3";
BA_ "VNSigAllNodes" SG_ 1235 RFSrrTrkMeasStatus3 1;
BA_ "SignalType" SG_ 1236 RFSrrTrkObsRange4 "SNM";
BA_ "SignalLongName" SG_ 1236 RFSrrTrkObsRange4 "Right Front Short Range Radar Track Observed Range 4";
BA_ "VNSigAllNodes" SG_ 1236 RFSrrTrkObsRange4 1;
BA_ "SignalType" SG_ 1236 RFSrrTrkRawAzimuth4 "SNM";
BA_ "SignalLongName" SG_ 1236 RFSrrTrkRawAzimuth4 "Right Front Short Range Radar Track Raw Azimuth 4";
BA_ "VNSigAllNodes" SG_ 1236 RFSrrTrkRawAzimuth4 1;
BA_ "SignalType" SG_ 1236 RFSrrBurstID4 "UNM";
BA_ "SignalLongName" SG_ 1236 RFSrrBurstID4 "Right Front Short Range Radar Burst ID 4";
BA_ "VNSigAllNodes" SG_ 1236 RFSrrBurstID4 1;
BA_ "SignalType" SG_ 1236 RFSrrTrkRange4 "UNM";
BA_ "SignalLongName" SG_ 1236 RFSrrTrkRange4 "Right Front Short Range Radar Track Range 4";
BA_ "VNSigAllNodes" SG_ 1236 RFSrrTrkRange4 1;
BA_ "SignalType" SG_ 1236 RFSrrTrkRRate4 "SNM";
BA_ "SignalLongName" SG_ 1236 RFSrrTrkRRate4 "Right Front Short Range Radar Track Range Rate 4";
BA_ "VNSigAllNodes" SG_ 1236 RFSrrTrkRRate4 1;
BA_ "SignalType" SG_ 1236 RFSrrTrkAzimuth4 "SNM";
BA_ "SignalLongName" SG_ 1236 RFSrrTrkAzimuth4 "Right Front Short Range Radar Track Azimuth 4";
BA_ "VNSigAllNodes" SG_ 1236 RFSrrTrkAzimuth4 1;
BA_ "SignalType" SG_ 1236 RFSrrTrkObjID4 "UNM";
BA_ "SignalLongName" SG_ 1236 RFSrrTrkObjID4 "Right Front Short Range Radar Track Object ID 4";
BA_ "VNSigAllNodes" SG_ 1236 RFSrrTrkObjID4 1;
BA_ "SignalType" SG_ 1236 RFSrrTrkObjElevation4 "ENM";
BA_ "SignalLongName" SG_ 1236 RFSrrTrkObjElevation4 "Right Front Short Range Radar Track Object Elevation 4";
BA_ "VNSigAllNodes" SG_ 1236 RFSrrTrkObjElevation4 1;
BA_ "SignalType" SG_ 1236 RFSrrTrkDynamProp4 "ENM";
BA_ "SignalLongName" SG_ 1236 RFSrrTrkDynamProp4 "Right Front Short Range Radar Track Dynamic Property 4";
BA_ "VNSigAllNodes" SG_ 1236 RFSrrTrkDynamProp4 1;
BA_ "SignalType" SG_ 1236 RFSrrTrkMeasStatus4 "ENM";
BA_ "SignalLongName" SG_ 1236 RFSrrTrkMeasStatus4 "Right Front Short Range Radar Track Measurement Status 4";
BA_ "VNSigAllNodes" SG_ 1236 RFSrrTrkMeasStatus4 1;
BA_ "SignalType" SG_ 1237 RFSrrTrkObsRange5 "SNM";
BA_ "SignalLongName" SG_ 1237 RFSrrTrkObsRange5 "Right Front Short Range Radar Track Observed Range 5";
BA_ "VNSigAllNodes" SG_ 1237 RFSrrTrkObsRange5 1;
BA_ "SignalType" SG_ 1237 RFSrrTrkRawAzimuth5 "SNM";
BA_ "SignalLongName" SG_ 1237 RFSrrTrkRawAzimuth5 "Right Front Short Range Radar Track Raw Azimuth 5";
BA_ "VNSigAllNodes" SG_ 1237 RFSrrTrkRawAzimuth5 1;
BA_ "SignalType" SG_ 1237 RFSrrBurstID5 "UNM";
BA_ "SignalLongName" SG_ 1237 RFSrrBurstID5 "Right Front Short Range Radar Burst ID 5";
BA_ "VNSigAllNodes" SG_ 1237 RFSrrBurstID5 1;
BA_ "SignalType" SG_ 1237 RFSrrTrkRange5 "UNM";
BA_ "SignalLongName" SG_ 1237 RFSrrTrkRange5 "Right Front Short Range Radar Track Range 5";
BA_ "VNSigAllNodes" SG_ 1237 RFSrrTrkRange5 1;
BA_ "SignalType" SG_ 1237 RFSrrTrkRRate5 "SNM";
BA_ "SignalLongName" SG_ 1237 RFSrrTrkRRate5 "Right Front Short Range Radar Track Range Rate 5";
BA_ "VNSigAllNodes" SG_ 1237 RFSrrTrkRRate5 1;
BA_ "SignalType" SG_ 1237 RFSrrTrkAzimuth5 "SNM";
BA_ "SignalLongName" SG_ 1237 RFSrrTrkAzimuth5 "Right Front Short Range Radar Track Azimuth 5";
BA_ "VNSigAllNodes" SG_ 1237 RFSrrTrkAzimuth5 1;
BA_ "SignalType" SG_ 1237 RFSrrTrkObjID5 "UNM";
BA_ "SignalLongName" SG_ 1237 RFSrrTrkObjID5 "Right Front Short Range Radar Track Object ID 5";
BA_ "VNSigAllNodes" SG_ 1237 RFSrrTrkObjID5 1;
BA_ "SignalType" SG_ 1237 RFSrrTrkObjElevation5 "ENM";
BA_ "SignalLongName" SG_ 1237 RFSrrTrkObjElevation5 "Right Front Short Range Radar Track Object Elevation 5";
BA_ "VNSigAllNodes" SG_ 1237 RFSrrTrkObjElevation5 1;
BA_ "SignalType" SG_ 1237 RFSrrTrkDynamProp5 "ENM";
BA_ "SignalLongName" SG_ 1237 RFSrrTrkDynamProp5 "Right Front Short Range Radar Track Dynamic Property 5";
BA_ "VNSigAllNodes" SG_ 1237 RFSrrTrkDynamProp5 1;
BA_ "SignalType" SG_ 1237 RFSrrTrkMeasStatus5 "ENM";
BA_ "SignalLongName" SG_ 1237 RFSrrTrkMeasStatus5 "Right Front Short Range Radar Track Measurement Status 5";
BA_ "VNSigAllNodes" SG_ 1237 RFSrrTrkMeasStatus5 1;
BA_ "SignalType" SG_ 1238 RFSrrTrkObsRange6 "SNM";
BA_ "SignalLongName" SG_ 1238 RFSrrTrkObsRange6 "Right Front Short Range Radar Track Observed Range 6";
BA_ "VNSigAllNodes" SG_ 1238 RFSrrTrkObsRange6 1;
BA_ "SignalType" SG_ 1238 RFSrrTrkRawAzimuth6 "SNM";
BA_ "SignalLongName" SG_ 1238 RFSrrTrkRawAzimuth6 "Right Front Short Range Radar Track Raw Azimuth 6";
BA_ "VNSigAllNodes" SG_ 1238 RFSrrTrkRawAzimuth6 1;
BA_ "SignalType" SG_ 1238 RFSrrBurstID6 "UNM";
BA_ "SignalLongName" SG_ 1238 RFSrrBurstID6 "Right Front Short Range Radar Burst ID 6";
BA_ "VNSigAllNodes" SG_ 1238 RFSrrBurstID6 1;
BA_ "SignalType" SG_ 1238 RFSrrTrkRange6 "UNM";
BA_ "SignalLongName" SG_ 1238 RFSrrTrkRange6 "Right Front Short Range Radar Track Range 6";
BA_ "VNSigAllNodes" SG_ 1238 RFSrrTrkRange6 1;
BA_ "SignalType" SG_ 1238 RFSrrTrkRRate6 "SNM";
BA_ "SignalLongName" SG_ 1238 RFSrrTrkRRate6 "Right Front Short Range Radar Track Range Rate 6";
BA_ "VNSigAllNodes" SG_ 1238 RFSrrTrkRRate6 1;
BA_ "SignalType" SG_ 1238 RFSrrTrkAzimuth6 "SNM";
BA_ "SignalLongName" SG_ 1238 RFSrrTrkAzimuth6 "Right Front Short Range Radar Track Azimuth 6";
BA_ "VNSigAllNodes" SG_ 1238 RFSrrTrkAzimuth6 1;
BA_ "SignalType" SG_ 1238 RFSrrTrkObjID6 "UNM";
BA_ "SignalLongName" SG_ 1238 RFSrrTrkObjID6 "Right Front Short Range Radar Track Object ID 6";
BA_ "VNSigAllNodes" SG_ 1238 RFSrrTrkObjID6 1;
BA_ "SignalType" SG_ 1238 RFSrrTrkObjElevation6 "ENM";
BA_ "SignalLongName" SG_ 1238 RFSrrTrkObjElevation6 "Right Front Short Range Radar Track Object Elevation 6";
BA_ "VNSigAllNodes" SG_ 1238 RFSrrTrkObjElevation6 1;
BA_ "SignalType" SG_ 1238 RFSrrTrkDynamProp6 "ENM";
BA_ "SignalLongName" SG_ 1238 RFSrrTrkDynamProp6 "Right Front Short Range Radar Track Dynamic Property 6";
BA_ "VNSigAllNodes" SG_ 1238 RFSrrTrkDynamProp6 1;
BA_ "SignalType" SG_ 1238 RFSrrTrkMeasStatus6 "ENM";
BA_ "SignalLongName" SG_ 1238 RFSrrTrkMeasStatus6 "Right Front Short Range Radar Track Measurement Status 6";
BA_ "VNSigAllNodes" SG_ 1238 RFSrrTrkMeasStatus6 1;
BA_ "SignalType" SG_ 1239 RFSrrTrkObsRange7 "SNM";
BA_ "SignalLongName" SG_ 1239 RFSrrTrkObsRange7 "Right Front Short Range Radar Track Observed Range 7";
BA_ "VNSigAllNodes" SG_ 1239 RFSrrTrkObsRange7 1;
BA_ "SignalType" SG_ 1239 RFSrrTrkRawAzimuth7 "SNM";
BA_ "SignalLongName" SG_ 1239 RFSrrTrkRawAzimuth7 "Right Front Short Range Radar Track Raw Azimuth 7";
BA_ "VNSigAllNodes" SG_ 1239 RFSrrTrkRawAzimuth7 1;
BA_ "SignalType" SG_ 1239 RFSrrBurstID7 "UNM";
BA_ "SignalLongName" SG_ 1239 RFSrrBurstID7 "Right Front Short Range Radar Burst ID 7";
BA_ "VNSigAllNodes" SG_ 1239 RFSrrBurstID7 1;
BA_ "SignalType" SG_ 1239 RFSrrTrkRange7 "UNM";
BA_ "SignalLongName" SG_ 1239 RFSrrTrkRange7 "Right Front Short Range Radar Track Range 7";
BA_ "VNSigAllNodes" SG_ 1239 RFSrrTrkRange7 1;
BA_ "SignalType" SG_ 1239 RFSrrTrkRRate7 "SNM";
BA_ "SignalLongName" SG_ 1239 RFSrrTrkRRate7 "Right Front Short Range Radar Track Range Rate 7";
BA_ "VNSigAllNodes" SG_ 1239 RFSrrTrkRRate7 1;
BA_ "SignalType" SG_ 1239 RFSrrTrkAzimuth7 "SNM";
BA_ "SignalLongName" SG_ 1239 RFSrrTrkAzimuth7 "Right Front Short Range Radar Track Azimuth 7";
BA_ "VNSigAllNodes" SG_ 1239 RFSrrTrkAzimuth7 1;
BA_ "SignalType" SG_ 1239 RFSrrTrkObjID7 "UNM";
BA_ "SignalLongName" SG_ 1239 RFSrrTrkObjID7 "Right Front Short Range Radar Track Object ID 7";
BA_ "VNSigAllNodes" SG_ 1239 RFSrrTrkObjID7 1;
BA_ "SignalType" SG_ 1239 RFSrrTrkObjElevation7 "ENM";
BA_ "SignalLongName" SG_ 1239 RFSrrTrkObjElevation7 "Right Front Short Range Radar Track Object Elevation 7";
BA_ "VNSigAllNodes" SG_ 1239 RFSrrTrkObjElevation7 1;
BA_ "SignalType" SG_ 1239 RFSrrTrkDynamProp7 "ENM";
BA_ "SignalLongName" SG_ 1239 RFSrrTrkDynamProp7 "Right Front Short Range Radar Track Dynamic Property 7";
BA_ "VNSigAllNodes" SG_ 1239 RFSrrTrkDynamProp7 1;
BA_ "SignalType" SG_ 1239 RFSrrTrkMeasStatus7 "ENM";
BA_ "SignalLongName" SG_ 1239 RFSrrTrkMeasStatus7 "Right Front Short Range Radar Track Measurement Status 7";
BA_ "VNSigAllNodes" SG_ 1239 RFSrrTrkMeasStatus7 1;
BA_ "SignalType" SG_ 1240 RFSrrTrkObsRange8 "SNM";
BA_ "SignalLongName" SG_ 1240 RFSrrTrkObsRange8 "Right Front Short Range Radar Track Observed Range 8";
BA_ "VNSigAllNodes" SG_ 1240 RFSrrTrkObsRange8 1;
BA_ "SignalType" SG_ 1240 RFSrrTrkRawAzimuth8 "SNM";
BA_ "SignalLongName" SG_ 1240 RFSrrTrkRawAzimuth8 "Right Front Short Range Radar Track Raw Azimuth 8";
BA_ "VNSigAllNodes" SG_ 1240 RFSrrTrkRawAzimuth8 1;
BA_ "SignalType" SG_ 1240 RFSrrBurstID8 "UNM";
BA_ "SignalLongName" SG_ 1240 RFSrrBurstID8 "Right Front Short Range Radar Burst ID 8";
BA_ "VNSigAllNodes" SG_ 1240 RFSrrBurstID8 1;
BA_ "SignalType" SG_ 1240 RFSrrTrkRange8 "UNM";
BA_ "SignalLongName" SG_ 1240 RFSrrTrkRange8 "Right Front Short Range Radar Track Range 8";
BA_ "VNSigAllNodes" SG_ 1240 RFSrrTrkRange8 1;
BA_ "SignalType" SG_ 1240 RFSrrTrkRRate8 "SNM";
BA_ "SignalLongName" SG_ 1240 RFSrrTrkRRate8 "Right Front Short Range Radar Track Range Rate 8";
BA_ "VNSigAllNodes" SG_ 1240 RFSrrTrkRRate8 1;
BA_ "SignalType" SG_ 1240 RFSrrTrkAzimuth8 "SNM";
BA_ "SignalLongName" SG_ 1240 RFSrrTrkAzimuth8 "Right Front Short Range Radar Track Azimuth 8";
BA_ "VNSigAllNodes" SG_ 1240 RFSrrTrkAzimuth8 1;
BA_ "SignalType" SG_ 1240 RFSrrTrkObjID8 "UNM";
BA_ "SignalLongName" SG_ 1240 RFSrrTrkObjID8 "Right Front Short Range Radar Track Object ID 8";
BA_ "VNSigAllNodes" SG_ 1240 RFSrrTrkObjID8 1;
BA_ "SignalType" SG_ 1240 RFSrrTrkObjElevation8 "ENM";
BA_ "SignalLongName" SG_ 1240 RFSrrTrkObjElevation8 "Right Front Short Range Radar Track Object Elevation 8";
BA_ "VNSigAllNodes" SG_ 1240 RFSrrTrkObjElevation8 1;
BA_ "SignalType" SG_ 1240 RFSrrTrkDynamProp8 "ENM";
BA_ "SignalLongName" SG_ 1240 RFSrrTrkDynamProp8 "Right Front Short Range Radar Track Dynamic Property 8";
BA_ "VNSigAllNodes" SG_ 1240 RFSrrTrkDynamProp8 1;
BA_ "SignalType" SG_ 1240 RFSrrTrkMeasStatus8 "ENM";
BA_ "SignalLongName" SG_ 1240 RFSrrTrkMeasStatus8 "Right Front Short Range Radar Track Measurement Status 8";
BA_ "VNSigAllNodes" SG_ 1240 RFSrrTrkMeasStatus8 1;
BA_ "SignalType" SG_ 1241 RFSrrTrkObsRange9 "SNM";
BA_ "SignalLongName" SG_ 1241 RFSrrTrkObsRange9 "Right Front Short Range Radar Track Observed Range 9";
BA_ "VNSigAllNodes" SG_ 1241 RFSrrTrkObsRange9 1;
BA_ "SignalType" SG_ 1241 RFSrrTrkRawAzimuth9 "SNM";
BA_ "SignalLongName" SG_ 1241 RFSrrTrkRawAzimuth9 "Right Front Short Range Radar Track Raw Azimuth 9";
BA_ "VNSigAllNodes" SG_ 1241 RFSrrTrkRawAzimuth9 1;
BA_ "SignalType" SG_ 1241 RFSrrBurstID9 "UNM";
BA_ "SignalLongName" SG_ 1241 RFSrrBurstID9 "Right Front Short Range Radar Burst ID 9";
BA_ "VNSigAllNodes" SG_ 1241 RFSrrBurstID9 1;
BA_ "SignalType" SG_ 1241 RFSrrTrkRange9 "UNM";
BA_ "SignalLongName" SG_ 1241 RFSrrTrkRange9 "Right Front Short Range Radar Track Range 9";
BA_ "VNSigAllNodes" SG_ 1241 RFSrrTrkRange9 1;
BA_ "SignalType" SG_ 1241 RFSrrTrkRRate9 "SNM";
BA_ "SignalLongName" SG_ 1241 RFSrrTrkRRate9 "Right Front Short Range Radar Track Range Rate 9";
BA_ "VNSigAllNodes" SG_ 1241 RFSrrTrkRRate9 1;
BA_ "SignalType" SG_ 1241 RFSrrTrkAzimuth9 "SNM";
BA_ "SignalLongName" SG_ 1241 RFSrrTrkAzimuth9 "Right Front Short Range Radar Track Azimuth 9";
BA_ "VNSigAllNodes" SG_ 1241 RFSrrTrkAzimuth9 1;
BA_ "SignalType" SG_ 1241 RFSrrTrkObjID9 "UNM";
BA_ "SignalLongName" SG_ 1241 RFSrrTrkObjID9 "Right Front Short Range Radar Track Object ID 9";
BA_ "VNSigAllNodes" SG_ 1241 RFSrrTrkObjID9 1;
BA_ "SignalType" SG_ 1241 RFSrrTrkObjElevation9 "ENM";
BA_ "SignalLongName" SG_ 1241 RFSrrTrkObjElevation9 "Right Front Short Range Radar Track Object Elevation 9";
BA_ "VNSigAllNodes" SG_ 1241 RFSrrTrkObjElevation9 1;
BA_ "SignalType" SG_ 1241 RFSrrTrkDynamProp9 "ENM";
BA_ "SignalLongName" SG_ 1241 RFSrrTrkDynamProp9 "Right Front Short Range Radar Track Dynamic Property 9";
BA_ "VNSigAllNodes" SG_ 1241 RFSrrTrkDynamProp9 1;
BA_ "SignalType" SG_ 1241 RFSrrTrkMeasStatus9 "ENM";
BA_ "SignalLongName" SG_ 1241 RFSrrTrkMeasStatus9 "Right Front Short Range Radar Track Measurement Status 9";
BA_ "VNSigAllNodes" SG_ 1241 RFSrrTrkMeasStatus9 1;
BA_ "SignalType" SG_ 1242 RFSrrTrkObsRange10 "SNM";
BA_ "SignalLongName" SG_ 1242 RFSrrTrkObsRange10 "Right Front Short Range Radar Track Observed Range 10";
BA_ "VNSigAllNodes" SG_ 1242 RFSrrTrkObsRange10 1;
BA_ "SignalType" SG_ 1242 RFSrrTrkRawAzimuth10 "SNM";
BA_ "SignalLongName" SG_ 1242 RFSrrTrkRawAzimuth10 "Right Front Short Range Radar Track Raw Azimuth 10";
BA_ "VNSigAllNodes" SG_ 1242 RFSrrTrkRawAzimuth10 1;
BA_ "SignalType" SG_ 1242 RFSrrBurstID10 "UNM";
BA_ "SignalLongName" SG_ 1242 RFSrrBurstID10 "Right Front Short Range Radar Burst ID 10";
BA_ "VNSigAllNodes" SG_ 1242 RFSrrBurstID10 1;
BA_ "SignalType" SG_ 1242 RFSrrTrkRange10 "UNM";
BA_ "SignalLongName" SG_ 1242 RFSrrTrkRange10 "Right Front Short Range Radar Track Range 10";
BA_ "VNSigAllNodes" SG_ 1242 RFSrrTrkRange10 1;
BA_ "SignalType" SG_ 1242 RFSrrTrkRRate10 "SNM";
BA_ "SignalLongName" SG_ 1242 RFSrrTrkRRate10 "Right Front Short Range Radar Track Range Rate 10";
BA_ "VNSigAllNodes" SG_ 1242 RFSrrTrkRRate10 1;
BA_ "SignalType" SG_ 1242 RFSrrTrkAzimuth10 "SNM";
BA_ "SignalLongName" SG_ 1242 RFSrrTrkAzimuth10 "Right Front Short Range Radar Track Azimuth 10";
BA_ "VNSigAllNodes" SG_ 1242 RFSrrTrkAzimuth10 1;
BA_ "SignalType" SG_ 1242 RFSrrTrkObjID10 "UNM";
BA_ "SignalLongName" SG_ 1242 RFSrrTrkObjID10 "Right Front Short Range Radar Track Object ID 10";
BA_ "VNSigAllNodes" SG_ 1242 RFSrrTrkObjID10 1;
BA_ "SignalType" SG_ 1242 RFSrrTrkObjElevation10 "ENM";
BA_ "SignalLongName" SG_ 1242 RFSrrTrkObjElevation10 "Right Front Short Range Radar Track Object Elevation 10";
BA_ "VNSigAllNodes" SG_ 1242 RFSrrTrkObjElevation10 1;
BA_ "SignalType" SG_ 1242 RFSrrTrkDynamProp10 "ENM";
BA_ "SignalLongName" SG_ 1242 RFSrrTrkDynamProp10 "Right Front Short Range Radar Track Dynamic Property 10";
BA_ "VNSigAllNodes" SG_ 1242 RFSrrTrkDynamProp10 1;
BA_ "SignalType" SG_ 1242 RFSrrTrkMeasStatus10 "ENM";
BA_ "SignalLongName" SG_ 1242 RFSrrTrkMeasStatus10 "Right Front Short Range Radar Track Measurement Status 10";
BA_ "VNSigAllNodes" SG_ 1242 RFSrrTrkMeasStatus10 1;
BA_ "SignalType" SG_ 1088 FVISVltgOutRngLo "BLN";
BA_ "SignalLongName" SG_ 1088 FVISVltgOutRngLo "Front Vision Voltage Out Of Range Low";
BA_ "VNSigAllNodes" SG_ 1088 FVISVltgOutRngLo 1;
BA_ "SignalType" SG_ 1088 FVISVltgOutRngHi "BLN";
BA_ "SignalLongName" SG_ 1088 FVISVltgOutRngHi "Front Vision Voltage out of Range High";
BA_ "VNSigAllNodes" SG_ 1088 FVISVltgOutRngHi 1;
BA_ "SignalType" SG_ 1088 FVISSvcAlgnInPrcs "BLN";
BA_ "SignalLongName" SG_ 1088 FVISSvcAlgnInPrcs "Front Vision Service Alignment in Process";
BA_ "VNSigAllNodes" SG_ 1088 FVISSvcAlgnInPrcs 1;
BA_ "SignalType" SG_ 1088 FVISSnsrBlckd "BLN";
BA_ "SignalLongName" SG_ 1088 FVISSnsrBlckd "Front Vision Sensor Blocked";
BA_ "VNSigAllNodes" SG_ 1088 FVISSnsrBlckd 1;
BA_ "SignalType" SG_ 1088 FVISSnstvFltPrsntInt "BLN";
BA_ "SignalLongName" SG_ 1088 FVISSnstvFltPrsntInt "Front Vision Sensitivity Fault Present, Internal";
BA_ "VNSigAllNodes" SG_ 1088 FVISSnstvFltPrsntInt 1;
BA_ "SignalType" SG_ 1088 FVISPlntAlgnInProc "BLN";
BA_ "SignalLongName" SG_ 1088 FVISPlntAlgnInProc "Front Vision Plant Alignment in Process";
BA_ "VNSigAllNodes" SG_ 1088 FVISPlntAlgnInProc 1;
BA_ "SignalType" SG_ 1088 FVISMsalgnYawRt "BLN";
BA_ "SignalLongName" SG_ 1088 FVISMsalgnYawRt "Front Vision Misalignment Yaw Right";
BA_ "VNSigAllNodes" SG_ 1088 FVISMsalgnYawRt 1;
BA_ "SignalType" SG_ 1088 FVISMsalgnYawLt "BLN";
BA_ "SignalLongName" SG_ 1088 FVISMsalgnYawLt "Front Vision Misalignment Yaw Left";
BA_ "VNSigAllNodes" SG_ 1088 FVISMsalgnYawLt 1;
BA_ "SignalType" SG_ 1088 FVISMsalgnRllRt "BLN";
BA_ "SignalLongName" SG_ 1088 FVISMsalgnRllRt "Front Vision Misalignment Roll Right";
BA_ "VNSigAllNodes" SG_ 1088 FVISMsalgnRllRt 1;
BA_ "SignalType" SG_ 1088 FVISMsalgnRllLt "BLN";
BA_ "SignalLongName" SG_ 1088 FVISMsalgnRllLt "Front Vision Misalignment Roll Left";
BA_ "VNSigAllNodes" SG_ 1088 FVISMsalgnRllLt 1;
BA_ "SignalType" SG_ 1088 FVISMsalgnPtchUp "BLN";
BA_ "SignalLongName" SG_ 1088 FVISMsalgnPtchUp "Front Vision Misalignment Pitch Up";
BA_ "VNSigAllNodes" SG_ 1088 FVISMsalgnPtchUp 1;
BA_ "SignalType" SG_ 1088 FVISMsalgnPtchDn "BLN";
BA_ "SignalLongName" SG_ 1088 FVISMsalgnPtchDn "Front Vision Misalignment Pitch Down";
BA_ "VNSigAllNodes" SG_ 1088 FVISMsalgnPtchDn 1;
BA_ "SignalType" SG_ 1088 FVISInitDiagCmplt "BLN";
BA_ "SignalLongName" SG_ 1088 FVISInitDiagCmplt "Front Vision Initialization Diagnostics Successfully Completed";
BA_ "VNSigAllNodes" SG_ 1088 FVISInitDiagCmplt 1;
BA_ "SignalType" SG_ 1088 FVISHWFltPrsntInt "BLN";
BA_ "SignalLongName" SG_ 1088 FVISHWFltPrsntInt "Front Vision Hardware Fault Present, Internal";
BA_ "VNSigAllNodes" SG_ 1088 FVISHWFltPrsntInt 1;
BA_ "SignalType" SG_ 1088 FVISExtIntrfrnc "BLN";
BA_ "SignalLongName" SG_ 1088 FVISExtIntrfrnc "Front Vision External Interference";
BA_ "VNSigAllNodes" SG_ 1088 FVISExtIntrfrnc 1;
BA_ "SignalType" SG_ 1088 FVISDiagSpare "BLN";
BA_ "SignalLongName" SG_ 1088 FVISDiagSpare "Front Vision Diagnostic Spare";
BA_ "VNSigAllNodes" SG_ 1088 FVISDiagSpare 1;
BA_ "SignalType" SG_ 1088 FVISCANSgnlSpvFld "BLN";
BA_ "SignalLongName" SG_ 1088 FVISCANSgnlSpvFld "Front Vision CAN Signal Supervision Failed";
BA_ "VNSigAllNodes" SG_ 1088 FVISCANSgnlSpvFld 1;
BA_ "SignalType" SG_ 1088 FVISCANRxErr "BLN";
BA_ "SignalLongName" SG_ 1088 FVISCANRxErr "Front Vision CAN Rx Error";
BA_ "VNSigAllNodes" SG_ 1088 FVISCANRxErr 1;
BA_ "SignalType" SG_ 1088 FVISCANIDAddrsUnsbl "BLN";
BA_ "SignalLongName" SG_ 1088 FVISCANIDAddrsUnsbl "Front Vision CAN ID Address Unstable";
BA_ "VNSigAllNodes" SG_ 1088 FVISCANIDAddrsUnsbl 1;
BA_ "SignalType" SG_ 1088 FVISAntTngFltPrsnt "BLN";
BA_ "SignalLongName" SG_ 1088 FVISAntTngFltPrsnt "Front Vision Antenna Tuning Fault Present";
BA_ "VNSigAllNodes" SG_ 1088 FVISAntTngFltPrsnt 1;
BA_ "SignalType" SG_ 1088 FVISAmbTmpOutRngLw "BLN";
BA_ "SignalLongName" SG_ 1088 FVISAmbTmpOutRngLw "Front Vision Ambient Temperature Out of Range Low";
BA_ "VNSigAllNodes" SG_ 1088 FVISAmbTmpOutRngLw 1;
BA_ "SignalType" SG_ 1088 FVISAmbTmpOutRngHi "BLN";
BA_ "SignalLongName" SG_ 1088 FVISAmbTmpOutRngHi "Front Vision Ambient Temperature Out of Range High";
BA_ "VNSigAllNodes" SG_ 1088 FVISAmbTmpOutRngHi 1;
BA_ "SignalType" SG_ 1088 FVISAlgnFltPrsnt "BLN";
BA_ "SignalLongName" SG_ 1088 FVISAlgnFltPrsnt "Front Vision Alignment Fault Present";
BA_ "VNSigAllNodes" SG_ 1088 FVISAlgnFltPrsnt 1;
BA_ "SignalType" SG_ 1088 FVisionRollingCnt "UNM";
BA_ "SignalLongName" SG_ 1088 FVisionRollingCnt "Front Vision Rolling Count";
BA_ "VNSigAllNodes" SG_ 1088 FVisionRollingCnt 1;
BA_ "SignalType" SG_ 1088 FVISModeCmdFdbk "ENM";
BA_ "SignalLongName" SG_ 1088 FVISModeCmdFdbk "Front Vision Mode Command Feedback";
BA_ "VNSigAllNodes" SG_ 1088 FVISModeCmdFdbk 1;
BA_ "SignalType" SG_ 1088 FVisionNumValidTrgts "UNM";
BA_ "SignalLongName" SG_ 1088 FVisionNumValidTrgts "Front Vision Number of Valid Targets";
BA_ "VNSigAllNodes" SG_ 1088 FVisionNumValidTrgts 1;
BA_ "SignalType" SG_ 1088 FVisionTimeStampV "ENM";
BA_ "SignalLongName" SG_ 1088 FVisionTimeStampV "Front Vision Time Stamp Validity";
BA_ "VNSigAllNodes" SG_ 1088 FVisionTimeStampV 1;
BA_ "SignalType" SG_ 1088 FVisionTimeStamp "UNM";
BA_ "SignalLongName" SG_ 1088 FVisionTimeStamp "Front Vision Time Stamp";
BA_ "VNSigAllNodes" SG_ 1088 FVisionTimeStamp 1;
BA_ "SignalType" SG_ 1088 VISBurstChecksum "UNM";
BA_ "SignalLongName" SG_ 1088 VISBurstChecksum "Front Vision Burst Checksum";
BA_ "VNSigAllNodes" SG_ 1088 VISBurstChecksum 1;
BA_ "SignalType" SG_ 1089 FVisBurstIDTrk1 "UNM";
BA_ "SignalLongName" SG_ 1089 FVisBurstIDTrk1 "Front Vision Burst ID Track 1";
BA_ "VNSigAllNodes" SG_ 1089 FVisBurstIDTrk1 1;
BA_ "SignalType" SG_ 1089 FVisionObjectIDTrk1 "UNM";
BA_ "SignalLongName" SG_ 1089 FVisionObjectIDTrk1 "Forward Vision Object ID Track 1";
BA_ "VNSigAllNodes" SG_ 1089 FVisionObjectIDTrk1 1;
BA_ "SignalType" SG_ 1089 FVisionObjectTypeTrk1 "ENM";
BA_ "SignalLongName" SG_ 1089 FVisionObjectTypeTrk1 "Forward Vision Object Type Track 1";
BA_ "VNSigAllNodes" SG_ 1089 FVisionObjectTypeTrk1 1;
BA_ "SignalType" SG_ 1089 FVisionAzimuthTrk1 "SNM";
BA_ "SignalLongName" SG_ 1089 FVisionAzimuthTrk1 "Forward Vision Azimuth Track 1";
BA_ "VNSigAllNodes" SG_ 1089 FVisionAzimuthTrk1 1;
BA_ "SignalType" SG_ 1089 FVisionRangeTrk1 "UNM";
BA_ "SignalLongName" SG_ 1089 FVisionRangeTrk1 "Forward Vision Range Track 1";
BA_ "GenSigStartValue" SG_ 1089 FVisionRangeTrk1 1;
BA_ "VNSigAllNodes" SG_ 1089 FVisionRangeTrk1 1;
BA_ "SignalType" SG_ 1089 FVisionConfTrk1 "ENM";
BA_ "SignalLongName" SG_ 1089 FVisionConfTrk1 "Forward Vision Confidence Track 1";
BA_ "VNSigAllNodes" SG_ 1089 FVisionConfTrk1 1;
BA_ "SignalType" SG_ 1089 FVisionAzRateTrk1 "SNM";
BA_ "SignalLongName" SG_ 1089 FVisionAzRateTrk1 "Forward Vision Azimuth Rate Track 1";
BA_ "VNSigAllNodes" SG_ 1089 FVisionAzRateTrk1 1;
BA_ "SignalType" SG_ 1089 FVisionRelLaneTrk1 "ENM";
BA_ "SignalLongName" SG_ 1089 FVisionRelLaneTrk1 "Forward Vision Relative Lane Track 1";
BA_ "VNSigAllNodes" SG_ 1089 FVisionRelLaneTrk1 1;
BA_ "SignalType" SG_ 1089 FVisionHeightTrk1 "UNM";
BA_ "SignalLongName" SG_ 1089 FVisionHeightTrk1 "Forward Vision Height Track 1";
BA_ "GenSigStartValue" SG_ 1089 FVisionHeightTrk1 1;
BA_ "VNSigAllNodes" SG_ 1089 FVisionHeightTrk1 1;
BA_ "SignalType" SG_ 1089 FVisionMeasStatTrk1 "ENM";
BA_ "SignalLongName" SG_ 1089 FVisionMeasStatTrk1 "Forward Vision Measurement Status Track 1";
BA_ "VNSigAllNodes" SG_ 1089 FVisionMeasStatTrk1 1;
BA_ "SignalType" SG_ 1089 FVisionWidthTrk1 "UNM";
BA_ "SignalLongName" SG_ 1089 FVisionWidthTrk1 "Forward Vision Width Track 1";
BA_ "GenSigStartValue" SG_ 1089 FVisionWidthTrk1 1;
BA_ "VNSigAllNodes" SG_ 1089 FVisionWidthTrk1 1;
BA_ "SignalType" SG_ 1090 FVisBurstIDTrk2 "UNM";
BA_ "SignalLongName" SG_ 1090 FVisBurstIDTrk2 "Front Vision Burst ID Track 2";
BA_ "VNSigAllNodes" SG_ 1090 FVisBurstIDTrk2 1;
BA_ "SignalType" SG_ 1090 FVisionObjectIDTrk2 "UNM";
BA_ "SignalLongName" SG_ 1090 FVisionObjectIDTrk2 "Forward Vision Object ID Track 2";
BA_ "VNSigAllNodes" SG_ 1090 FVisionObjectIDTrk2 1;
BA_ "SignalType" SG_ 1090 FVisionObjectTypeTrk2 "ENM";
BA_ "SignalLongName" SG_ 1090 FVisionObjectTypeTrk2 "Forward Vision Object Type Track 2";
BA_ "VNSigAllNodes" SG_ 1090 FVisionObjectTypeTrk2 1;
BA_ "SignalType" SG_ 1090 FVisionAzimuthTrk2 "SNM";
BA_ "SignalLongName" SG_ 1090 FVisionAzimuthTrk2 "Forward Vision Azimuth Track 2";
BA_ "VNSigAllNodes" SG_ 1090 FVisionAzimuthTrk2 1;
BA_ "SignalType" SG_ 1090 FVisionRangeTrk2 "UNM";
BA_ "SignalLongName" SG_ 1090 FVisionRangeTrk2 "Forward Vision Range Track 2";
BA_ "GenSigStartValue" SG_ 1090 FVisionRangeTrk2 1;
BA_ "VNSigAllNodes" SG_ 1090 FVisionRangeTrk2 1;
BA_ "SignalType" SG_ 1090 FVisionConfTrk2 "ENM";
BA_ "SignalLongName" SG_ 1090 FVisionConfTrk2 "Forward Vision Confidence Track 2";
BA_ "VNSigAllNodes" SG_ 1090 FVisionConfTrk2 1;
BA_ "SignalType" SG_ 1090 FVisionAzRateTrk2 "SNM";
BA_ "SignalLongName" SG_ 1090 FVisionAzRateTrk2 "Forward Vision Azimuth Rate Track 2";
BA_ "VNSigAllNodes" SG_ 1090 FVisionAzRateTrk2 1;
BA_ "SignalType" SG_ 1090 FVisionRelLaneTrk2 "ENM";
BA_ "SignalLongName" SG_ 1090 FVisionRelLaneTrk2 "Forward Vision Relative Lane Track 2";
BA_ "VNSigAllNodes" SG_ 1090 FVisionRelLaneTrk2 1;
BA_ "SignalType" SG_ 1090 FVisionHeightTrk2 "UNM";
BA_ "SignalLongName" SG_ 1090 FVisionHeightTrk2 "Forward Vision Height Track 2";
BA_ "GenSigStartValue" SG_ 1090 FVisionHeightTrk2 1;
BA_ "VNSigAllNodes" SG_ 1090 FVisionHeightTrk2 1;
BA_ "SignalType" SG_ 1090 FVisionMeasStatTrk2 "ENM";
BA_ "SignalLongName" SG_ 1090 FVisionMeasStatTrk2 "Forward Vision Measurement Status Track 2";
BA_ "VNSigAllNodes" SG_ 1090 FVisionMeasStatTrk2 1;
BA_ "SignalType" SG_ 1090 FVisionWidthTrk2 "UNM";
BA_ "SignalLongName" SG_ 1090 FVisionWidthTrk2 "Forward Vision Width Track 2";
BA_ "GenSigStartValue" SG_ 1090 FVisionWidthTrk2 1;
BA_ "VNSigAllNodes" SG_ 1090 FVisionWidthTrk2 1;
BA_REL_ "GenSigSuprvResp" BU_SG_REL_ EOCM_F_FO SG_ 1184 RSrrRollingCnt 1;
BA_REL_ "GenSigTimeoutMsg" BU_SG_REL_ EOCM_F_FO SG_ 1184 RSrrRollingCnt 1184;
BA_REL_ "GenSigTimeoutTime" BU_SG_REL_ EOCM_F_FO SG_ 1184 RSrrRollingCnt 120;
BA_REL_ "GenSigSuprvResp" BU_SG_REL_ EOCM_F_FO SG_ 1216 LFSrrRollingCnt 1;
BA_REL_ "GenSigTimeoutMsg" BU_SG_REL_ EOCM_F_FO SG_ 1216 LFSrrRollingCnt 1216;
BA_REL_ "GenSigTimeoutTime" BU_SG_REL_ EOCM_F_FO SG_ 1216 LFSrrRollingCnt 120;
BA_REL_ "GenSigSuprvResp" BU_SG_REL_ EOCM_F_FO SG_ 1232 RFSrrRollingCnt 1;
BA_REL_ "GenSigTimeoutMsg" BU_SG_REL_ EOCM_F_FO SG_ 1232 RFSrrRollingCnt 1232;
BA_REL_ "GenSigTimeoutTime" BU_SG_REL_ EOCM_F_FO SG_ 1232 RFSrrRollingCnt 120;
BA_REL_ "GenSigSuprvResp" BU_SG_REL_ EOCM_F_FO SG_ 1088 FVisionRollingCnt 1;
BA_REL_ "GenSigTimeoutMsg" BU_SG_REL_ EOCM_F_FO SG_ 1088 FVisionRollingCnt 1088;
BA_REL_ "GenSigTimeoutTime" BU_SG_REL_ EOCM_F_FO SG_ 1088 FVisionRollingCnt 150;
BA_REL_ "GenSigSuprvResp" BU_SG_REL_ EOCM_F_FO SG_ 1088 FVisionRollingCnt 1;
BA_REL_ "GenSigTimeoutMsg" BU_SG_REL_ EOCM_F_FO SG_ 1088 FVisionRollingCnt 1088;
BA_REL_ "GenSigTimeoutTime" BU_SG_REL_ EOCM_F_FO SG_ 1088 FVisionRollingCnt 150;
BA_REL_ "GenSigVBitResp" BU_SG_REL_ EOCM_F_FO SG_ 1088 FVisionTimeStamp 1;
VAL_ 849 LnSnsLnCrvtrRghtV 1 "Invalid" 0 "Valid" ;
VAL_ 1184 RSRRModeCmdFdbk 5 "Sensing with reduced power" 4 "Undefined" 3 "Radio Silent" 2 "Sensing" 1 "Not Sensing" 0 "Undefined" ;
VAL_ 1184 RSrrTimeStampV 1 "Invalid" 0 "Valid" ;
VAL_ 1184 RSRRSnstvFltPrsntInt 1 "true" 0 "false" ;
VAL_ 1184 RSRRPlntAlgnInProc 1 "true" 0 "false" ;
VAL_ 1184 RSRRMsalgnYawRt 1 "true" 0 "false" ;
VAL_ 1184 RSRRMsalgnYawLt 1 "true" 0 "false" ;
VAL_ 1184 RSRRMsalgnRllRt 1 "true" 0 "false" ;
VAL_ 1184 RSRRMsalgnRllLt 1 "true" 0 "false" ;
VAL_ 1184 RSRRMsalgnPtchUp 1 "true" 0 "false" ;
VAL_ 1184 RSRRMsalgnPtchDn 1 "true" 0 "false" ;
VAL_ 1184 RSRRInitDiagCmplt 1 "true" 0 "false" ;
VAL_ 1184 RSRRHWFltPrsntInt 1 "true" 0 "false" ;
VAL_ 1184 RSRRExtIntrfrnc 1 "true" 0 "false" ;
VAL_ 1184 RSRRDiagSpare 1 "true" 0 "false" ;
VAL_ 1184 RSRRCANSgnlSpvFld 1 "true" 0 "false" ;
VAL_ 1184 RSRRCANRxErr 1 "true" 0 "false" ;
VAL_ 1184 RSRRCANIDAddrsUnsbl 1 "true" 0 "false" ;
VAL_ 1184 RSRRAntTngFltPrsnt 1 "true" 0 "false" ;
VAL_ 1184 RSRRAmbTmpOutRngLw 1 "true" 0 "false" ;
VAL_ 1184 RSRRAmbTmpOutRngHi 1 "true" 0 "false" ;
VAL_ 1184 RSRRAlgnFltPrsnt 1 "true" 0 "false" ;
VAL_ 1184 RSRRVltgOutRngLo 1 "true" 0 "false" ;
VAL_ 1184 RSRRVltgOutRngHi 1 "true" 0 "false" ;
VAL_ 1184 RSRRSvcAlgnInPrcs 1 "true" 0 "false" ;
VAL_ 1184 RSRRSnsrBlckd 1 "true" 0 "false" ;
VAL_ 1185 RSrrTrkObjElevation1 3 "Low " 2 "mid (reserved)" 1 "high " 0 "Unknown" ;
VAL_ 1185 RSrrTrkDynamProp1 4 "Moving in opposite direction" 3 "Moving in same direction as host" 2 "Has moved but currently stopped" 1 "Has never moved" 0 "Unknown" ;
VAL_ 1185 RSrrTrkMeasStatus1 3 "Measured this cycle" 2 "Latent track not detctd this cyc" 1 "New Object" 0 "No Object" ;
VAL_ 1186 RSrrTrkObjElevation2 3 "Low " 2 "mid (reserved)" 1 "high " 0 "Unknown" ;
VAL_ 1186 RSrrTrkDynamProp2 4 "Moving in opposite direction" 3 "Moving in same direction as host" 2 "Has moved but currently stopped" 1 "Has never moved" 0 "Unknown" ;
VAL_ 1186 RSrrTrkMeasStatus2 3 "Measured this cycle" 2 "Latent track not detctd this cyc" 1 "New Object" 0 "No Object" ;
VAL_ 1187 RSrrTrkObjElevation3 3 "Low " 2 "mid (reserved)" 1 "high " 0 "Unknown" ;
VAL_ 1187 RSrrTrkDynamProp3 4 "Moving in opposite direction" 3 "Moving in same direction as host" 2 "Has moved but currently stopped" 1 "Has never moved" 0 "Unknown" ;
VAL_ 1187 RSrrTrkMeasStatus3 3 "Measured this cycle" 2 "Latent track not detctd this cyc" 1 "New Object" 0 "No Object" ;
VAL_ 1188 RSrrTrkObjElevation4 3 "Low " 2 "mid (reserved)" 1 "high " 0 "Unknown" ;
VAL_ 1188 RSrrTrkDynamProp4 4 "Moving in opposite direction" 3 "Moving in same direction as host" 2 "Has moved but currently stopped" 1 "Has never moved" 0 "Unknown" ;
VAL_ 1188 RSrrTrkMeasStatus4 3 "Measured this cycle" 2 "Latent track not detctd this cyc" 1 "New Object" 0 "No Object" ;
VAL_ 1189 RSrrTrkObjElevation5 3 "Low " 2 "mid (reserved)" 1 "high " 0 "Unknown" ;
VAL_ 1189 RSrrTrkDynamProp5 4 "Moving in opposite direction" 3 "Moving in same direction as host" 2 "Has moved but currently stopped" 1 "Has never moved" 0 "Unknown" ;
VAL_ 1189 RSrrTrkMeasStatus5 3 "Measured this cycle" 2 "Latent track not detctd this cyc" 1 "New Object" 0 "No Object" ;
VAL_ 1190 RSrrTrkObjElevation6 3 "Low " 2 "mid (reserved)" 1 "high " 0 "Unknown" ;
VAL_ 1190 RSrrTrkDynamProp6 4 "Moving in opposite direction" 3 "Moving in same direction as host" 2 "Has moved but currently stopped" 1 "Has never moved" 0 "Unknown" ;
VAL_ 1190 RSrrTrkMeasStatus6 3 "Measured this cycle" 2 "Latent track not detctd this cyc" 1 "New Object" 0 "No Object" ;
VAL_ 1191 RSrrTrkObjElevation7 3 "Low " 2 "mid (reserved)" 1 "high " 0 "Unknown" ;
VAL_ 1191 RSrrTrkDynamProp7 4 "Moving in opposite direction" 3 "Moving in same direction as host" 2 "Has moved but currently stopped" 1 "Has never moved" 0 "Unknown" ;
VAL_ 1191 RSrrTrkMeasStatus7 3 "Measured this cycle" 2 "Latent track not detctd this cyc" 1 "New Object" 0 "No Object" ;
VAL_ 1192 RSrrTrkObjElevation8 3 "Low " 2 "mid (reserved)" 1 "high " 0 "Unknown" ;
VAL_ 1192 RSrrTrkDynamProp8 4 "Moving in opposite direction" 3 "Moving in same direction as host" 2 "Has moved but currently stopped" 1 "Has never moved" 0 "Unknown" ;
VAL_ 1192 RSrrTrkMeasStatus8 3 "Measured this cycle" 2 "Latent track not detctd this cyc" 1 "New Object" 0 "No Object" ;
VAL_ 1193 RSrrTrkObjElevation9 3 "Low " 2 "mid (reserved)" 1 "high " 0 "Unknown" ;
VAL_ 1193 RSrrTrkDynamProp9 4 "Moving in opposite direction" 3 "Moving in same direction as host" 2 "Has moved but currently stopped" 1 "Has never moved" 0 "Unknown" ;
VAL_ 1193 RSrrTrkMeasStatus9 3 "Measured this cycle" 2 "Latent track not detctd this cyc" 1 "New Object" 0 "No Object" ;
VAL_ 1194 RSrrTrkObjElevation10 3 "Low " 2 "mid (reserved)" 1 "high " 0 "Unknown" ;
VAL_ 1194 RSrrTrkDynamProp10 4 "Moving in opposite direction" 3 "Moving in same direction as host" 2 "Has moved but currently stopped" 1 "Has never moved" 0 "Unknown" ;
VAL_ 1194 RSrrTrkMeasStatus10 3 "Measured this cycle" 2 "Latent track not detctd this cyc" 1 "New Object" 0 "No Object" ;
VAL_ 1380 RwdFusTrkA4Confidence 3 "confident" 2 "speculative" 1 "highly speculative" 0 "invalid" ;
VAL_ 1380 RwdFusTrkA4MeasStatus 3 "Measured this cycle" 2 "Latent track not detctd this cyc" 1 "New Object" 0 "No Object" ;
VAL_ 1380 RwdFusTrkA4ObjType 7 "no object present" 6 "fixed roadside object" 5 "fixed overhead object" 4 "pedestrian" 3 "motocycle  / bicycle" 2 "Large vehicle (semi)" 1 "4 Wheel Vehicle (car, small trk)" 0 "Unknown" ;
VAL_ 1379 RwdFusTrkA3Confidence 3 "confident" 2 "speculative" 1 "highly speculative" 0 "invalid" ;
VAL_ 1379 RwdFusTrkA3MeasStatus 3 "Measured this cycle" 2 "Latent track not detctd this cyc" 1 "New Object" 0 "No Object" ;
VAL_ 1379 RwdFusTrkA3ObjType 7 "no object present" 6 "fixed roadside object" 5 "fixed overhead object" 4 "pedestrian" 3 "motocycle  / bicycle" 2 "Large vehicle (semi)" 1 "4 Wheel Vehicle (car, small trk)" 0 "Unknown" ;
VAL_ 1378 RwdFusTrkA2Confidence 3 "confident" 2 "speculative" 1 "highly speculative" 0 "invalid" ;
VAL_ 1378 RwdFusTrkA2MeasStatus 3 "Measured this cycle" 2 "Latent track not detctd this cyc" 1 "New Object" 0 "No Object" ;
VAL_ 1378 RwdFusTrkA2ObjType 7 "no object present" 6 "fixed roadside object" 5 "fixed overhead object" 4 "pedestrian" 3 "motocycle  / bicycle" 2 "Large vehicle (semi)" 1 "4 Wheel Vehicle (car, small trk)" 0 "Unknown" ;
VAL_ 1391 RwdFusTrkA15Confidence 3 "confident" 2 "speculative" 1 "highly speculative" 0 "invalid" ;
VAL_ 1391 RwdFusTrkA15MeasStatus 3 "Measured this cycle" 2 "Latent track not detctd this cyc" 1 "New Object" 0 "No Object" ;
VAL_ 1391 RwdFusTrkA15ObjType 7 "no object present" 6 "fixed roadside object" 5 "fixed overhead object" 4 "pedestrian" 3 "motocycle  / bicycle" 2 "Large vehicle (semi)" 1 "4 Wheel Vehicle (car, small trk)" 0 "Unknown" ;
VAL_ 1390 RwdFusTrkA14Confidence 3 "confident" 2 "speculative" 1 "highly speculative" 0 "invalid" ;
VAL_ 1390 RwdFusTrkA14MeasStatus 3 "Measured this cycle" 2 "Latent track not detctd this cyc" 1 "New Object" 0 "No Object" ;
VAL_ 1390 RwdFusTrkA14ObjType 7 "no object present" 6 "fixed roadside object" 5 "fixed overhead object" 4 "pedestrian" 3 "motocycle  / bicycle" 2 "Large vehicle (semi)" 1 "4 Wheel Vehicle (car, small trk)" 0 "Unknown" ;
VAL_ 1389 RwdFusTrkA13Confidence 3 "confident" 2 "speculative" 1 "highly speculative" 0 "invalid" ;
VAL_ 1389 RwdFusTrkA13MeasStatus 3 "Measured this cycle" 2 "Latent track not detctd this cyc" 1 "New Object" 0 "No Object" ;
VAL_ 1389 RwdFusTrkA13ObjType 7 "no object present" 6 "fixed roadside object" 5 "fixed overhead object" 4 "pedestrian" 3 "motocycle  / bicycle" 2 "Large vehicle (semi)" 1 "4 Wheel Vehicle (car, small trk)" 0 "Unknown" ;
VAL_ 1388 RwdFusTrkA12Confidence 3 "confident" 2 "speculative" 1 "highly speculative" 0 "invalid" ;
VAL_ 1388 RwdFusTrkA12MeasStatus 3 "Measured this cycle" 2 "Latent track not detctd this cyc" 1 "New Object" 0 "No Object" ;
VAL_ 1388 RwdFusTrkA12ObjType 7 "no object present" 6 "fixed roadside object" 5 "fixed overhead object" 4 "pedestrian" 3 "motocycle  / bicycle" 2 "Large vehicle (semi)" 1 "4 Wheel Vehicle (car, small trk)" 0 "Unknown" ;
VAL_ 1387 RwdFusTrkA11Confidence 3 "confident" 2 "speculative" 1 "highly speculative" 0 "invalid" ;
VAL_ 1387 RwdFusTrkA11MeasStatus 3 "Measured this cycle" 2 "Latent track not detctd this cyc" 1 "New Object" 0 "No Object" ;
VAL_ 1387 RwdFusTrkA11ObjType 7 "no object present" 6 "fixed roadside object" 5 "fixed overhead object" 4 "pedestrian" 3 "motocycle  / bicycle" 2 "Large vehicle (semi)" 1 "4 Wheel Vehicle (car, small trk)" 0 "Unknown" ;
VAL_ 1386 RwdFusTrkA10MeasStatus 3 "Measured this cycle" 2 "Latent track not detctd this cyc" 1 "New Object" 0 "No Object" ;
VAL_ 1386 RwdFusTrkA10ObjType 7 "no object present" 6 "fixed roadside object" 5 "fixed overhead object" 4 "pedestrian" 3 "motocycle  / bicycle" 2 "Large vehicle (semi)" 1 "4 Wheel Vehicle (car, small trk)" 0 "Unknown" ;
VAL_ 1386 RwdFusTrkA10Confidence 3 "confident" 2 "speculative" 1 "highly speculative" 0 "invalid" ;
VAL_ 1377 RwdFusTrkA1Confidence 3 "confident" 2 "speculative" 1 "highly speculative" 0 "invalid" ;
VAL_ 1377 RwdFusTrkA1MeasStatus 3 "Measured this cycle" 2 "Latent track not detctd this cyc" 1 "New Object" 0 "No Object" ;
VAL_ 1377 RwdFusTrkA1ObjType 7 "no object present" 6 "fixed roadside object" 5 "fixed overhead object" 4 "pedestrian" 3 "motocycle  / bicycle" 2 "Large vehicle (semi)" 1 "4 Wheel Vehicle (car, small trk)" 0 "Unknown" ;
VAL_ 1410 VBAxleTrqRqActv 1 "true" 0 "false" ;
VAL_ 1410 VBBrkRqActv 1 "true" 0 "false" ;
VAL_ 1410 VBBrkCtrlSt 4 "Release Control" 3 "Hold Vehicle" 2 "Apply Brake" 1 "Decrease Torque" 0 "No Action" ;
VAL_ 1410 UpaBrkCtrlSt 4 "Release Control" 3 "Hold Vehicle" 2 "Apply Brake" 1 "Decrease Torque" 0 "No Action" ;
VAL_ 1410 PASysStatus 3 "Failed" 2 "Inhibited" 1 "Enabled" 0 "Disabled" ;
VAL_ 1410 PAWarningSt 15 "Zone 15" 14 "Zone 14" 13 "Zone 13" 12 "Zone 12" 11 "Zone 11" 10 "Zone 10" 9 "Zone 9" 8 "Zone 8" 7 "Zone 7" 6 "Zone 6" 5 "Zone 5" 4 "Zone 4" 3 "Zone 3" 2 "Zone 2" 1 "Zone 1" 0 "No Object" ;
VAL_ 1410 PAFrstDtctWrng 1 "true" 0 "false" ;
VAL_ 1410 BrkPlsRqst 1 "true" 0 "false" ;
VAL_ 1410 BWWarningSt 4 "Vehicle Hold" 3 "Auto Brake" 2 "Imminent Alert" 1 "Caution Alert" 0 "No Alert" ;
VAL_ 1410 BWFrstDtctWrng 1 "true" 0 "false" ;
VAL_ 1216 LFSRRModeCmdFdbk 5 "Sensing with reduced power" 4 "Undefined" 3 "Radio Silent" 2 "Sensing" 1 "Not Sensing" 0 "Undefined" ;
VAL_ 1216 LFSrrTimeStampV 1 "Invalid" 0 "Valid" ;
VAL_ 1216 LFSRRVltgOutRngLo 1 "true" 0 "false" ;
VAL_ 1216 LFSRRVltgOutRngHi 1 "true" 0 "false" ;
VAL_ 1216 LFSRRSvcAlgnInPrcs 1 "true" 0 "false" ;
VAL_ 1216 LFSRRSnsrBlckd 1 "true" 0 "false" ;
VAL_ 1216 LFSRRSnstvFltPrsntInt 1 "true" 0 "false" ;
VAL_ 1216 LFSRRPlntAlgnInProc 1 "true" 0 "false" ;
VAL_ 1216 LFSRRMsalgnYawRt 1 "true" 0 "false" ;
VAL_ 1216 LFSRRMsalgnYawLt 1 "true" 0 "false" ;
VAL_ 1216 LFSRRMsalgnRllRt 1 "true" 0 "false" ;
VAL_ 1216 LFSRRMsalgnRllLt 1 "true" 0 "false" ;
VAL_ 1216 LFSRRMsalgnPtchUp 1 "true" 0 "false" ;
VAL_ 1216 LFSRRMsalgnPtchDn 1 "true" 0 "false" ;
VAL_ 1216 LFSRRInitDiagCmplt 1 "true" 0 "false" ;
VAL_ 1216 LFSRRHWFltPrsntInt 1 "true" 0 "false" ;
VAL_ 1216 LFSRRExtIntrfrnc 1 "true" 0 "false" ;
VAL_ 1216 LFSRRDiagSpare 1 "true" 0 "false" ;
VAL_ 1216 LFSRRCANSgnlSpvFld 1 "true" 0 "false" ;
VAL_ 1216 LFSRRCANRxErr 1 "true" 0 "false" ;
VAL_ 1216 LFSRRCANIDAddrsUnsbl 1 "true" 0 "false" ;
VAL_ 1216 LFSRRAntTngFltPrsnt 1 "true" 0 "false" ;
VAL_ 1216 LFSRRAmbTmpOutRngLw 1 "true" 0 "false" ;
VAL_ 1216 LFSRRAmbTmpOutRngHi 1 "true" 0 "false" ;
VAL_ 1216 LFSRRAlgnFltPrsnt 1 "true" 0 "false" ;
VAL_ 1217 LFSrrTrkObjElevation1 3 "Low " 2 "mid (reserved)" 1 "high " 0 "Unknown" ;
VAL_ 1217 LFSrrTrkDynamProp1 4 "Moving in opposite direction" 3 "Moving in same direction as host" 2 "Has moved but currently stopped" 1 "Has never moved" 0 "Unknown" ;
VAL_ 1217 LFSrrTrkMeasStatus1 3 "Measured this cycle" 2 "Latent track not detctd this cyc" 1 "New Object" 0 "No Object" ;
VAL_ 1218 LFSrrTrkObjElevation2 3 "Low " 2 "mid (reserved)" 1 "high " 0 "Unknown" ;
VAL_ 1218 LFSrrTrkDynamProp2 4 "Moving in opposite direction" 3 "Moving in same direction as host" 2 "Has moved but currently stopped" 1 "Has never moved" 0 "Unknown" ;
VAL_ 1218 LFSrrTrkMeasStatus2 3 "Measured this cycle" 2 "Latent track not detctd this cyc" 1 "New Object" 0 "No Object" ;
VAL_ 1219 LFSrrTrkObjElevation3 3 "Low " 2 "mid (reserved)" 1 "high " 0 "Unknown" ;
VAL_ 1219 LFSrrTrkDynamProp3 4 "Moving in opposite direction" 3 "Moving in same direction as host" 2 "Has moved but currently stopped" 1 "Has never moved" 0 "Unknown" ;
VAL_ 1219 LFSrrTrkMeasStatus3 3 "Measured this cycle" 2 "Latent track not detctd this cyc" 1 "New Object" 0 "No Object" ;
VAL_ 1220 LFSrrTrkObjElevation4 3 "Low " 2 "mid (reserved)" 1 "high " 0 "Unknown" ;
VAL_ 1220 LFSrrTrkDynamProp4 4 "Moving in opposite direction" 3 "Moving in same direction as host" 2 "Has moved but currently stopped" 1 "Has never moved" 0 "Unknown" ;
VAL_ 1220 LFSrrTrkMeasStatus4 3 "Measured this cycle" 2 "Latent track not detctd this cyc" 1 "New Object" 0 "No Object" ;
VAL_ 1221 LFSrrTrkObjElevation5 3 "Low " 2 "mid (reserved)" 1 "high " 0 "Unknown" ;
VAL_ 1221 LFSrrTrkDynamProp5 4 "Moving in opposite direction" 3 "Moving in same direction as host" 2 "Has moved but currently stopped" 1 "Has never moved" 0 "Unknown" ;
VAL_ 1221 LFSrrTrkMeasStatus5 3 "Measured this cycle" 2 "Latent track not detctd this cyc" 1 "New Object" 0 "No Object" ;
VAL_ 1222 LFSrrTrkObjElevation6 3 "Low " 2 "mid (reserved)" 1 "high " 0 "Unknown" ;
VAL_ 1222 LFSrrTrkDynamProp6 4 "Moving in opposite direction" 3 "Moving in same direction as host" 2 "Has moved but currently stopped" 1 "Has never moved" 0 "Unknown" ;
VAL_ 1222 LFSrrTrkMeasStatus6 3 "Measured this cycle" 2 "Latent track not detctd this cyc" 1 "New Object" 0 "No Object" ;
VAL_ 1223 LFSrrTrkObjElevation7 3 "Low " 2 "mid (reserved)" 1 "high " 0 "Unknown" ;
VAL_ 1223 LFSrrTrkDynamProp7 4 "Moving in opposite direction" 3 "Moving in same direction as host" 2 "Has moved but currently stopped" 1 "Has never moved" 0 "Unknown" ;
VAL_ 1223 LFSrrTrkMeasStatus7 3 "Measured this cycle" 2 "Latent track not detctd this cyc" 1 "New Object" 0 "No Object" ;
VAL_ 1224 LFSrrTrkObjElevation8 3 "Low " 2 "mid (reserved)" 1 "high " 0 "Unknown" ;
VAL_ 1224 LFSrrTrkDynamProp8 4 "Moving in opposite direction" 3 "Moving in same direction as host" 2 "Has moved but currently stopped" 1 "Has never moved" 0 "Unknown" ;
VAL_ 1224 LFSrrTrkMeasStatus8 3 "Measured this cycle" 2 "Latent track not detctd this cyc" 1 "New Object" 0 "No Object" ;
VAL_ 1225 LFSrrTrkObjElevation9 3 "Low " 2 "mid (reserved)" 1 "high " 0 "Unknown" ;
VAL_ 1225 LFSrrTrkDynamProp9 4 "Moving in opposite direction" 3 "Moving in same direction as host" 2 "Has moved but currently stopped" 1 "Has never moved" 0 "Unknown" ;
VAL_ 1225 LFSrrTrkMeasStatus9 3 "Measured this cycle" 2 "Latent track not detctd this cyc" 1 "New Object" 0 "No Object" ;
VAL_ 1226 LFSrrTrkObjElevation10 3 "Low " 2 "mid (reserved)" 1 "high " 0 "Unknown" ;
VAL_ 1226 LFSrrTrkDynamProp10 4 "Moving in opposite direction" 3 "Moving in same direction as host" 2 "Has moved but currently stopped" 1 "Has never moved" 0 "Unknown" ;
VAL_ 1226 LFSrrTrkMeasStatus10 3 "Measured this cycle" 2 "Latent track not detctd this cyc" 1 "New Object" 0 "No Object" ;
VAL_ 1232 RFSRRVltgOutRngLo 1 "true" 0 "false" ;
VAL_ 1232 RFSRRVltgOutRngHi 1 "true" 0 "false" ;
VAL_ 1232 RFSRRSvcAlgnInPrcs 1 "true" 0 "false" ;
VAL_ 1232 RFSRRSnsrBlckd 1 "true" 0 "false" ;
VAL_ 1232 RFSRRSnstvFltPrsntInt 1 "true" 0 "false" ;
VAL_ 1232 RFSRRPlntAlgnInProc 1 "true" 0 "false" ;
VAL_ 1232 RFSRRMsalgnYawRt 1 "true" 0 "false" ;
VAL_ 1232 RFSRRMsalgnYawLt 1 "true" 0 "false" ;
VAL_ 1232 RFSRRMsalgnRllRt 1 "true" 0 "false" ;
VAL_ 1232 RFSRRMsalgnRllLt 1 "true" 0 "false" ;
VAL_ 1232 RFSRRMsalgnPtchUp 1 "true" 0 "false" ;
VAL_ 1232 RFSRRMsalgnPtchDn 1 "true" 0 "false" ;
VAL_ 1232 RFSRRInitDiagCmplt 1 "true" 0 "false" ;
VAL_ 1232 RFSRRHWFltPrsntInt 1 "true" 0 "false" ;
VAL_ 1232 RFSRRExtIntrfrnc 1 "true" 0 "false" ;
VAL_ 1232 RFSRRDiagSpare 1 "true" 0 "false" ;
VAL_ 1232 RFSRRCANSgnlSpvFld 1 "true" 0 "false" ;
VAL_ 1232 RFSRRCANRxErr 1 "true" 0 "false" ;
VAL_ 1232 RFSRRCANIDAddrsUnsbl 1 "true" 0 "false" ;
VAL_ 1232 RFSRRAntTngFltPrsnt 1 "true" 0 "false" ;
VAL_ 1232 RFSRRAmbTmpOutRngLw 1 "true" 0 "false" ;
VAL_ 1232 RFSRRAmbTmpOutRngHi 1 "true" 0 "false" ;
VAL_ 1232 RFSRRAlgnFltPrsnt 1 "true" 0 "false" ;
VAL_ 1232 RFSRRModeCmdFdbk 5 "Sensing with reduced power" 4 "Undefined" 3 "Radio Silent" 2 "Sensing" 1 "Not Sensing" 0 "Undefined" ;
VAL_ 1232 RFSrrTimeStampV 1 "Invalid" 0 "Valid" ;
VAL_ 1233 RFSrrTrkObjElevation1 3 "Low " 2 "mid (reserved)" 1 "high " 0 "Unknown" ;
VAL_ 1233 RFSrrTrkDynamProp1 4 "Moving in opposite direction" 3 "Moving in same direction as host" 2 "Has moved but currently stopped" 1 "Has never moved" 0 "Unknown" ;
VAL_ 1233 RFSrrTrkMeasStatus1 3 "Measured this cycle" 2 "Latent track not detctd this cyc" 1 "New Object" 0 "No Object" ;
VAL_ 1234 RFSrrTrkObjElevation2 3 "Low " 2 "mid (reserved)" 1 "high " 0 "Unknown" ;
VAL_ 1234 RFSrrTrkDynamProp2 4 "Moving in opposite direction" 3 "Moving in same direction as host" 2 "Has moved but currently stopped" 1 "Has never moved" 0 "Unknown" ;
VAL_ 1234 RFSrrTrkMeasStatus2 3 "Measured this cycle" 2 "Latent track not detctd this cyc" 1 "New Object" 0 "No Object" ;
VAL_ 1235 RFSrrTrkObjElevation3 3 "Low " 2 "mid (reserved)" 1 "high " 0 "Unknown" ;
VAL_ 1235 RFSrrTrkDynamProp3 4 "Moving in opposite direction" 3 "Moving in same direction as host" 2 "Has moved but currently stopped" 1 "Has never moved" 0 "Unknown" ;
VAL_ 1235 RFSrrTrkMeasStatus3 3 "Measured this cycle" 2 "Latent track not detctd this cyc" 1 "New Object" 0 "No Object" ;
VAL_ 1236 RFSrrTrkObjElevation4 3 "Low " 2 "mid (reserved)" 1 "high " 0 "Unknown" ;
VAL_ 1236 RFSrrTrkDynamProp4 4 "Moving in opposite direction" 3 "Moving in same direction as host" 2 "Has moved but currently stopped" 1 "Has never moved" 0 "Unknown" ;
VAL_ 1236 RFSrrTrkMeasStatus4 3 "Measured this cycle" 2 "Latent track not detctd this cyc" 1 "New Object" 0 "No Object" ;
VAL_ 1237 RFSrrTrkObjElevation5 3 "Low " 2 "mid (reserved)" 1 "high " 0 "Unknown" ;
VAL_ 1237 RFSrrTrkDynamProp5 4 "Moving in opposite direction" 3 "Moving in same direction as host" 2 "Has moved but currently stopped" 1 "Has never moved" 0 "Unknown" ;
VAL_ 1237 RFSrrTrkMeasStatus5 3 "Measured this cycle" 2 "Latent track not detctd this cyc" 1 "New Object" 0 "No Object" ;
VAL_ 1238 RFSrrTrkObjElevation6 3 "Low " 2 "mid (reserved)" 1 "high " 0 "Unknown" ;
VAL_ 1238 RFSrrTrkDynamProp6 4 "Moving in opposite direction" 3 "Moving in same direction as host" 2 "Has moved but currently stopped" 1 "Has never moved" 0 "Unknown" ;
VAL_ 1238 RFSrrTrkMeasStatus6 3 "Measured this cycle" 2 "Latent track not detctd this cyc" 1 "New Object" 0 "No Object" ;
VAL_ 1239 RFSrrTrkObjElevation7 3 "Low " 2 "mid (reserved)" 1 "high " 0 "Unknown" ;
VAL_ 1239 RFSrrTrkDynamProp7 4 "Moving in opposite direction" 3 "Moving in same direction as host" 2 "Has moved but currently stopped" 1 "Has never moved" 0 "Unknown" ;
VAL_ 1239 RFSrrTrkMeasStatus7 3 "Measured this cycle" 2 "Latent track not detctd this cyc" 1 "New Object" 0 "No Object" ;
VAL_ 1240 RFSrrTrkObjElevation8 3 "Low " 2 "mid (reserved)" 1 "high " 0 "Unknown" ;
VAL_ 1240 RFSrrTrkDynamProp8 4 "Moving in opposite direction" 3 "Moving in same direction as host" 2 "Has moved but currently stopped" 1 "Has never moved" 0 "Unknown" ;
VAL_ 1240 RFSrrTrkMeasStatus8 3 "Measured this cycle" 2 "Latent track not detctd this cyc" 1 "New Object" 0 "No Object" ;
VAL_ 1241 RFSrrTrkObjElevation9 3 "Low " 2 "mid (reserved)" 1 "high " 0 "Unknown" ;
VAL_ 1241 RFSrrTrkDynamProp9 4 "Moving in opposite direction" 3 "Moving in same direction as host" 2 "Has moved but currently stopped" 1 "Has never moved" 0 "Unknown" ;
VAL_ 1241 RFSrrTrkMeasStatus9 3 "Measured this cycle" 2 "Latent track not detctd this cyc" 1 "New Object" 0 "No Object" ;
VAL_ 1242 RFSrrTrkObjElevation10 3 "Low " 2 "mid (reserved)" 1 "high " 0 "Unknown" ;
VAL_ 1242 RFSrrTrkDynamProp10 4 "Moving in opposite direction" 3 "Moving in same direction as host" 2 "Has moved but currently stopped" 1 "Has never moved" 0 "Unknown" ;
VAL_ 1242 RFSrrTrkMeasStatus10 3 "Measured this cycle" 2 "Latent track not detctd this cyc" 1 "New Object" 0 "No Object" ;
VAL_ 1088 FVISVltgOutRngLo 1 "true" 0 "false" ;
VAL_ 1088 FVISVltgOutRngHi 1 "true" 0 "false" ;
VAL_ 1088 FVISSvcAlgnInPrcs 1 "true" 0 "false" ;
VAL_ 1088 FVISSnsrBlckd 1 "true" 0 "false" ;
VAL_ 1088 FVISSnstvFltPrsntInt 1 "true" 0 "false" ;
VAL_ 1088 FVISPlntAlgnInProc 1 "true" 0 "false" ;
VAL_ 1088 FVISMsalgnYawRt 1 "true" 0 "false" ;
VAL_ 1088 FVISMsalgnYawLt 1 "true" 0 "false" ;
VAL_ 1088 FVISMsalgnRllRt 1 "true" 0 "false" ;
VAL_ 1088 FVISMsalgnRllLt 1 "true" 0 "false" ;
VAL_ 1088 FVISMsalgnPtchUp 1 "true" 0 "false" ;
VAL_ 1088 FVISMsalgnPtchDn 1 "true" 0 "false" ;
VAL_ 1088 FVISInitDiagCmplt 1 "true" 0 "false" ;
VAL_ 1088 FVISHWFltPrsntInt 1 "true" 0 "false" ;
VAL_ 1088 FVISExtIntrfrnc 1 "true" 0 "false" ;
VAL_ 1088 FVISDiagSpare 1 "true" 0 "false" ;
VAL_ 1088 FVISCANSgnlSpvFld 1 "true" 0 "false" ;
VAL_ 1088 FVISCANRxErr 1 "true" 0 "false" ;
VAL_ 1088 FVISCANIDAddrsUnsbl 1 "true" 0 "false" ;
VAL_ 1088 FVISAntTngFltPrsnt 1 "true" 0 "false" ;
VAL_ 1088 FVISAmbTmpOutRngLw 1 "true" 0 "false" ;
VAL_ 1088 FVISAmbTmpOutRngHi 1 "true" 0 "false" ;
VAL_ 1088 FVISAlgnFltPrsnt 1 "true" 0 "false" ;
VAL_ 1088 FVISModeCmdFdbk 5 "Sensing with reduced power" 4 "Undefined" 3 "Radio Silent" 2 "Sensing" 1 "Not Sensing" 0 "Undefined" ;
VAL_ 1088 FVisionTimeStampV 1 "Invalid" 0 "Valid" ;
VAL_ 1089 FVisionObjectTypeTrk1 7 "no object present" 6 "fixed roadside object" 5 "fixed overhead object" 4 "pedestrian" 3 "motocycle  / bicycle" 2 "Large vehicle (semi)" 1 "4 Wheel Vehicle (car, small trk)" 0 "Unknown" ;
VAL_ 1089 FVisionConfTrk1 3 "confident" 2 "speculative" 1 "highly speculative" 0 "invalid" ;
VAL_ 1089 FVisionRelLaneTrk1 3 "Left Lane" 2 "Right Lane" 1 "Host Lane" 0 "Unknown" ;
VAL_ 1089 FVisionMeasStatTrk1 3 "Measured this cycle" 2 "Latent track not detctd this cyc" 1 "New Object" 0 "No Object" ;
VAL_ 1090 FVisionObjectTypeTrk2 7 "no object present" 6 "fixed roadside object" 5 "fixed overhead object" 4 "pedestrian" 3 "motocycle  / bicycle" 2 "Large vehicle (semi)" 1 "4 Wheel Vehicle (car, small trk)" 0 "Unknown" ;
VAL_ 1090 FVisionConfTrk2 3 "confident" 2 "speculative" 1 "highly speculative" 0 "invalid" ;
VAL_ 1090 FVisionRelLaneTrk2 3 "Left Lane" 2 "Right Lane" 1 "Host Lane" 0 "Unknown" ;
VAL_ 1090 FVisionMeasStatTrk2 3 "Measured this cycle" 2 "Latent track not detctd this cyc" 1 "New Object" 0 "No Object" ;
SIG_GROUP_ 1184 RSRRDiagStatus 1 : RSRRSnstvFltPrsntInt RSRRPlntAlgnInProc RSRRMsalgnYawRt RSRRMsalgnYawLt RSRRMsalgnRllRt RSRRMsalgnRllLt RSRRMsalgnPtchUp RSRRMsalgnPtchDn RSRRInitDiagCmplt RSRRHWFltPrsntInt RSRRExtIntrfrnc RSRRDiagSpare RSRRCANSgnlSpvFld RSRRCANRxErr RSRRCANIDAddrsUnsbl RSRRAntTngFltPrsnt RSRRAmbTmpOutRngLw RSRRAmbTmpOutRngHi RSRRAlgnFltPrsnt RSRRVltgOutRngLo RSRRVltgOutRngHi RSRRSvcAlgnInPrcs RSRRSnsrBlckd;
SIG_GROUP_ 1216 LFSRRDiagStatus 1 : LFSRRVltgOutRngLo LFSRRVltgOutRngHi LFSRRSvcAlgnInPrcs LFSRRSnsrBlckd LFSRRSnstvFltPrsntInt LFSRRPlntAlgnInProc LFSRRMsalgnYawRt LFSRRMsalgnYawLt LFSRRMsalgnRllRt LFSRRMsalgnRllLt LFSRRMsalgnPtchUp LFSRRMsalgnPtchDn LFSRRInitDiagCmplt LFSRRHWFltPrsntInt LFSRRExtIntrfrnc LFSRRDiagSpare LFSRRCANSgnlSpvFld LFSRRCANRxErr LFSRRCANIDAddrsUnsbl LFSRRAntTngFltPrsnt LFSRRAmbTmpOutRngLw LFSRRAmbTmpOutRngHi LFSRRAlgnFltPrsnt;
SIG_GROUP_ 1232 RFSRRDiagStatus 1 : RFSRRVltgOutRngLo RFSRRVltgOutRngHi RFSRRSvcAlgnInPrcs RFSRRSnsrBlckd RFSRRSnstvFltPrsntInt RFSRRPlntAlgnInProc RFSRRMsalgnYawRt RFSRRMsalgnYawLt RFSRRMsalgnRllRt RFSRRMsalgnRllLt RFSRRMsalgnPtchUp RFSRRMsalgnPtchDn RFSRRInitDiagCmplt RFSRRHWFltPrsntInt RFSRRExtIntrfrnc RFSRRDiagSpare RFSRRCANSgnlSpvFld RFSRRCANRxErr RFSRRCANIDAddrsUnsbl RFSRRAntTngFltPrsnt RFSRRAmbTmpOutRngLw RFSRRAmbTmpOutRngHi RFSRRAlgnFltPrsnt;
SIG_GROUP_ 1088 FVISDiagStatus 1 : FVISVltgOutRngLo FVISVltgOutRngHi FVISSvcAlgnInPrcs FVISSnsrBlckd FVISSnstvFltPrsntInt FVISPlntAlgnInProc FVISMsalgnYawRt FVISMsalgnYawLt FVISMsalgnRllRt FVISMsalgnRllLt FVISMsalgnPtchUp FVISMsalgnPtchDn FVISInitDiagCmplt FVISHWFltPrsntInt FVISExtIntrfrnc FVISDiagSpare FVISCANSgnlSpvFld FVISCANRxErr FVISCANIDAddrsUnsbl FVISAntTngFltPrsnt FVISAmbTmpOutRngLw FVISAmbTmpOutRngHi FVISAlgnFltPrsnt;
